VERSION "10.9.1"

NS_ :

BS_:

BU_: ADAS_Info AMP CPD DUMMY_DEBUG DUMMY_ECU EASC HUD MHU XGW_Info

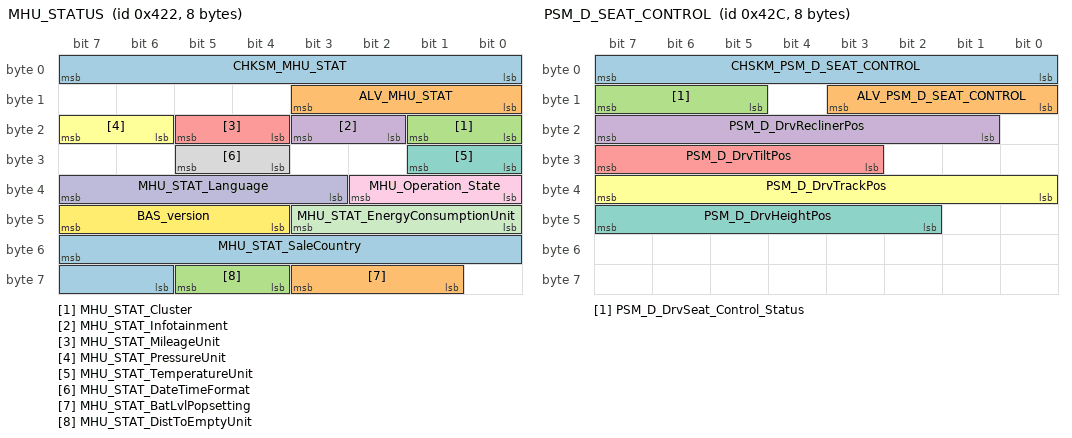
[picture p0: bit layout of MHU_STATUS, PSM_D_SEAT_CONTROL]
BO_ 1058 MHU_STATUS: 8 MHU
  SG_ CHKSM_MHU_STAT : 7|8@0+ (1,0) [0|255] "" ADAS_Info,HUD,XGW_Info
  SG_ ALV_MHU_STAT : 11|4@0+ (1,0) [0|14] "" ADAS_Info,HUD,XGW_Info
  SG_ MHU_STAT_Cluster : 17|2@0+ (1,0) [0|3] "-" ADAS_Info,HUD,XGW_Info
  SG_ MHU_STAT_Infotainment : 19|2@0+ (1,0) [0|3] "" ADAS_Info,HUD,XGW_Info
  SG_ MHU_STAT_MileageUnit : 21|2@0+ (1,0) [0|3] "" ADAS_Info,HUD,XGW_Info
  SG_ MHU_STAT_PressureUnit : 23|2@0+ (1,0) [0|3] "-" HUD,XGW_Info
  SG_ MHU_STAT_TemperatureUnit : 25|2@0+ (1,0) [0|3] "-" HUD,XGW_Info
  SG_ MHU_STAT_DateTimeFormat : 29|2@0+ (1,0) [0|3] "-" HUD,XGW_Info
  SG_ MHU_Operation_State : 34|3@0+ (1,0) [0|7] "" ADAS_Info,HUD,XGW_Info
  SG_ MHU_STAT_Language : 39|5@0+ (1,0) [0|31] "-" HUD,XGW_Info
  SG_ MHU_STAT_EnergyConsumptionUnit : 43|4@0+ (1,0) [0|15] "-" ADAS_Info,HUD,XGW_Info
  SG_ BAS_version : 47|4@0+ (1,0) [0|15] "" XGW_Info
  SG_ MHU_STAT_SaleCountry : 55|10@0+ (1,0) [0|1023] "-" ADAS_Info,HUD,XGW_Info
  SG_ MHU_STAT_BatLvlPopsetting : 59|3@0+ (1,0) [0|7] "-" HUD
  SG_ MHU_STAT_DistToEmptyUnit : 61|2@0+ (1,0) [0|3] "-" HUD

BO_ 1059 AVAS_STATUS: 8 XGW_Info
  SG_ AVAS_BatteryUnderVoltage : 0|1@0+ (1,0) [0|1] "-" MHU
  SG_ AVAS_BatteryOverVoltage : 1|1@0+ (1,0) [0|1] "-" MHU
  SG_ AVAS_VINInfoNotPrgm : 2|1@0+ (1,0) [0|1] "" MHU
  SG_ AVAS_AMPVoltSplDrvOperationFail : 3|1@0+ (1,0) [0|1] "-" MHU
  SG_ AVAS_AMPIntFaultOverCurr : 4|1@0+ (1,0) [0|1] "" MHU
  SG_ AVAS_AMPInternalFaultDCError : 5|1@0+ (1,0) [0|1] "" MHU
  SG_ AVAS_AMPInternalFaultOverTemp : 6|1@0+ (1,0) [0|1] "" MHU
  SG_ AVAS_AMPInternalFaultClockError : 7|1@0+ (1,0) [0|1] "-" MHU
  SG_ AVAS_SpkrMntPwrSwDrvHighFlt : 8|1@0+ (1,0) [0|1] "-" MHU
  SG_ AVAS_SpkrMntPwrSwDrvLowFlt : 9|1@0+ (1,0) [0|1] "-" MHU
  SG_ AVAS_InternalSpeakerOpen : 10|1@0+ (1,0) [0|1] "" MHU
  SG_ AVAS_ECUMalFlshOperationErr : 11|1@0+ (1,0) [0|1] "" MHU
  SG_ AVAS_ECUMalfunctionRamFailure : 12|1@0+ (1,0) [0|1] "-" MHU
  SG_ AVAS_ECUMalEEPROMFailure : 13|1@0+ (1,0) [0|1] "" MHU
  SG_ AVAS_CANBusOff : 14|1@0+ (1,0) [0|1] "-" MHU
  SG_ AVAS_LossCommVehicleSpeed : 15|1@0+ (1,0) [0|1] "" MHU
  SG_ AVAS_LossCommGearPosition : 16|1@0+ (1,0) [0|1] "-" MHU
  SG_ AVAS_LossCommAVASCloseCmd : 17|1@0+ (1,0) [0|1] "-" MHU

BO_ 1068 PSM_D_SEAT_CONTROL: 8 XGW_Info
  SG_ CHSKM_PSM_D_SEAT_CONTROL : 7|8@0+ (1,0) [0|255] "" MHU
  SG_ ALV_PSM_D_SEAT_CONTROL : 11|4@0+ (1,0) [0|14] "" MHU
  SG_ PSM_D_DrvSeat_Control_Status : 15|3@0+ (1,0) [0|7] "" MHU
  SG_ PSM_D_DrvReclinerPos : 23|7@0+ (1,0) [0|127] "degree" MHU
  SG_ PSM_D_DrvTiltPos : 31|5@0+ (1,0) [0|31] "mm" MHU
  SG_ PSM_D_DrvTrackPos : 39|8@0+ (1,0) [0|255] "mm" MHU
  SG_ PSM_D_DrvHeightPos : 47|6@0+ (1,0) [0|63] "mm" MHU

BO_ 1069 XGW_Info_Collect: 3 XGW_Info
  SG_ XGW_WasherFluid_LevelSwitch : 1|2@0+ (1,0) [0|3] "Bit" MHU

BO_ 1070 XGW_HCMInfo: 5 XGW_Info
  SG_ CHKSM_XGW_HCMInfo : 7|8@0+ (1,0) [0|255] "" MHU
  SG_ ALV_XGW_HCMInfo : 11|4@0+ (1,0) [0|14] "" MHU
  SG_ XGW_HLVerLvlMode : 13|2@0+ (1,0) [0|3] "-" MHU
  SG_ XGW_AutoHeadlamp_LvlSts : 15|2@0+ (1,0) [0|3] "-" MHU

BO_ 1073 HUD_ECU_Status: 2 HUD
  SG_ HUD_ECU_Check : 7|8@0+ (1,0) [0|255] "-" XGW_Info
  SG_ HUD_ECU_Fault : 15|8@0+ (1,0) [0|255] "-" XGW_Info

BO_ 1074 MHU_FOTA_STATUS: 8 MHU
  SG_ MHU_FOTA_Checksum : 7|8@0+ (1,0) [0|255] "" AMP,CPD,EASC,HUD,XGW_Info
  SG_ MHU_FOTA_Alive_Counter : 11|4@0+ (1,0) [0|14] "" AMP,CPD,EASC,HUD,XGW_Info
  SG_ MHU_FOTA_State : 15|4@0+ (1,0) [0|14] "-" AMP,CPD,EASC,HUD,XGW_Info
  SG_ MHU_FOTA_Error_Code : 23|8@0+ (1,0) [0|255] "-" AMP,CPD,EASC,HUD,XGW_Info

BO_ 1075 MHU_HEADLAMP_CTL: 2 MHU
  SG_ MHU_Headlamp_Chksm : 7|8@0+ (1,0) [0|255] "-" XGW_Info
  SG_ MHU_Headlamp_Aliv : 11|4@0+ (1,0) [0|14] "-" XGW_Info
  SG_ MHU_HLVerLvlMode : 15|2@0+ (1,0) [0|3] "-" XGW_Info

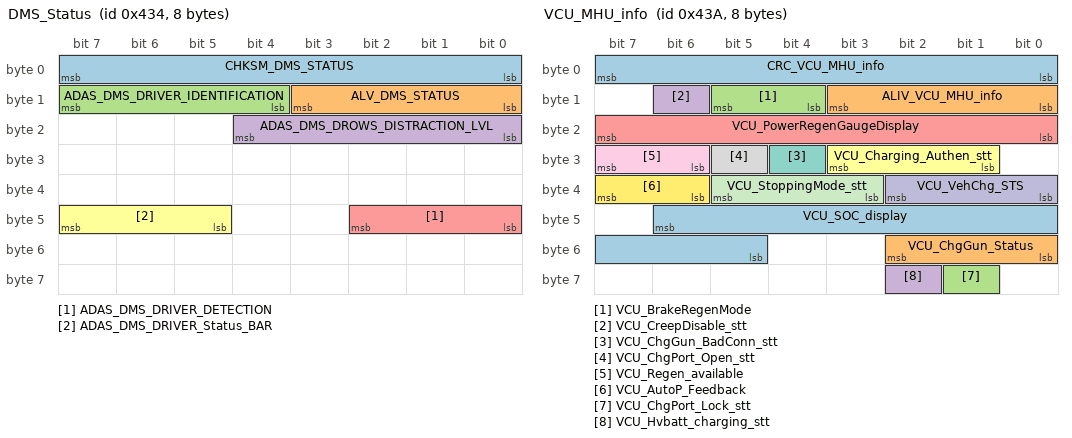
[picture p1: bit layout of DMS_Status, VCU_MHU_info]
BO_ 1076 DMS_Status: 8 ADAS_Info
  SG_ CHKSM_DMS_STATUS : 7|8@0+ (1,0) [0|255] "" HUD,MHU
  SG_ ALV_DMS_STATUS : 11|4@0+ (1,0) [0|14] "" HUD,MHU
  SG_ ADAS_DMS_DRIVER_IDENTIFICATION : 15|4@0+ (1,0) [0|15] "-" HUD,MHU
  SG_ ADAS_DMS_DROWS_DISTRACTION_LVL : 20|5@0+ (1,0) [0|31] "-" HUD,MHU
  SG_ ADAS_DMS_DRIVER_DETECTION : 42|3@0+ (1,0) [0|7] "-" HUD,MHU
  SG_ ADAS_DMS_DRIVER_Status_BAR : 47|3@0+ (1,0) [0|7] "Bit" HUD,MHU

BO_ 1077 BCM_SCM_LIN_Info: 1 XGW_Info
  SG_ BCM_SCM_BC_Button : 1|2@0+ (1,0) [0|3] "-" HUD,MHU

BO_ 1078 MHU_HUD_Info_1: 5 MHU
  SG_ MHU_TELStatus : 2|3@0+ (1,0) [0|7] "-" HUD
  SG_ MHU_MUTEStatus : 4|2@0+ (1,0) [0|3] "-" HUD
  SG_ MHU_TEL_source : 7|3@0+ (1,0) [0|7] "-" HUD
  SG_ SECCAN_HUD_info : 39|8@0+ (1,0) [0|255] "" HUD

BO_ 1079 VCU_MHU_info_2: 8 XGW_Info
  SG_ CRC_VCU_MHU_info_2 : 7|8@0+ (1,0) [0|255] "" MHU
  SG_ ALIV_VCU_MHU_info_2 : 11|4@0+ (1,0) [0|14] "" MHU
  SG_ VCU_Instant_ConsumEnergy : 24|10@0+ (0.1,0) [0|100] "kWh/100km" MHU
  SG_ VCU_Average_ConsumEnergy : 52|10@0+ (0.1,0) [0|100] "kWh/100km" MHU

BO_ 1080 EDS_Error_FR_A: 8 XGW_Info
  SG_ CHKSM_EDS_Error_FR_A : 7|8@0+ (1,0) [0|255] "" MHU
  SG_ ALV_EDS_Error_FR_A : 11|4@0+ (1,0) [0|14] "" MHU
  SG_ EDS_FailNum_ERR_FWD : 23|8@0+ (1,0) [0|255] "" MHU
  SG_ EDS_FailGrade_ERR_FWD : 26|3@0+ (1,0) [0|7] "" MHU
  SG_ EDS_MotOverTempAlarm_FWD : 27|1@0+ (1,0) [0|1] "" MHU
  SG_ EDS_MotOverTempFault_FWD : 28|1@0+ (1,0) [0|1] "" MHU
  SG_ EDS_MotTempSenFault_FWD : 29|1@0+ (1,0) [0|1] "" MHU
  SG_ EDS_EDSOverTempUFault_FWD : 30|1@0+ (1,0) [0|1] "" MHU
  SG_ EDS_EDSOverTempVFault_FWD : 31|1@0+ (1,0) [0|1] "" MHU
  SG_ EDS_EDSOverTempWFault_FWD : 32|1@0+ (1,0) [0|1] "" MHU
  SG_ EDS_EDSOverTempAlarm_FWD : 33|1@0+ (1,0) [0|1] "" MHU
  SG_ EDS_TCoolantOvHi_FWD : 34|1@0+ (1,0) [0|1] "" MHU
  SG_ EDS_EDSTempCmpAlarm_FWD : 35|1@0+ (1,0) [0|1] "" MHU
  SG_ EDS_EDSPhaOvCurentHWFault_FWD : 36|1@0+ (1,0) [0|1] "" MHU
  SG_ EDS_EDSphaOffCalFault_FWD : 37|1@0+ (1,0) [0|1] "" MHU
  SG_ EDS_EDSOverIdcLnkAlarm_FWD : 38|1@0+ (1,0) [0|1] "" MHU
  SG_ EDS_EDSHVOverVoltageAlarm_FWD : 39|1@0+ (1,0) [0|1] "" MHU
  SG_ EDS_EDSHVOverVoltageFault_FWD : 40|1@0+ (1,0) [0|1] "" MHU
  SG_ EDS_EDSHVUnderVoltageAlarm_FWD : 41|1@0+ (1,0) [0|1] "" MHU
  SG_ EDS_EDSHVUnderVoltageFault_FWD : 42|1@0+ (1,0) [0|1] "" MHU
  SG_ EDS_RunToDischaErr_FWD : 43|1@0+ (1,0) [0|1] "" MHU
  SG_ EDS_12VOverVoltageAlarm_FWD : 44|1@0+ (1,0) [0|1] "" MHU
  SG_ EDS_12VUnderVoltageAlarm_FWD : 45|1@0+ (1,0) [0|1] "" MHU
  SG_ EDS_MotOverAlarm_FWD : 46|1@0+ (1,0) [0|1] "" MHU
  SG_ EDS_MotOverFault_FWD : 47|1@0+ (1,0) [0|1] "" MHU
  SG_ EDS_ResolverOffsetAngle_FWD : 48|1@0+ (1,0) [0|1] "" MHU
  SG_ SECCAN_EDS_Error_FR_A : 63|8@0+ (1,0) [0|255] "" MHU

BO_ 1081 EDS_Error_RR_A: 8 XGW_Info
  SG_ CHKSM_EDS_Error_RR_A : 7|8@0+ (1,0) [0|255] "" MHU
  SG_ ALV_EDS_Error_RR_A : 11|4@0+ (1,0) [0|14] "" MHU
  SG_ EDS_FailNum_ERR_RWD : 23|8@0+ (1,0) [0|255] "" MHU
  SG_ EDS_FailGrade_ERR_RWD : 26|3@0+ (1,0) [0|7] "" MHU
  SG_ EDS_MotOverTempAlarm_RWD : 27|1@0+ (1,0) [0|1] "" MHU
  SG_ EDS_MotOverTempFault_RWD : 28|1@0+ (1,0) [0|1] "" MHU
  SG_ EDS_MotTempSenFault_RWD : 29|1@0+ (1,0) [0|1] "" MHU
  SG_ EDS_EDSOverTempUFault_RWD : 30|1@0+ (1,0) [0|1] "" MHU
  SG_ EDS_EDSOverTempVFault_RWD : 31|1@0+ (1,0) [0|1] "" MHU
  SG_ EDS_EDSOverTempWFault_RWD : 32|1@0+ (1,0) [0|1] "" MHU
  SG_ EDS_EDSOverTempAlarm_RWD : 33|1@0+ (1,0) [0|1] "" MHU
  SG_ EDS_TCoolantOvHi_RWD : 34|1@0+ (1,0) [0|1] "" MHU
  SG_ EDS_EDSTempCmpAlarm_RWD : 35|1@0+ (1,0) [0|1] "" MHU
  SG_ EDS_EDSPhaOvCurentHWFault_RWD : 36|1@0+ (1,0) [0|1] "" MHU
  SG_ EDS_EDSphaOffCalFault_RWD : 37|1@0+ (1,0) [0|1] "" MHU
  SG_ EDS_EDSOverIdcLnkAlarm_RWD : 38|1@0+ (1,0) [0|1] "" MHU
  SG_ EDS_EDSHVOverVoltageAlarm_RWD : 39|1@0+ (1,0) [0|1] "" MHU
  SG_ EDS_EDSHVOverVoltageFault_RWD : 40|1@0+ (1,0) [0|1] "" MHU
  SG_ EDS_EDSHVUnderVoltageAlarm_RWD : 41|1@0+ (1,0) [0|1] "" MHU
  SG_ EDS_EDSHVUnderVoltageFault_RWD : 42|1@0+ (1,0) [0|1] "" MHU
  SG_ EDS_RunToDischaErr_RWD : 43|1@0+ (1,0) [0|1] "" MHU
  SG_ EDS_12VOverVoltageAlarm_RWD : 44|1@0+ (1,0) [0|1] "" MHU
  SG_ EDS_12VUnderVoltageAlarm_RWD : 45|1@0+ (1,0) [0|1] "" MHU
  SG_ EDS_MotOverAlarm_RWD : 46|1@0+ (1,0) [0|1] "" MHU
  SG_ EDS_MotOverFault_RWD : 47|1@0+ (1,0) [0|1] "" MHU
  SG_ EDS_ResolverOffsetAngle_RWD : 48|1@0+ (1,0) [0|1] "" MHU
  SG_ SECCAN_EDS_Error_RR_A : 63|8@0+ (1,0) [0|255] "" MHU

BO_ 1082 VCU_MHU_info: 8 XGW_Info
  SG_ CRC_VCU_MHU_info : 7|8@0+ (1,0) [0|255] "" HUD,MHU
  SG_ ALIV_VCU_MHU_info : 11|4@0+ (1,0) [0|14] "" HUD,MHU
  SG_ VCU_BrakeRegenMode : 13|2@0+ (1,0) [0|3] "-" HUD,MHU
  SG_ VCU_CreepDisable_stt : 14|1@0+ (1,0) [0|1] "" HUD,MHU
  SG_ VCU_PowerRegenGaugeDisplay : 23|8@0+ (1,-100) [-100|100] "%" HUD,MHU
  SG_ VCU_Charging_Authen_stt : 27|3@0+ (1,0) [0|7] "-" HUD,MHU
  SG_ VCU_ChgGun_BadConn_stt : 28|1@0+ (1,0) [0|1] "" HUD,MHU
  SG_ VCU_ChgPort_Open_stt : 29|1@0+ (1,0) [0|1] "" HUD,MHU
  SG_ VCU_Regen_available : 31|2@0+ (1,0) [0|3] "" HUD,MHU
  SG_ VCU_VehChg_STS : 34|3@0+ (1,0) [0|7] "" HUD,MHU
  SG_ VCU_StoppingMode_stt : 37|3@0+ (1,0) [0|7] "" MHU
  SG_ VCU_AutoP_Feedback : 39|2@0+ (1,0) [0|3] "" MHU
  SG_ VCU_SOC_display : 46|10@0+ (0.1,0) [0|100] "%" HUD,MHU
  SG_ VCU_ChgGun_Status : 50|3@0+ (1,0) [0|7] "" HUD,MHU
  SG_ VCU_ChgPort_Lock_stt : 57|1@0+ (1,0) [0|1] "" HUD,MHU
  SG_ VCU_Hvbatt_charging_stt : 58|1@0+ (1,0) [0|1] "-" HUD,MHU

BO_ 1083 MHU_SteeringAdjust: 3 MHU
  SG_ MHU_SET_TiltPos : 7|8@0+ (1,0) [0|100] "%" EASC
  SG_ MHU_SET_TelePos : 15|8@0+ (1,0) [0|100] "%" EASC
  SG_ MHU_SET_SteeringAdjust : 23|2@0+ (1,0) [0|3] "-" EASC

BO_ 1084 EASC_Confirm_sts: 3 EASC
  SG_ EASC_TiltPos : 7|8@0+ (1,0) [0|100] "%" MHU
  SG_ EASC_TelePos : 15|8@0+ (1,0) [0|100] "%" MHU
  SG_ EASC_SteeringAdjust : 23|2@0+ (1,0) [0|3] "-" MHU

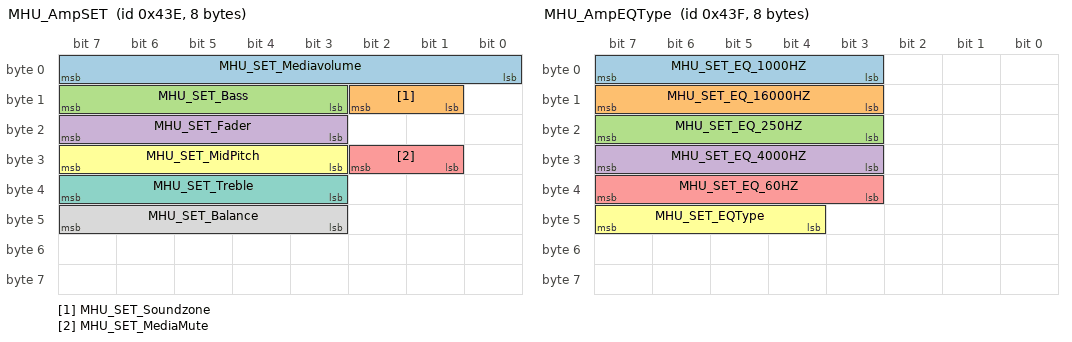
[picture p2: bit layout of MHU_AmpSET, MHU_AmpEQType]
BO_ 1086 MHU_AmpSET: 8 MHU
  SG_ MHU_SET_Mediavolume : 7|8@0+ (1,0) [0|40] "-" AMP
  SG_ MHU_SET_Soundzone : 10|2@0+ (1,0) [0|3] "-" AMP
  SG_ MHU_SET_Bass : 15|5@0+ (1,-6) [-6|6] "-" AMP
  SG_ MHU_SET_Fader : 23|5@0+ (1,-10) [-10|10] "-" AMP
  SG_ MHU_SET_MediaMute : 26|2@0+ (1,0) [1|3] "-" AMP
  SG_ MHU_SET_MidPitch : 31|5@0+ (1,-6) [-6|6] "-" AMP
  SG_ MHU_SET_Treble : 39|5@0+ (1,-6) [-6|6] "-" AMP
  SG_ MHU_SET_Balance : 47|5@0+ (1,-10) [-10|10] "-" AMP

BO_ 1087 MHU_AmpEQType: 8 MHU
  SG_ MHU_SET_EQ_1000HZ : 7|5@0+ (1,-6) [-6|6] "-" AMP
  SG_ MHU_SET_EQ_16000HZ : 15|5@0+ (1,-6) [-6|6] "-" AMP
  SG_ MHU_SET_EQ_250HZ : 23|5@0+ (1,-6) [-6|6] "-" AMP
  SG_ MHU_SET_EQ_4000HZ : 31|5@0+ (1,-6) [-6|6] "-" AMP
  SG_ MHU_SET_EQ_60HZ : 39|5@0+ (1,-6) [-6|6] "-" AMP
  SG_ MHU_SET_EQType : 47|4@0+ (1,0) [0|15] "-" AMP

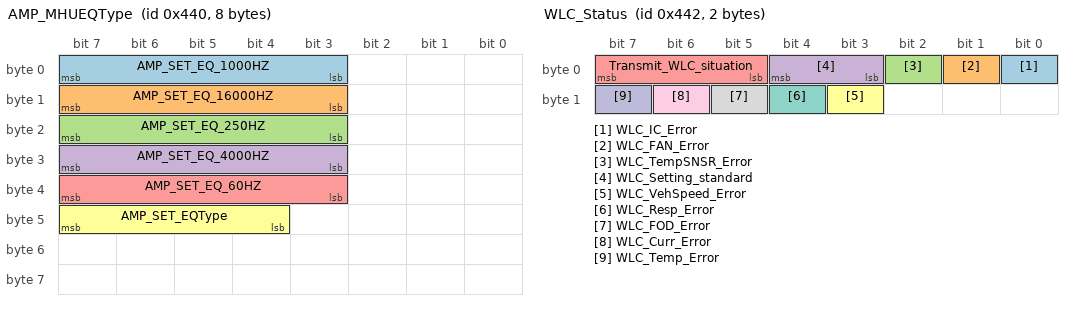
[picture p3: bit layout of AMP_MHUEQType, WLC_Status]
BO_ 1088 AMP_MHUEQType: 8 AMP
  SG_ AMP_SET_EQ_1000HZ : 7|5@0+ (1,-6) [-6|6] "-" MHU
  SG_ AMP_SET_EQ_16000HZ : 15|5@0+ (1,-6) [-6|6] "-" MHU
  SG_ AMP_SET_EQ_250HZ : 23|5@0+ (1,-6) [-6|6] "-" MHU
  SG_ AMP_SET_EQ_4000HZ : 31|5@0+ (1,-6) [-6|6] "-" MHU
  SG_ AMP_SET_EQ_60HZ : 39|5@0+ (1,-6) [-6|6] "-" MHU
  SG_ AMP_SET_EQType : 47|4@0+ (1,0) [0|15] "-" MHU

BO_ 1090 WLC_Status: 2 XGW_Info
  SG_ WLC_IC_Error : 0|1@0+ (1,0) [0|1] "" MHU
  SG_ WLC_FAN_Error : 1|1@0+ (1,0) [0|1] "-" MHU
  SG_ WLC_TempSNSR_Error : 2|1@0+ (1,0) [0|1] "-" MHU
  SG_ WLC_Setting_standard : 4|2@0+ (1,0) [0|3] "-" MHU
  SG_ Transmit_WLC_situation : 7|3@0+ (1,0) [0|7] "" MHU
  SG_ WLC_VehSpeed_Error : 11|1@0+ (1,0) [0|1] "" MHU
  SG_ WLC_Resp_Error : 12|1@0+ (1,0) [0|1] "" MHU
  SG_ WLC_FOD_Error : 13|1@0+ (1,0) [0|1] "-" MHU
  SG_ WLC_Curr_Error : 14|1@0+ (1,0) [0|1] "-" MHU
  SG_ WLC_Temp_Error : 15|1@0+ (1,0) [0|1] "" MHU

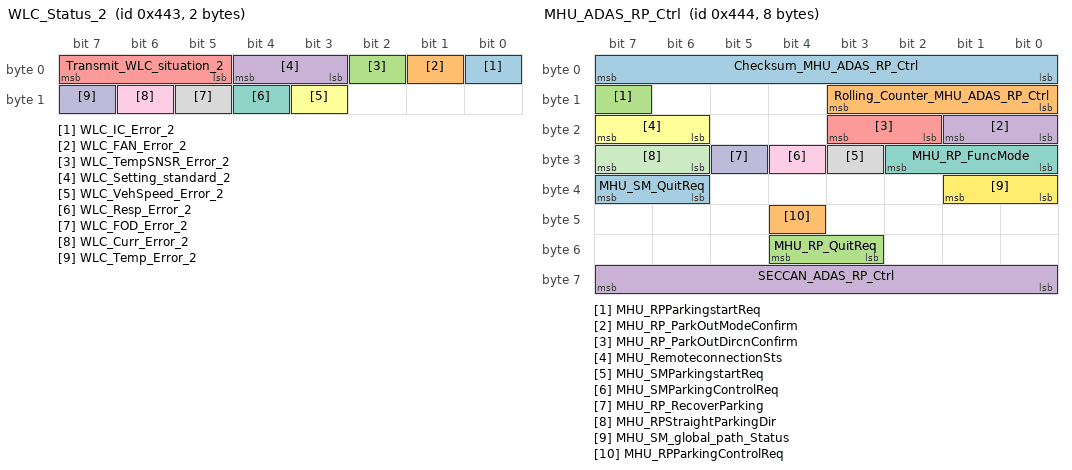
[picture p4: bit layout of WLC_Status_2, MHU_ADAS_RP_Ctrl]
BO_ 1091 WLC_Status_2: 2 XGW_Info
  SG_ WLC_IC_Error_2 : 0|1@0+ (1,0) [0|1] "-" MHU
  SG_ WLC_FAN_Error_2 : 1|1@0+ (1,0) [0|1] "" MHU
  SG_ WLC_TempSNSR_Error_2 : 2|1@0+ (1,0) [0|1] "-" MHU
  SG_ WLC_Setting_standard_2 : 4|2@0+ (1,0) [0|3] "" MHU
  SG_ Transmit_WLC_situation_2 : 7|3@0+ (1,0) [0|7] "" MHU
  SG_ WLC_VehSpeed_Error_2 : 11|1@0+ (1,0) [0|1] "" MHU
  SG_ WLC_Resp_Error_2 : 12|1@0+ (1,0) [0|1] "-" MHU
  SG_ WLC_FOD_Error_2 : 13|1@0+ (1,0) [0|1] "-" MHU
  SG_ WLC_Curr_Error_2 : 14|1@0+ (1,0) [0|1] "-" MHU
  SG_ WLC_Temp_Error_2 : 15|1@0+ (1,0) [0|1] "" MHU

BO_ 1092 MHU_ADAS_RP_Ctrl: 8 MHU
  SG_ Checksum_MHU_ADAS_RP_Ctrl : 7|8@0+ (1,0) [0|255] "" ADAS_Info
  SG_ Rolling_Counter_MHU_ADAS_RP_Ctrl : 11|4@0+ (1,0) [0|14] "" ADAS_Info
  SG_ MHU_RPParkingstartReq : 15|1@0+ (1,0) [0|1] "-" ADAS_Info
  SG_ MHU_RP_ParkOutModeConfirm : 17|2@0+ (1,0) [0|3] "-" ADAS_Info
  SG_ MHU_RP_ParkOutDircnConfirm : 19|2@0+ (1,0) [0|3] "-" ADAS_Info
  SG_ MHU_RemoteconnectionSts : 23|2@0+ (1,0) [0|3] "-" ADAS_Info
  SG_ MHU_RP_FuncMode : 26|3@0+ (1,0) [0|7] "-" ADAS_Info
  SG_ MHU_SMParkingstartReq : 27|1@0+ (1,0) [0|1] "" ADAS_Info
  SG_ MHU_SMParkingControlReq : 28|1@0+ (1,0) [0|1] "" ADAS_Info
  SG_ MHU_RP_RecoverParking : 29|1@0+ (1,0) [0|1] "-" ADAS_Info
  SG_ MHU_RPStraightParkingDir : 31|2@0+ (1,0) [0|3] "-" ADAS_Info
  SG_ MHU_SM_global_path_Status : 33|2@0+ (1,0) [0|3] "" ADAS_Info
  SG_ MHU_SM_QuitReq : 39|2@0+ (1,0) [0|3] "" ADAS_Info
  SG_ MHU_RPParkingControlReq : 44|1@0+ (1,0) [0|1] "-" ADAS_Info
  SG_ MHU_RP_QuitReq : 52|2@0+ (1,0) [0|3] "-" ADAS_Info
  SG_ SECCAN_ADAS_RP_Ctrl : 63|8@0+ (1,0) [0|255] "" ADAS_Info

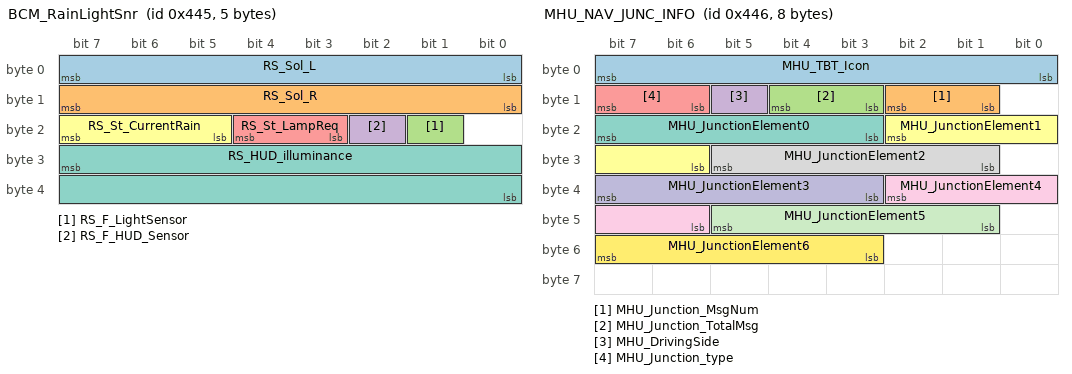
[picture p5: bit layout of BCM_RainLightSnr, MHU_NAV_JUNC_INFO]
BO_ 1093 BCM_RainLightSnr: 5 XGW_Info
  SG_ RS_Sol_L : 7|8@0+ (5,0) [0|1000] "W/m^2" MHU
  SG_ RS_Sol_R : 15|8@0+ (5,0) [0|1000] "W/m^2" MHU
  SG_ RS_F_LightSensor : 17|1@0+ (1,0) [0|1] "" HUD,MHU
  SG_ RS_F_HUD_Sensor : 18|1@0+ (1,0) [0|1] "cd/m2" HUD,MHU
  SG_ RS_St_LampReq : 20|2@0+ (1,0) [0|3] "" MHU
  SG_ RS_St_CurrentRain : 23|3@0+ (1,0) [0|7] "" MHU
  SG_ RS_HUD_illuminance : 31|16@0+ (1,0) [0|10000] "cd/m2" HUD,MHU

BO_ 1094 MHU_NAV_JUNC_INFO: 8 MHU
  SG_ MHU_TBT_Icon : 7|8@0+ (1,0) [0|255] "-" HUD
  SG_ MHU_Junction_MsgNum : 10|2@0+ (1,0) [0|3] "-" HUD
  SG_ MHU_Junction_TotalMsg : 12|2@0+ (1,0) [0|3] "-" HUD
  SG_ MHU_DrivingSide : 13|1@0+ (1,0) [0|1] "-" HUD
  SG_ MHU_Junction_type : 15|2@0+ (1,0) [0|3] "-" HUD
  SG_ MHU_JunctionElement1 : 18|5@0+ (1,0) [0|31] "-" HUD
  SG_ MHU_JunctionElement0 : 23|5@0+ (1,0) [0|31] "-" HUD
  SG_ MHU_JunctionElement2 : 29|5@0+ (1,0) [0|31] "-" HUD
  SG_ MHU_JunctionElement4 : 34|5@0+ (1,0) [0|31] "-" HUD
  SG_ MHU_JunctionElement3 : 39|5@0+ (1,0) [0|31] "-" HUD
  SG_ MHU_JunctionElement5 : 45|5@0+ (1,0) [0|31] "-" HUD
  SG_ MHU_JunctionElement6 : 55|5@0+ (1,0) [0|31] "-" HUD

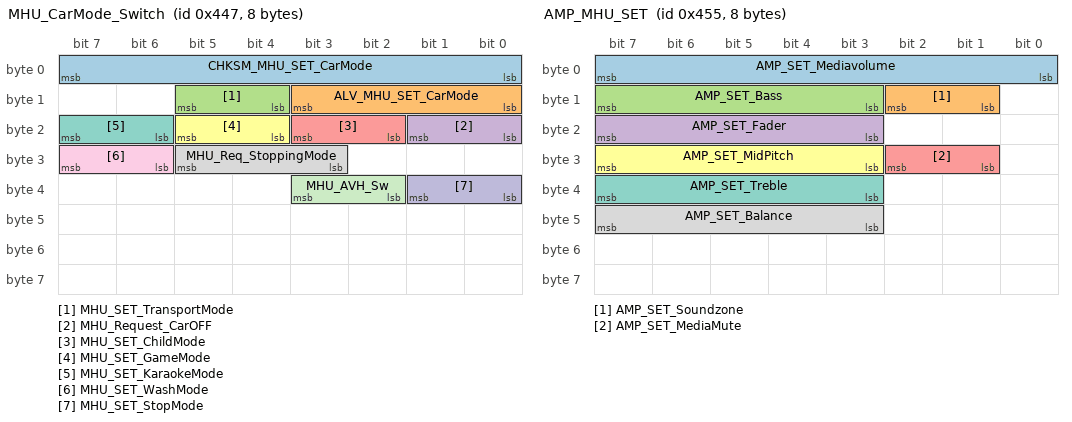
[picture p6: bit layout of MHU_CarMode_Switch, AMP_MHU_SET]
BO_ 1095 MHU_CarMode_Switch: 8 MHU
  SG_ CHKSM_MHU_SET_CarMode : 7|8@0+ (1,0) [0|255] "" XGW_Info
  SG_ ALV_MHU_SET_CarMode : 11|4@0+ (1,0) [0|14] "" XGW_Info
  SG_ MHU_SET_TransportMode : 13|2@0+ (1,0) [0|3] "" XGW_Info
  SG_ MHU_Request_CarOFF : 17|2@0+ (1,0) [0|3] "-" XGW_Info
  SG_ MHU_SET_ChildMode : 19|2@0+ (1,0) [0|3] "" XGW_Info
  SG_ MHU_SET_GameMode : 21|2@0+ (1,0) [0|3] "" XGW_Info
  SG_ MHU_SET_KaraokeMode : 23|2@0+ (1,0) [0|3] "" XGW_Info
  SG_ MHU_Req_StoppingMode : 29|3@0+ (1,0) [0|7] "" XGW_Info
  SG_ MHU_SET_WashMode : 31|2@0+ (1,0) [0|3] "" XGW_Info
  SG_ MHU_SET_StopMode : 33|2@0+ (1,0) [0|3] "" XGW_Info
  SG_ MHU_AVH_Sw : 35|2@0+ (1,0) [0|3] "" XGW_Info

BO_ 1096 EDS_Error_FR_B: 8 XGW_Info
  SG_ CHKSM_EDS_Error_FR_B : 7|8@0+ (1,0) [0|255] "" MHU
  SG_ ALV_EDS_Error_FR_B : 11|4@0+ (1,0) [0|14] "" MHU
  SG_ EDS_iDcLnkOvCLimFail_FWD : 16|1@0+ (1,0) [0|1] "" MHU
  SG_ EDS_MotBlockedFault_FWD : 17|1@0+ (1,0) [0|1] "" MHU
  SG_ EDS_RSLErr_FWD : 18|1@0+ (1,0) [0|1] "" MHU
  SG_ EDS_MotTrqLimFault_FWD : 19|1@0+ (1,0) [0|1] "" MHU
  SG_ EDS_VCUChksumFault_FWD : 20|1@0+ (1,0) [0|1] "" MHU
  SG_ EDS_IGBTFault_FWD : 22|1@0+ (1,0) [0|1] "" MHU
  SG_ EDS_CANBusoffFault_FWD : 23|1@0+ (1,0) [0|1] "" MHU
  SG_ EDS_TDrvBoardOvHiWarn_FWD : 24|1@0+ (1,0) [0|1] "" MHU
  SG_ EDS_TIGBTOvHiFault_FWD : 25|1@0+ (1,0) [0|1] "" MHU
  SG_ EDS_TIGBTOvHiWarn_FWD : 26|1@0+ (1,0) [0|1] "" MHU
  SG_ EDS_IOHWABSampFail_FWD : 27|1@0+ (1,0) [0|1] "" MHU
  SG_ EDS_EDSOpenFault_FWD : 28|1@0+ (1,0) [0|1] "" MHU
  SG_ EDS_MotorOpenFault_FWD : 29|1@0+ (1,0) [0|1] "" MHU
  SG_ EDS_EparkSampFail_FWD : 30|1@0+ (1,0) [0|1] "" MHU
  SG_ EDS_EmacBlkdWarn_FWD : 31|1@0+ (1,0) [0|1] "" MHU
  SG_ EDS_VerMatchFailureErr_FWD : 32|1@0+ (1,0) [0|1] "" MHU
  SG_ EDS_DiashCirNoPsblErr_FWD : 33|1@0+ (1,0) [0|1] "" MHU
  SG_ EDS_OperOutdRngErr_FWD : 34|1@0+ (1,0) [0|1] "" MHU
  SG_ EDS_PhaseLossFaultErr_FWD : 35|1@0+ (1,0) [0|1] "" MHU
  SG_ EDS_CPLDFault_FWD : 36|1@0+ (1,0) [0|1] "" MHU
  SG_ EDS_CPLDFaultBaseSpd_FWD : 37|1@0+ (1,0) [0|1] "" MHU
  SG_ EDS_IOHWABNen33Fail_FWD : 38|1@0+ (1,0) [0|1] "" MHU
  SG_ EDS_HvMcuSlightFault_FWD : 39|1@0+ (1,0) [0|1] "" MHU
  SG_ EDS_HvMcuSevFault_FWD : 40|1@0+ (1,0) [0|1] "" MHU
  SG_ EDS_EDSPhaSampHWFault_FWD : 41|1@0+ (1,0) [0|1] "" MHU
  SG_ EDS_IsOvHiErr_FWD : 42|1@0+ (1,0) [0|1] "" MHU
  SG_ EDS_CanRollingCounterErr_FWD : 43|1@0+ (1,0) [0|1] "" MHU
  SG_ EDS_CanTimeoutErr_FWD : 44|1@0+ (1,0) [0|1] "" MHU
  SG_ EDS_CrashFault_FWD : 45|1@0+ (1,0) [0|1] "" MHU
  SG_ EDS_PCFSlightFault_FWD : 46|1@0+ (1,0) [0|1] "" MHU
  SG_ EDS_PCFSerFault_FWD : 47|1@0+ (1,0) [0|1] "" MHU
  SG_ SECCAN_EDS_Error_FR_B : 63|8@0+ (1,0) [0|255] "" MHU

BO_ 1097 EDS_Error_RR_B: 8 XGW_Info
  SG_ CHKSM_EDS_Error_RR_B : 7|8@0+ (1,0) [0|255] "" MHU
  SG_ ALV_EDS_Error_RR_B : 11|4@0+ (1,0) [0|14] "" MHU
  SG_ EDS_iDcLnkOvCLimFail_RWD : 16|1@0+ (1,0) [0|1] "" MHU
  SG_ EDS_MotBlockedFault_RWD : 17|1@0+ (1,0) [0|1] "" MHU
  SG_ EDS_RSLErr_RWD : 18|1@0+ (1,0) [0|1] "" MHU
  SG_ EDS_MotTrqLimFault_RWD : 19|1@0+ (1,0) [0|1] "" MHU
  SG_ EDS_VCUChksumFault_RWD : 20|1@0+ (1,0) [0|1] "" MHU
  SG_ EDS_IGBTFault_RWD : 22|1@0+ (1,0) [0|1] "" MHU
  SG_ EDS_CANBusoffFault_RWD : 23|1@0+ (1,0) [0|1] "" MHU
  SG_ EDS_TDrvBoardOvHiWarn_RWD : 24|1@0+ (1,0) [0|1] "" MHU
  SG_ EDS_TIGBTOvHiFault_RWD : 25|1@0+ (1,0) [0|1] "" MHU
  SG_ EDS_TIGBTOvHiWarn_RWD : 26|1@0+ (1,0) [0|1] "" MHU
  SG_ EDS_IOHWABSampFail_RWD : 27|1@0+ (1,0) [0|1] "" MHU
  SG_ EDS_EDSOpenFault_RWD : 28|1@0+ (1,0) [0|1] "" MHU
  SG_ EDS_MotorOpenFault_RWD : 29|1@0+ (1,0) [0|1] "" MHU
  SG_ EDS_EparkSampFail_RWD : 30|1@0+ (1,0) [0|1] "" MHU
  SG_ EDS_EmacBlkdWarn_RWD : 31|1@0+ (1,0) [0|1] "" MHU
  SG_ EDS_VerMatchFailureErr_RWD : 32|1@0+ (1,0) [0|1] "" MHU
  SG_ EDS_DiashCirNoPsblErr_RWD : 33|1@0+ (1,0) [0|1] "" MHU
  SG_ EDS_OperOutdRngErr_RWD : 34|1@0+ (1,0) [0|1] "" MHU
  SG_ EDS_PhaseLossFaultErr_RWD : 35|1@0+ (1,0) [0|1] "" MHU
  SG_ EDS_CPLDFault_RWD : 36|1@0+ (1,0) [0|1] "" MHU
  SG_ EDS_CPLDFaultBaseSpd_RWD : 37|1@0+ (1,0) [0|1] "" MHU
  SG_ EDS_IOHWABNen33Fail_RWD : 38|1@0+ (1,0) [0|1] "" MHU
  SG_ EDS_HvMcuSlightFault_RWD : 39|1@0+ (1,0) [0|1] "" MHU
  SG_ EDS_HvMcuSevFault_RWD : 40|1@0+ (1,0) [0|1] "" MHU
  SG_ EDS_EDSPhaSampHWFault_RWD : 41|1@0+ (1,0) [0|1] "" MHU
  SG_ EDS_IsOvHiErr_RWD : 42|1@0+ (1,0) [0|1] "" MHU
  SG_ EDS_CanRollingCounterErr_RWD : 43|1@0+ (1,0) [0|1] "" MHU
  SG_ EDS_CanTimeoutErr_RWD : 44|1@0+ (1,0) [0|1] "" MHU
  SG_ EDS_CrashFault_RWD : 45|1@0+ (1,0) [0|1] "" MHU
  SG_ EDS_PCFSlightFault_RWD : 46|1@0+ (1,0) [0|1] "" MHU
  SG_ EDS_PCFSerFault_RWD : 47|1@0+ (1,0) [0|1] "" MHU
  SG_ SECCAN_EDS_Error_RR_B : 63|8@0+ (1,0) [0|255] "" MHU

BO_ 1104 MHU_WindowSetting: 8 MHU
  SG_ MHU_SET_WindowLifterFrontL : 7|3@0+ (1,0) [0|7] "" XGW_Info
  SG_ MHU_SET_WindowLifterFrontR : 15|3@0+ (1,0) [0|7] "" XGW_Info
  SG_ MHU_SET_WindowLifterRearL : 23|3@0+ (1,0) [0|7] "" XGW_Info
  SG_ MHU_SET_WindowLifterRearR : 31|3@0+ (1,0) [0|7] "" XGW_Info
  SG_ MHU_SET_WindowAutoClose : 39|3@0+ (1,0) [0|3] "" XGW_Info

BO_ 1105 MHU_ADAS_RSSI: 8 MHU
  SG_ Checksum_RSSI : 7|8@0+ (1,0) [0|255] "" ADAS_Info
  SG_ Rolling_Counter_RSSI : 11|4@0+ (1,0) [0|14] "" ADAS_Info
  SG_ RSSI_Value : 23|8@0+ (1,0) [0|255] "" ADAS_Info
  SG_ SECCAN_RSSI : 63|8@0+ (1,0) [0|255] "" ADAS_Info

BO_ 1106 MHU_AMP_Ann1_ModeSET: 8 MHU
  SG_ MHU_SET_ANN1_MODE : 7|2@0+ (1,0) [0|3] "" AMP

BO_ 1107 MHU_AMP_Ann1_PromptsSET: 8 MHU
  SG_ MHU_SET_ANN1_PROMPTS_SPEAKER : 7|3@0+ (1,0) [0|6] "" AMP

BO_ 1108 MHU_AMP_Ann2_SpeakerSET: 8 MHU
  SG_ MHU_SET_ANN2_CEN_Mute : 1|2@0+ (1,0) [0|2] "" AMP
  SG_ MHU_SET_ANN2_RR_Mute : 3|2@0+ (1,0) [0|2] "" AMP
  SG_ MHU_SET_ANN2_RL_Mute : 5|2@0+ (1,0) [0|2] "" AMP
  SG_ MHU_SET_ANN2_FR_Mute : 7|2@0+ (1,0) [0|2] "" AMP
  SG_ MHU_SET_ANN2_FL_Mute : 10|2@0+ (1,0) [0|2] "" AMP

BO_ 1109 AMP_MHU_SET: 8 AMP
  SG_ AMP_SET_Mediavolume : 7|8@0+ (1,0) [0|40] "-" MHU
  SG_ AMP_SET_Soundzone : 10|2@0+ (1,0) [0|3] "-" MHU
  SG_ AMP_SET_Bass : 15|5@0+ (1,-6) [-6|6] "-" MHU
  SG_ AMP_SET_Fader : 23|5@0+ (1,-10) [-10|10] "-" MHU
  SG_ AMP_SET_MediaMute : 26|2@0+ (1,0) [0|3] "-" MHU
  SG_ AMP_SET_MidPitch : 31|5@0+ (1,-6) [-6|6] "-" MHU
  SG_ AMP_SET_Treble : 39|5@0+ (1,-6) [-6|6] "-" MHU
  SG_ AMP_SET_Balance : 47|5@0+ (1,-10) [-10|10] "-" MHU

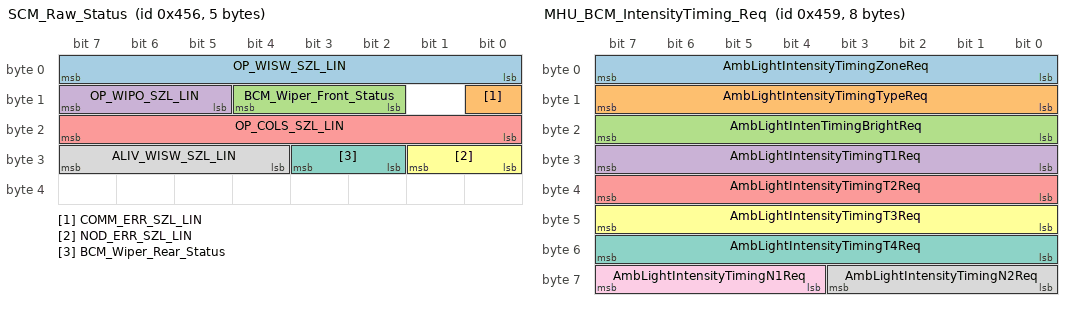
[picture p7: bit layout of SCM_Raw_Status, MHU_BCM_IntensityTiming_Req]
BO_ 1110 SCM_Raw_Status: 5 XGW_Info
  SG_ OP_WISW_SZL_LIN : 7|8@0+ (1,0) [0|255] "" HUD,MHU
  SG_ COMM_ERR_SZL_LIN : 8|1@0+ (1,0) [0|1] "" HUD,MHU
  SG_ BCM_Wiper_Front_Status : 12|3@0+ (1,0) [0|7] "" HUD,MHU
  SG_ OP_WIPO_SZL_LIN : 15|3@0+ (1,0) [0|7] "-" HUD,MHU
  SG_ OP_COLS_SZL_LIN : 23|8@0+ (1,0) [0|255] "-" HUD,MHU
  SG_ NOD_ERR_SZL_LIN : 25|2@0+ (1,0) [0|3] "" HUD,MHU
  SG_ BCM_Wiper_Rear_Status : 27|2@0+ (1,0) [0|3] "" MHU
  SG_ ALIV_WISW_SZL_LIN : 31|4@0+ (1,0) [0|14] "" HUD,MHU

BO_ 1111 BCM_ALM_warning: 1 XGW_Info
  SG_ AmbLight_Error_Z5 : 3|1@0+ (1,0) [0|1] "-" MHU
  SG_ AmbLight_Error_Z4 : 4|1@0+ (1,0) [0|1] "" MHU
  SG_ AmbLight_Error_Z3 : 5|1@0+ (1,0) [0|1] "-" MHU
  SG_ AmbLight_Error_Z2 : 6|1@0+ (1,0) [0|1] "" MHU
  SG_ AmbLight_Error_Z1 : 7|1@0+ (1,0) [0|1] "" MHU

BO_ 1112 MHU_BCM_Color_Req: 8 MHU
  SG_ AmbLightColorZoneReq : 7|8@0+ (1,0) [0|31] "-" XGW_Info
  SG_ AmbLightColorRed : 15|8@0+ (1,0) [0|255] "" XGW_Info
  SG_ AmbLightColorGreen : 23|8@0+ (1,0) [0|255] "-" XGW_Info
  SG_ AmbLightColorBlue : 31|8@0+ (1,0) [0|255] "-" XGW_Info
  SG_ SECCAN_BCM_Clr_Rq : 63|8@0+ (1,0) [0|255] "" XGW_Info

BO_ 1113 MHU_BCM_IntensityTiming_Req: 8 MHU
  SG_ AmbLightIntensityTimingZoneReq : 7|8@0+ (1,0) [0|31] "" XGW_Info
  SG_ AmbLightIntensityTimingTypeReq : 15|8@0+ (1,0) [0|5] "" XGW_Info
  SG_ AmbLightIntenTimingBrightReq : 23|8@0+ (1,0) [0|100] "" XGW_Info
  SG_ AmbLightIntensityTimingT1Req : 31|8@0+ (0.1,0) [0|25.5] "s" XGW_Info
  SG_ AmbLightIntensityTimingT2Req : 39|8@0+ (0.1,0) [0|25.5] "s" XGW_Info
  SG_ AmbLightIntensityTimingT3Req : 47|8@0+ (0.1,0) [0|25.5] "s" XGW_Info
  SG_ AmbLightIntensityTimingT4Req : 55|8@0+ (0.1,0) [0|25.5] "s" XGW_Info
  SG_ AmbLightIntensityTimingN2Req : 59|4@0+ (1,0) [0|15] "-" XGW_Info
  SG_ AmbLightIntensityTimingN1Req : 63|4@0+ (1,0) [0|15] "" XGW_Info

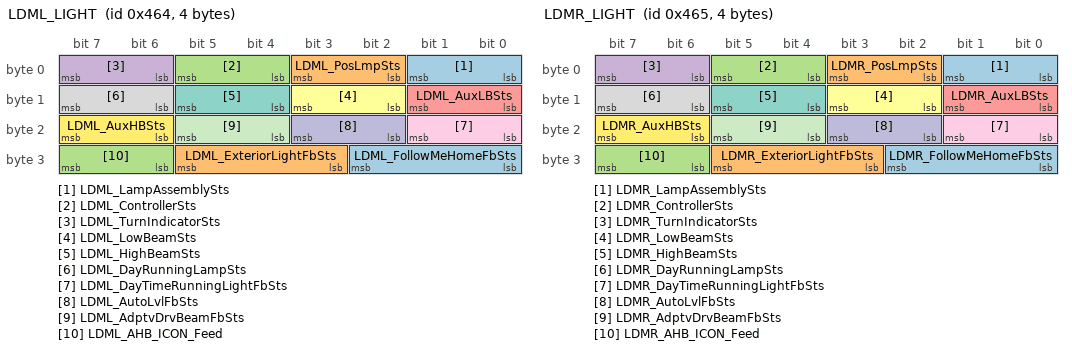
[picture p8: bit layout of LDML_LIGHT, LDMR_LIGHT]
BO_ 1124 LDML_LIGHT: 4 XGW_Info
  SG_ LDML_LampAssemblySts : 1|2@0+ (1,0) [0|3] "-" HUD,MHU
  SG_ LDML_PosLmpSts : 3|2@0+ (1,0) [0|3] "" HUD,MHU
  SG_ LDML_ControllerSts : 5|2@0+ (1,0) [0|3] "" HUD,MHU
  SG_ LDML_TurnIndicatorSts : 7|2@0+ (1,0) [0|3] "" HUD,MHU
  SG_ LDML_AuxLBSts : 9|2@0+ (1,0) [0|3] "-" HUD,MHU
  SG_ LDML_LowBeamSts : 11|2@0+ (1,0) [0|3] "-" HUD,MHU
  SG_ LDML_HighBeamSts : 13|2@0+ (1,0) [0|3] "" HUD,MHU
  SG_ LDML_DayRunningLampSts : 15|2@0+ (1,0) [0|3] "" HUD,MHU
  SG_ LDML_DayTimeRunningLightFbSts : 17|2@0+ (1,0) [0|3] "" HUD,MHU
  SG_ LDML_AutoLvlFbSts : 19|2@0+ (1,0) [0|3] "" HUD,MHU
  SG_ LDML_AdptvDrvBeamFbSts : 21|2@0+ (1,0) [0|3] "-" HUD,MHU
  SG_ LDML_AuxHBSts : 23|2@0+ (1,0) [0|3] "-" HUD,MHU
  SG_ LDML_FollowMeHomeFbSts : 26|3@0+ (1,0) [0|5] "-" HUD,MHU
  SG_ LDML_ExteriorLightFbSts : 29|3@0+ (1,0) [0|4] "-" HUD,MHU
  SG_ LDML_AHB_ICON_Feed : 31|2@0+ (1,0) [0|3] "" HUD,MHU

BO_ 1125 LDMR_LIGHT: 4 XGW_Info
  SG_ LDMR_LampAssemblySts : 1|2@0+ (1,0) [0|3] "" HUD,MHU
  SG_ LDMR_PosLmpSts : 3|2@0+ (1,0) [0|3] "-" HUD,MHU
  SG_ LDMR_ControllerSts : 5|2@0+ (1,0) [0|3] "" HUD,MHU
  SG_ LDMR_TurnIndicatorSts : 7|2@0+ (1,0) [0|3] "-" HUD,MHU
  SG_ LDMR_AuxLBSts : 9|2@0+ (1,0) [0|3] "-" HUD,MHU
  SG_ LDMR_LowBeamSts : 11|2@0+ (1,0) [0|3] "-" HUD,MHU
  SG_ LDMR_HighBeamSts : 13|2@0+ (1,0) [0|3] "" HUD,MHU
  SG_ LDMR_DayRunningLampSts : 15|2@0+ (1,0) [0|3] "" HUD,MHU
  SG_ LDMR_DayTimeRunningLightFbSts : 17|2@0+ (1,0) [0|3] "-" HUD,MHU
  SG_ LDMR_AutoLvlFbSts : 19|2@0+ (1,0) [0|3] "-" HUD,MHU
  SG_ LDMR_AdptvDrvBeamFbSts : 21|2@0+ (1,0) [0|3] "" HUD,MHU
  SG_ LDMR_AuxHBSts : 23|2@0+ (1,0) [0|3] "-" HUD,MHU
  SG_ LDMR_FollowMeHomeFbSts : 26|3@0+ (1,0) [0|5] "" HUD,MHU
  SG_ LDMR_ExteriorLightFbSts : 29|3@0+ (1,0) [0|4] "-" HUD,MHU
  SG_ LDMR_AHB_ICON_Feed : 31|2@0+ (1,0) [0|3] "" HUD,MHU

BO_ 1136 AMP_MHU_Ann1_ModeSET: 8 AMP
  SG_ AMP_SET_ANN1_MODE : 15|2@0+ (1,0) [0|3] "" MHU

BO_ 1137 AMP_MHU_Ann1_PromptsSET: 8 AMP
  SG_ AMP_SET_ANN1_PROMPTS_SPEAKER : 13|3@0+ (1,0) [0|6] "" MHU

BO_ 1138 AMP_MHU_Ann2_SpeakerSET: 8 AMP
  SG_ AMP_SET_ANN2_CEN_Mute : 1|2@0+ (1,0) [0|3] "" MHU
  SG_ AMP_SET_ANN2_RR_Mute : 3|2@0+ (1,0) [0|3] "" MHU
  SG_ AMP_SET_ANN2_RL_Mute : 5|2@0+ (1,0) [0|3] "" MHU
  SG_ AMP_SET_ANN2_FR_Mute : 7|2@0+ (1,0) [0|3] "" MHU
  SG_ AMP_SET_ANN2_FL_Mute : 10|2@0+ (1,0) [0|3] "" MHU

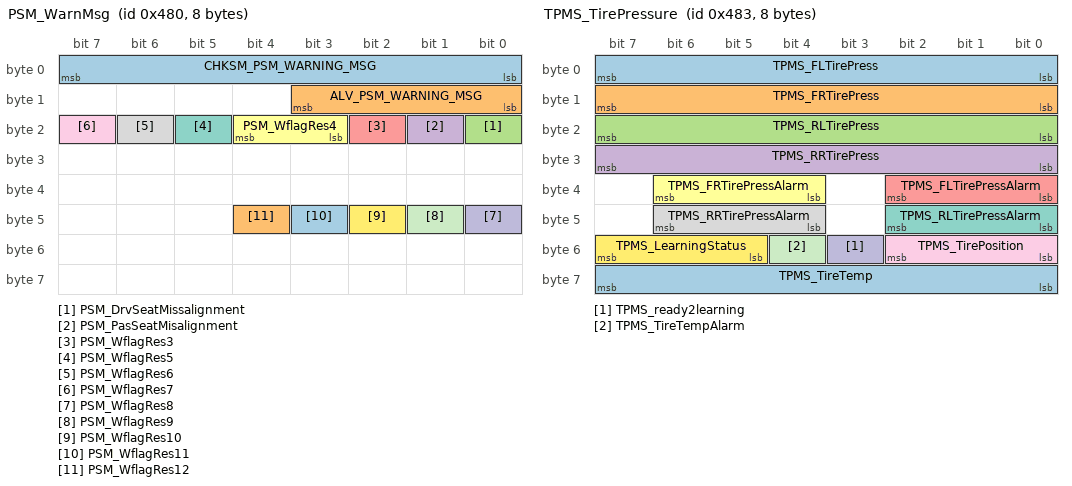
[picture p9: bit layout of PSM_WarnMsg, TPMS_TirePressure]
BO_ 1152 PSM_WarnMsg: 8 XGW_Info
  SG_ CHKSM_PSM_WARNING_MSG : 7|8@0+ (1,0) [0|255] "" MHU
  SG_ ALV_PSM_WARNING_MSG : 11|4@0+ (1,0) [0|14] "" MHU
  SG_ PSM_DrvSeatMissalignment : 16|1@0+ (1,0) [0|1] "" MHU
  SG_ PSM_PasSeatMisalignment : 17|1@0+ (1,0) [0|1] "Bit" MHU
  SG_ PSM_WflagRes3 : 18|1@0+ (1,0) [0|1] "Bit" MHU
  SG_ PSM_WflagRes4 : 20|2@0+ (1,0) [0|3] "Bit" MHU
  SG_ PSM_WflagRes5 : 21|1@0+ (1,0) [0|1] "-" MHU
  SG_ PSM_WflagRes6 : 22|1@0+ (1,0) [0|1] "-" MHU
  SG_ PSM_WflagRes7 : 23|1@0+ (1,0) [0|1] "-" MHU
  SG_ PSM_WflagRes8 : 40|1@0+ (1,0) [0|1] "" MHU
  SG_ PSM_WflagRes9 : 41|1@0+ (1,0) [0|1] "" MHU
  SG_ PSM_WflagRes10 : 42|1@0+ (1,0) [0|1] "-" MHU
  SG_ PSM_WflagRes11 : 43|1@0+ (1,0) [0|1] "-" MHU
  SG_ PSM_WflagRes12 : 44|1@0+ (1,0) [0|1] "-" MHU

BO_ 1153 BCM_WarnMsg: 8 XGW_Info
 SG_ CHSKM_BCM_WarnMsg : 7|8@0+ (1,0) [0|255] "" MHU
 SG_ ALV_BCM_WarnMsg : 11|4@0+ (1,0) [0|14] "" MHU
 SG_ BCM_NoValidKey_1 : 12|1@0+ (1,0) [0|1] "" MHU
 SG_ BCM_SSB_defect : 13|1@0+ (1,0) [0|1] "" MHU
 SG_ BCM_WrongGearPosToStart : 14|1@0+ (1,0) [0|1] "" MHU
 SG_ BCM_NoValidKey_2 : 15|1@0+ (1,0) [0|1] "" MHU
 SG_ BCM_PressBrakeToStart : 16|1@0+ (1,0) [0|1] "" MHU
 SG_ BCM_TurnOffPosLightRemindr : 17|1@0+ (1,0) [0|1] "" MHU
 SG_ BCM_KeyFob_LowBattery : 18|1@0+ (1,0) [0|1] "" MHU
 SG_ BCM_StopLightDefect : 19|1@0+ (1,0) [0|1] "" MHU
 SG_ BCM_LowBeamDefect : 20|1@0+ (1,0) [0|1] "" MHU
 SG_ BCM_HighBeamDefect : 21|1@0+ (1,0) [0|1] "" MHU
 SG_ BCM_PositionLightDefect : 22|1@0+ (1,0) [0|1] "" MHU
 SG_ BCM_CHMLS_Defect : 23|1@0+ (1,0) [0|1] "" MHU
 SG_ BCM_LicencePlateLight_Defect : 24|1@0+ (1,0) [0|1] "" MHU
 SG_ BCM_FrontFog_Defect : 25|1@0+ (1,0) [0|1] "" MHU
 SG_ BCM_RearFog_Defect : 26|1@0+ (1,0) [0|1] "" MHU
 SG_ BCM_ReverseLightDefect : 27|1@0+ (1,0) [0|1] "" MHU
 SG_ BCM_RLS_Malfunction : 28|1@0+ (1,0) [0|1] "" MHU
 SG_ BCM_12VBattery_LowLevel : 29|1@0+ (1,0) [0|1] "" MHU
 SG_ BCM_ForgetKeyFOBInCar : 30|1@0+ (1,0) [0|1] "" MHU
 SG_ BCM_12VBattery_Discharging : 31|1@0+ (1,0) [0|1] "" MHU
 SG_ BCM_TurnIndicatorDefect : 32|1@0+ (1,0) [0|1] "" MHU
 SG_ BCM_dTPMS_Malfunc : 33|1@0+ (1,0) [0|1] "" MHU
 SG_ BCM_dTPMS_Malfunc_LostSensor : 34|1@0+ (1,0) [0|1] "" MHU
 SG_ BCM_dTPMS_LowPressure : 35|1@0+ (1,0) [0|1] "" MHU
 SG_ BCM_dTPMS_RapidLeak : 36|1@0+ (1,0) [0|1] "" MHU
 SG_ BCM_dTPMS_HighTemperature : 37|1@0+ (1,0) [0|1] "" MHU
 SG_ BCM_dTPMS_HighPressure : 38|1@0+ (1,0) [0|1] "" MHU
 SG_ BCM_dTPMS_LowBattery : 39|1@0+ (1,0) [0|1] "" MHU
 SG_ BCM_Keyfob_Leftcar : 40|1@0+ (1,0) [0|1] "" MHU
 SG_ BCM_IDB_Brakelight_Malfunction : 41|1@0+ (1,0) [0|1] "" MHU
 SG_ BCM_VCU_Brakelight_Malfunction : 42|1@0+ (1,0) [0|1] "" MHU
 SG_ BCM_ADAS_Turnlight_Malfunction : 43|1@0+ (1,0) [0|1] "" MHU
 SG_ BCM_ADAS_Highbeam_Malfunction : 44|1@0+ (1,0) [0|1] "" MHU
 SG_ BCM_ADAS_LowBeam_Malfunction : 45|1@0+ (1,0) [0|1] "" MHU
 SG_ BCM_MHU_Malfunction : 46|1@0+ (1,0) [0|1] "" MHU
 SG_ BCM_BCM_Malfunction : 47|1@0+ (1,0) [0|1] "" MHU
 SG_ BCM_SCM_Malfunction : 48|1@0+ (1,0) [0|1] "" MHU
 SG_ BCM_CrashSignalDefect : 49|1@0+ (1,0) [0|1] "" MHU
 SG_ BCM_FrontWiperDefect : 51|1@0+ (1,0) [0|1] "" MHU
 SG_ BCM_Rear_RightDoorLockDefect : 52|1@0+ (1,0) [0|1] "" MHU
 SG_ BCM_RearLeftDoorLockDefect : 53|1@0+ (1,0) [0|1] "" MHU
 SG_ BCM_Front_RightDoorLockDefect : 54|1@0+ (1,0) [0|1] "" MHU
 SG_ BCM_FrontLeftDoorLockDefect : 55|1@0+ (1,0) [0|1] "" MHU
 SG_ BCM_LDML_Malfunction : 56|1@0+ (1,0) [0|1] "" MHU
 SG_ BCM_LDMR_Malfunction : 57|1@0+ (1,0) [0|1] "" MHU
 SG_ BCM_RLBL_Malfunction : 58|1@0+ (1,0) [0|1] "" MHU
 SG_ BCM_RLBR_Malfunction : 59|1@0+ (1,0) [0|1] "" MHU
 SG_ BCM_RLT_Malfunction : 60|1@0+ (1,0) [0|1] "" MHU
 SG_ BCM_BCM_POWER_Malfunction : 61|1@0+ (1,0) [0|1] "" MHU
 SG_ BCM_IDB_AutoHazardBlinking_Malf : 62|1@0+ (1,0) [0|1] "" MHU

BO_ 1154 XGW_WarnMsg: 8 XGW_Info
  SG_ CHSKM_XGW_WarnMsg : 7|8@0+ (1,0) [0|255] "" MHU
  SG_ ALV_XGW_WarnMsg : 11|4@0+ (1,0) [0|14] "" MHU
  SG_ XGW_AutoHLLevelingFault : 12|1@0+ (1,0) [0|1] "-" MHU
  SG_ XGW_WasherFluidLvlSw : 13|1@0+ (1,0) [0|1] "-" MHU
  SG_ XGW_Warning_Flag_3 : 14|1@0+ (1,0) [0|1] "-" MHU
  SG_ XGW_Warning_Flag_4 : 15|1@0+ (1,0) [0|1] "-" MHU
  SG_ XGW_Warning_Flag_5 : 16|1@0+ (1,0) [0|1] "-" MHU
  SG_ XGW_Warning_Flag_6 : 17|1@0+ (1,0) [0|1] "-" MHU
  SG_ XGW_Warning_Flag_7 : 18|1@0+ (1,0) [0|1] "-" MHU
  SG_ XGW_Warning_Flag_8 : 19|1@0+ (1,0) [0|1] "-" MHU
  SG_ XGW_Warning_Flag_9 : 20|1@0+ (1,0) [0|1] "-" MHU
  SG_ XGW_Warning_Flag_10 : 21|1@0+ (1,0) [0|1] "-" MHU
  SG_ XGW_Warning_Flag_11 : 22|1@0+ (1,0) [0|1] "-" MHU
  SG_ XGW_Warning_Flag_12 : 23|1@0+ (1,0) [0|1] "-" MHU
  SG_ XGW_Reserved_signal1 : 31|8@0+ (1,0) [0|255] "-" MHU
  SG_ XGW_Reserved_signal2 : 39|8@0+ (1,0) [0|255] "-" MHU
  SG_ XGW_Reserved_signal3 : 47|8@0+ (1,0) [0|255] "-" MHU
  SG_ XGW_Reserved_signal4 : 55|8@0+ (1,0) [0|255] "-" MHU
  SG_ XGW_Reserved_signal5 : 63|8@0+ (1,0) [0|255] "-" MHU

BO_ 1155 TPMS_TirePressure: 8 XGW_Info
  SG_ TPMS_FLTirePress : 7|8@0+ (1.373,0) [0|350] "kPa" MHU
  SG_ TPMS_FRTirePress : 15|8@0+ (1.373,0) [0|350] "kPa" MHU
  SG_ TPMS_RLTirePress : 23|8@0+ (1.373,0) [0|350] "kPa" MHU
  SG_ TPMS_RRTirePress : 31|8@0+ (1.373,0) [0|350] "kPa" MHU
  SG_ TPMS_FLTirePressAlarm : 34|3@0+ (1,0) [0|7] "" MHU
  SG_ TPMS_FRTirePressAlarm : 38|3@0+ (1,0) [0|7] "-" MHU
  SG_ TPMS_RLTirePressAlarm : 42|3@0+ (1,0) [0|7] "" MHU
  SG_ TPMS_RRTirePressAlarm : 46|3@0+ (1,0) [0|7] "" MHU
  SG_ TPMS_TirePosition : 50|3@0+ (1,0) [0|7] "-" MHU
  SG_ TPMS_ready2learning : 51|1@0+ (1,0) [0|1] "-" MHU
  SG_ TPMS_TireTempAlarm : 52|1@0+ (1,0) [0|1] "-" MHU
  SG_ TPMS_LearningStatus : 55|3@0+ (1,0) [0|7] "-" MHU
  SG_ TPMS_TireTemp : 63|8@0+ (1,-40) [-40|215] "Degree C" MHU

BO_ 1156 APA_FEEDBACK_MHU: 8 ADAS_Info
  SG_ CHKSM_APA_FEEDBACK_MHU : 7|8@0+ (1,0) [0|255] "" MHU
  SG_ ALV_APA_FEEDBACK_MHU : 11|4@0+ (1,0) [0|14] "" MHU
  SG_ APA_ReqInfoDispTxt3 : 19|5@0+ (1,0) [0|31] "-" MHU
  SG_ APA_ParkOutDircnDisReq : 20|1@0+ (1,0) [0|1] "-" MHU
  SG_ APA_ParkOutModeDisReq : 21|1@0+ (1,0) [0|1] "-" MHU
  SG_ APA_MHU_DisplaystartbuttonReq : 23|2@0+ (1,0) [0|3] "-" MHU
  SG_ APA_ReqInfoDispTxt4 : 27|4@0+ (1,0) [0|15] "-" MHU
  SG_ APA_ReqInfoDispTxt2 : 30|3@0+ (1,0) [0|7] "-" MHU
  SG_ APA_ReqInfoDispTxt1 : 34|3@0+ (1,0) [0|7] "-" MHU
  SG_ APA_MHU_Displayparkingtype : 35|1@0+ (1,0) [0|1] "-" MHU
  SG_ APA_ShowAPAFdbck : 37|2@0+ (1,0) [0|3] "-" MHU
  SG_ APA_FuncModeFdbck : 39|2@0+ (1,0) [0|3] "-" MHU
  SG_ APA_MHU_DisplayrecoverbuttonReq : 44|1@0+ (1,0) [0|1] "-" MHU
  SG_ APA_SysSoundIndication : 47|3@0+ (1,0) [0|7] "-" MHU
  SG_ APA_RecommendSlotID : 51|8@0+ (1,0) [0|255] "-" MHU
  SG_ APA_Currentfunction : 54|3@0+ (1,0) [0|7] "-" MHU
  SG_ APA_MHU_Status : 59|3@0+ (1,0) [0|7] "-" MHU

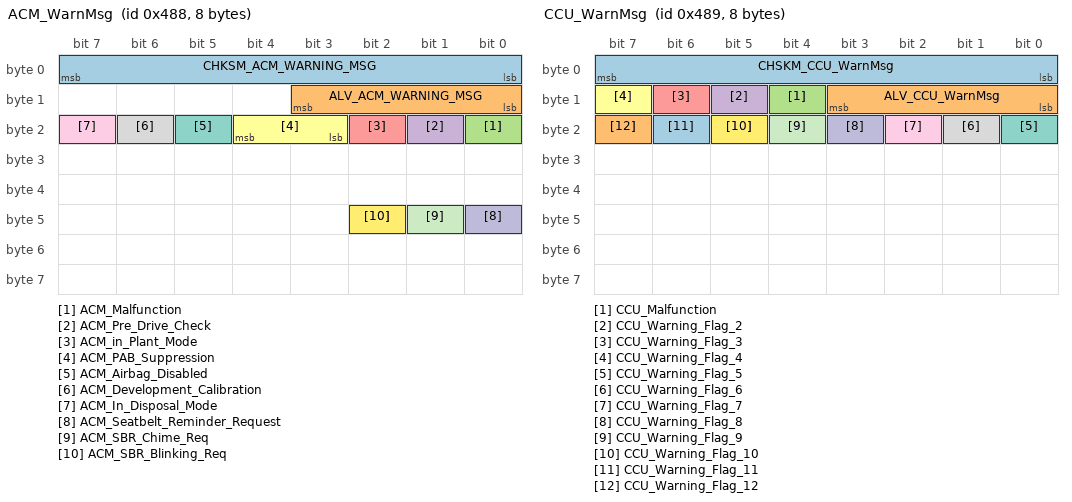
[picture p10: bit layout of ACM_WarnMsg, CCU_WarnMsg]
BO_ 1160 ACM_WarnMsg: 8 XGW_Info
  SG_ CHKSM_ACM_WARNING_MSG : 7|8@0+ (1,0) [0|255] "" MHU
  SG_ ALV_ACM_WARNING_MSG : 11|4@0+ (1,0) [0|14] "" MHU
  SG_ ACM_Malfunction : 16|1@0+ (1,0) [0|1] "" MHU
  SG_ ACM_Pre_Drive_Check : 17|1@0+ (1,0) [0|1] "Bit" MHU
  SG_ ACM_in_Plant_Mode : 18|1@0+ (1,0) [0|1] "Bit" MHU
  SG_ ACM_PAB_Suppression : 20|2@0+ (1,0) [0|3] "Bit" MHU
  SG_ ACM_Airbag_Disabled : 21|1@0+ (1,0) [0|1] "-" MHU
  SG_ ACM_Development_Calibration : 22|1@0+ (1,0) [0|1] "-" MHU
  SG_ ACM_In_Disposal_Mode : 23|1@0+ (1,0) [0|1] "" MHU
  SG_ ACM_Seatbelt_Reminder_Request : 40|1@0+ (1,0) [0|1] "-" MHU
  SG_ ACM_SBR_Chime_Req : 41|1@0+ (1,0) [0|1] "" MHU
  SG_ ACM_SBR_Blinking_Req : 42|1@0+ (1,0) [0|1] "" MHU

BO_ 1161 CCU_WarnMsg: 8 XGW_Info
  SG_ CHSKM_CCU_WarnMsg : 7|8@0+ (1,0) [0|255] "" MHU
  SG_ ALV_CCU_WarnMsg : 11|4@0+ (1,0) [0|14] "" MHU
  SG_ CCU_Malfunction : 12|1@0+ (1,0) [0|1] "" MHU
  SG_ CCU_Warning_Flag_2 : 13|1@0+ (1,0) [0|1] "-" MHU
  SG_ CCU_Warning_Flag_3 : 14|1@0+ (1,0) [0|1] "" MHU
  SG_ CCU_Warning_Flag_4 : 15|1@0+ (1,0) [0|1] "-" MHU
  SG_ CCU_Warning_Flag_5 : 16|1@0+ (1,0) [0|1] "-" MHU
  SG_ CCU_Warning_Flag_6 : 17|1@0+ (1,0) [0|1] "-" MHU
  SG_ CCU_Warning_Flag_7 : 18|1@0+ (1,0) [0|1] "-" MHU
  SG_ CCU_Warning_Flag_8 : 19|1@0+ (1,0) [0|1] "" MHU
  SG_ CCU_Warning_Flag_9 : 20|1@0+ (1,0) [0|1] "" MHU
  SG_ CCU_Warning_Flag_10 : 21|1@0+ (1,0) [0|1] "" MHU
  SG_ CCU_Warning_Flag_11 : 22|1@0+ (1,0) [0|1] "" MHU
  SG_ CCU_Warning_Flag_12 : 23|1@0+ (1,0) [0|1] "" MHU

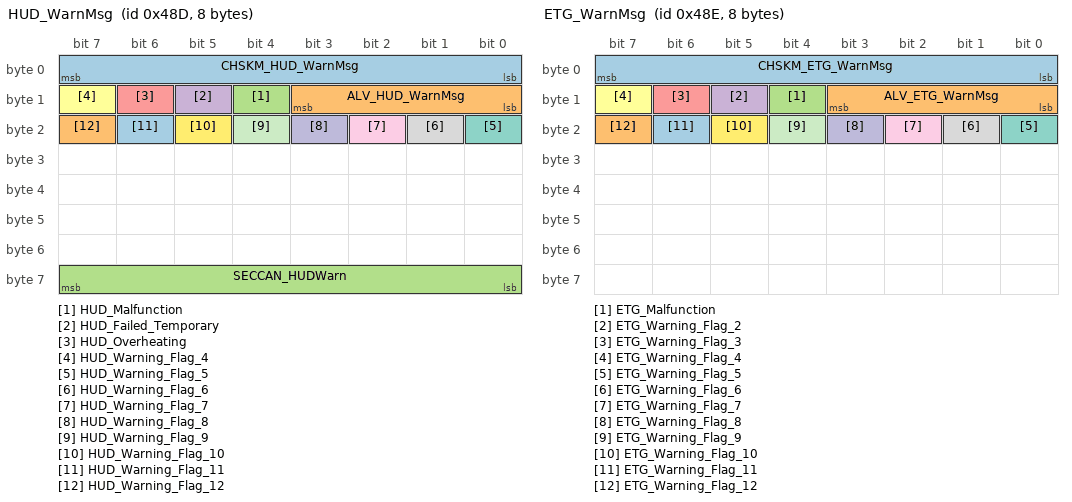
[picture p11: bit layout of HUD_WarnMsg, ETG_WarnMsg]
BO_ 1165 HUD_WarnMsg: 8 HUD
  SG_ CHSKM_HUD_WarnMsg : 7|8@0+ (1,0) [0|255] "" MHU
  SG_ ALV_HUD_WarnMsg : 11|4@0+ (1,0) [0|14] "" MHU
  SG_ HUD_Malfunction : 12|1@0+ (1,0) [0|1] "-" MHU
  SG_ HUD_Failed_Temporary : 13|1@0+ (1,0) [0|1] "-" MHU
  SG_ HUD_Overheating : 14|1@0+ (1,0) [0|1] "-" MHU
  SG_ HUD_Warning_Flag_4 : 15|1@0+ (1,0) [0|1] "-" MHU
  SG_ HUD_Warning_Flag_5 : 16|1@0+ (1,0) [0|1] "-" MHU
  SG_ HUD_Warning_Flag_6 : 17|1@0+ (1,0) [0|1] "-" MHU
  SG_ HUD_Warning_Flag_7 : 18|1@0+ (1,0) [0|1] "-" MHU
  SG_ HUD_Warning_Flag_8 : 19|1@0+ (1,0) [0|1] "-" MHU
  SG_ HUD_Warning_Flag_9 : 20|1@0+ (1,0) [0|1] "-" MHU
  SG_ HUD_Warning_Flag_10 : 21|1@0+ (1,0) [0|1] "-" MHU
  SG_ HUD_Warning_Flag_11 : 22|1@0+ (1,0) [0|1] "-" MHU
  SG_ HUD_Warning_Flag_12 : 23|1@0+ (1,0) [0|1] "-" MHU
  SG_ SECCAN_HUDWarn : 63|8@0+ (1,0) [0|255] "" MHU

BO_ 1166 ETG_WarnMsg: 8 XGW_Info
  SG_ CHSKM_ETG_WarnMsg : 7|8@0+ (1,0) [0|255] "" MHU
  SG_ ALV_ETG_WarnMsg : 11|4@0+ (1,0) [0|14] "" MHU
  SG_ ETG_Malfunction : 12|1@0+ (1,0) [0|1] "-" MHU
  SG_ ETG_Warning_Flag_2 : 13|1@0+ (1,0) [0|1] "-" MHU
  SG_ ETG_Warning_Flag_3 : 14|1@0+ (1,0) [0|1] "" MHU
  SG_ ETG_Warning_Flag_4 : 15|1@0+ (1,0) [0|1] "" MHU
  SG_ ETG_Warning_Flag_5 : 16|1@0+ (1,0) [0|1] "-" MHU
  SG_ ETG_Warning_Flag_6 : 17|1@0+ (1,0) [0|1] "-" MHU
  SG_ ETG_Warning_Flag_7 : 18|1@0+ (1,0) [0|1] "-" MHU
  SG_ ETG_Warning_Flag_8 : 19|1@0+ (1,0) [0|1] "" MHU
  SG_ ETG_Warning_Flag_9 : 20|1@0+ (1,0) [0|1] "" MHU
  SG_ ETG_Warning_Flag_10 : 21|1@0+ (1,0) [0|1] "" MHU
  SG_ ETG_Warning_Flag_11 : 22|1@0+ (1,0) [0|1] "-" MHU
  SG_ ETG_Warning_Flag_12 : 23|1@0+ (1,0) [0|1] "" MHU

BO_ 1168 GS_WarnMsg: 8 XGW_Info
  SG_ CHSKM_GS_WarnMsg : 7|8@0+ (1,0) [0|255] "" MHU
  SG_ ALV_GS_WarnMsg : 11|4@0+ (1,0) [0|14] "" MHU
  SG_ GS_Warning_Flag_1 : 12|1@0+ (1,0) [0|1] "" MHU
  SG_ GS_Warning_Flag_2 : 13|1@0+ (1,0) [0|1] "" MHU
  SG_ GS_Warning_Flag_3 : 14|1@0+ (1,0) [0|1] "-" MHU
  SG_ GS_Warning_Flag_4 : 15|1@0+ (1,0) [0|1] "-" MHU
  SG_ GS_Warning_Flag_5 : 16|1@0+ (1,0) [0|1] "" MHU
  SG_ GS_Warning_Flag_6 : 17|1@0+ (1,0) [0|1] "-" MHU
  SG_ GS_Warning_Flag_7 : 18|1@0+ (1,0) [0|1] "" MHU
  SG_ GS_Warning_Flag_8 : 19|1@0+ (1,0) [0|1] "" MHU
  SG_ GS_Warning_Flag_9 : 20|1@0+ (1,0) [0|1] "-" MHU
  SG_ GS_Warning_Flag_10 : 21|1@0+ (1,0) [0|1] "-" MHU
  SG_ GS_Warning_Flag_11 : 22|1@0+ (1,0) [0|1] "" MHU
  SG_ GS_Warning_Flag_12 : 23|1@0+ (1,0) [0|1] "" MHU
  SG_ GS_Reserved_signal1 : 31|8@0+ (1,0) [0|255] "-" MHU
  SG_ GS_Reserved_signal2 : 39|8@0+ (1,0) [0|255] "" MHU
  SG_ GS_Reserved_signal3 : 47|8@0+ (1,0) [0|255] "" MHU
  SG_ GS_Reserved_signal4 : 55|8@0+ (1,0) [0|255] "-" MHU
  SG_ GS_Reserved_signal5 : 63|8@0+ (1,0) [0|255] "" MHU

BO_ 1171 BMS_WarnMsg: 8 XGW_Info
  SG_ CHSKM_BMS_WarnMsg : 7|8@0+ (1,0) [0|255] "" HUD,MHU
  SG_ ALV_BMS_WarnMsg : 11|4@0+ (1,0) [0|14] "" HUD,MHU
  SG_ BMS_PackTempSts : 13|2@0+ (1,0) [0|3] "" MHU
  SG_ BMS_ThermalRunaway : 14|1@0+ (1,0) [0|1] "" HUD,MHU
  SG_ BMS_BatteryReplacement : 15|1@0+ (1,0) [0|1] "" MHU
  SG_ BMS_Warning_PowerDegrade : 16|1@0+ (1,0) [0|1] "" MHU
  SG_ BMS_Warning_DeltaSoC : 17|1@0+ (1,0) [0|1] "" MHU
  SG_ BMS_Warning_HVILSts : 18|1@0+ (1,0) [0|1] "" MHU
  SG_ BMS_Warning_Isolation : 19|1@0+ (1,0) [0|1] "" MHU
  SG_ BMS_Warning_CoolantLeakage : 20|1@0+ (1,0) [0|1] "" MHU
  SG_ BMS_MalfunctionSts : 21|1@0+ (1,0) [0|1] "" MHU
  SG_ BMS_LowBattery : 23|2@0+ (1,0) [0|3] "" HUD,MHU
  SG_ BMS_Warning_DeltaTemperature : 31|8@0+ (1,0) [0|255] "" MHU
  SG_ BMS_Warning_BDUTemperatureSts : 39|8@0+ (1,0) [0|255] "" MHU
  SG_ BMS_Warning_Contactor_Aging : 47|1@0+ (1,0) [0|1] "" MHU
  SG_ BMS_Reserved_signal4 : 55|8@0+ (1,0) [0|255] "" MHU
  SG_ BMS_Reserved_signal5 : 63|8@0+ (1,0) [0|255] "" MHU

BO_ 1178 EDS_R_WarnMsg: 8 XGW_Info
  SG_ CHSKM_EDS_R_WarnMsg : 7|8@0+ (1,0) [0|255] "" MHU
  SG_ ALV_EDS_R_WarnMsg : 11|4@0+ (1,0) [0|14] "" MHU
  SG_ EDS_R_Error_1 : 12|1@0+ (1,0) [0|1] "-" MHU
  SG_ EDS_R_Error_2 : 13|1@0+ (1,0) [0|1] "-" MHU
  SG_ EDS_R_Error_3 : 14|1@0+ (1,0) [0|1] "-" MHU
  SG_ EDS_R_Error_4 : 15|1@0+ (1,0) [0|1] "-" MHU
  SG_ EDS_R_Error_5 : 16|1@0+ (1,0) [0|1] "-" MHU
  SG_ EDS_R_Error_6 : 17|1@0+ (1,0) [0|1] "-" MHU
  SG_ EDS_R_Error_7 : 18|1@0+ (1,0) [0|1] "-" MHU
  SG_ EDS_R_Error_8 : 19|1@0+ (1,0) [0|1] "-" MHU
  SG_ EDS_R_Error_9 : 20|1@0+ (1,0) [0|1] "-" MHU
  SG_ EDS_R_Error_10 : 21|1@0+ (1,0) [0|1] "-" MHU
  SG_ EDS_R_Error_11 : 22|1@0+ (1,0) [0|1] "-" MHU
  SG_ EDS_R_Error_12 : 23|1@0+ (1,0) [0|1] "-" MHU
  SG_ EDS_R_Error_13 : 24|1@0+ (1,0) [0|1] "-" MHU
  SG_ EDS_R_Error_14 : 25|1@0+ (1,0) [0|1] "-" MHU
  SG_ EDS_R_Error_15 : 26|1@0+ (1,0) [0|1] "-" MHU
  SG_ EDS_R_Error_16 : 27|1@0+ (1,0) [0|1] "-" MHU
  SG_ EDS_R_Error_17 : 28|1@0+ (1,0) [0|1] "-" MHU
  SG_ EDS_R_Error_18 : 29|1@0+ (1,0) [0|1] "-" MHU
  SG_ EDS_R_Error_19 : 30|1@0+ (1,0) [0|1] "-" MHU
  SG_ EDS_R_Error_20 : 31|1@0+ (1,0) [0|1] "-" MHU
  SG_ EDS_R_Error_21 : 32|1@0+ (1,0) [0|1] "-" MHU
  SG_ EDS_R_Error_22 : 33|1@0+ (1,0) [0|1] "-" MHU
  SG_ EDS_R_Error_23 : 34|1@0+ (1,0) [0|1] "-" MHU
  SG_ EDS_R_Error_24 : 35|1@0+ (1,0) [0|1] "-" MHU
  SG_ EDS_R_Error_25 : 36|1@0+ (1,0) [0|1] "-" MHU
  SG_ EDS_R_Error_26 : 37|1@0+ (1,0) [0|1] "-" MHU
  SG_ EDS_R_Error_27 : 38|1@0+ (1,0) [0|1] "-" MHU
  SG_ EDS_R_Error_28 : 39|1@0+ (1,0) [0|1] "-" MHU
  SG_ EDS_R_Error_29 : 40|1@0+ (1,0) [0|1] "-" MHU
  SG_ EDS_R_Error_30 : 41|1@0+ (1,0) [0|1] "-" MHU
  SG_ EDS_R_Error_31 : 42|1@0+ (1,0) [0|1] "-" MHU
  SG_ EDS_R_Error_32 : 43|1@0+ (1,0) [0|1] "-" MHU
  SG_ EDS_R_Error_33 : 44|1@0+ (1,0) [0|1] "-" MHU
  SG_ EDS_R_Error_34 : 45|1@0+ (1,0) [0|1] "-" MHU
  SG_ EDS_R_Error_35 : 46|1@0+ (1,0) [0|1] "-" MHU
  SG_ EDS_R_Error_36 : 47|1@0+ (1,0) [0|1] "-" MHU
  SG_ EDS_R_Error_37 : 48|1@0+ (1,0) [0|1] "-" MHU
  SG_ EDS_R_Error_38 : 49|1@0+ (1,0) [0|1] "-" MHU
  SG_ EDS_R_Error_39 : 50|1@0+ (1,0) [0|1] "-" MHU
  SG_ EDS_R_Error_40 : 51|1@0+ (1,0) [0|1] "-" MHU
  SG_ EDS_R_Error_41 : 52|1@0+ (1,0) [0|1] "-" MHU
  SG_ EDS_R_Error_42 : 53|1@0+ (1,0) [0|1] "-" MHU
  SG_ EDS_R_Error_43 : 54|1@0+ (1,0) [0|1] "-" MHU
  SG_ EDS_R_Error_44 : 55|1@0+ (1,0) [0|1] "-" MHU
  SG_ EDS_R_Error_45 : 56|1@0+ (1,0) [0|1] "-" MHU
  SG_ EDS_R_Error_46 : 57|1@0+ (1,0) [0|1] "-" MHU
  SG_ EDS_R_Error_47 : 58|1@0+ (1,0) [0|1] "-" MHU
  SG_ EDS_R_Error_48 : 59|1@0+ (1,0) [0|1] "-" MHU
  SG_ EDS_R_Error_49 : 60|1@0+ (1,0) [0|1] "-" MHU
  SG_ EDS_R_Error_50 : 61|1@0+ (1,0) [0|1] "-" MHU
  SG_ EDS_R_Error_51 : 62|1@0+ (1,0) [0|1] "-" MHU
  SG_ EDS_R_Error_52 : 63|1@0+ (1,0) [0|1] "-" MHU

BO_ 1179 EDS_F_WarnMsg: 8 XGW_Info
  SG_ CHSKM_EDS_F_WarnMsg : 7|8@0+ (1,0) [0|255] "" MHU
  SG_ ALV_EDS_F_WarnMsg : 11|4@0+ (1,0) [0|14] "" MHU
  SG_ EDS_F_Error_1 : 12|1@0+ (1,0) [0|1] "-" MHU
  SG_ EDS_F_Error_2 : 13|1@0+ (1,0) [0|1] "-" MHU
  SG_ EDS_F_Error_3 : 14|1@0+ (1,0) [0|1] "-" MHU
  SG_ EDS_F_Error_4 : 15|1@0+ (1,0) [0|1] "-" MHU
  SG_ EDS_F_Error_5 : 16|1@0+ (1,0) [0|1] "-" MHU
  SG_ EDS_F_Error_6 : 17|1@0+ (1,0) [0|1] "-" MHU
  SG_ EDS_F_Error_7 : 18|1@0+ (1,0) [0|1] "-" MHU
  SG_ EDS_F_Error_8 : 19|1@0+ (1,0) [0|1] "-" MHU
  SG_ EDS_F_Error_9 : 20|1@0+ (1,0) [0|1] "-" MHU
  SG_ EDS_F_Error_10 : 21|1@0+ (1,0) [0|1] "-" MHU
  SG_ EDS_F_Error_11 : 22|1@0+ (1,0) [0|1] "-" MHU
  SG_ EDS_F_Error_12 : 23|1@0+ (1,0) [0|1] "-" MHU
  SG_ EDS_F_Error_13 : 24|1@0+ (1,0) [0|1] "-" MHU
  SG_ EDS_F_Error_14 : 25|1@0+ (1,0) [0|1] "-" MHU
  SG_ EDS_F_Error_15 : 26|1@0+ (1,0) [0|1] "-" MHU
  SG_ EDS_F_Error_16 : 27|1@0+ (1,0) [0|1] "-" MHU
  SG_ EDS_F_Error_17 : 28|1@0+ (1,0) [0|1] "-" MHU
  SG_ EDS_F_Error_18 : 29|1@0+ (1,0) [0|1] "-" MHU
  SG_ EDS_F_Error_19 : 30|1@0+ (1,0) [0|1] "-" MHU
  SG_ EDS_F_Error_20 : 31|1@0+ (1,0) [0|1] "-" MHU
  SG_ EDS_F_Error_21 : 32|1@0+ (1,0) [0|1] "-" MHU
  SG_ EDS_F_Error_22 : 33|1@0+ (1,0) [0|1] "-" MHU
  SG_ EDS_F_Error_23 : 34|1@0+ (1,0) [0|1] "-" MHU
  SG_ EDS_F_Error_24 : 35|1@0+ (1,0) [0|1] "-" MHU
  SG_ EDS_F_Error_25 : 36|1@0+ (1,0) [0|1] "-" MHU
  SG_ EDS_F_Error_26 : 37|1@0+ (1,0) [0|1] "-" MHU
  SG_ EDS_F_Error_27 : 38|1@0+ (1,0) [0|1] "-" MHU
  SG_ EDS_F_Error_28 : 39|1@0+ (1,0) [0|1] "-" MHU
  SG_ EDS_F_Error_29 : 40|1@0+ (1,0) [0|1] "-" MHU
  SG_ EDS_F_Error_30 : 41|1@0+ (1,0) [0|1] "-" MHU
  SG_ EDS_F_Error_31 : 42|1@0+ (1,0) [0|1] "-" MHU
  SG_ EDS_F_Error_32 : 43|1@0+ (1,0) [0|1] "-" MHU
  SG_ EDS_F_Error_33 : 44|1@0+ (1,0) [0|1] "-" MHU
  SG_ EDS_F_Error_34 : 45|1@0+ (1,0) [0|1] "-" MHU
  SG_ EDS_F_Error_35 : 46|1@0+ (1,0) [0|1] "-" MHU
  SG_ EDS_F_Error_36 : 47|1@0+ (1,0) [0|1] "-" MHU
  SG_ EDS_F_Error_37 : 48|1@0+ (1,0) [0|1] "-" MHU
  SG_ EDS_F_Error_38 : 49|1@0+ (1,0) [0|1] "-" MHU
  SG_ EDS_F_Error_39 : 50|1@0+ (1,0) [0|1] "-" MHU
  SG_ EDS_F_Error_40 : 51|1@0+ (1,0) [0|1] "-" MHU
  SG_ EDS_F_Error_41 : 52|1@0+ (1,0) [0|1] "-" MHU
  SG_ EDS_F_Error_42 : 53|1@0+ (1,0) [0|1] "-" MHU
  SG_ EDS_F_Error_43 : 54|1@0+ (1,0) [0|1] "-" MHU
  SG_ EDS_F_Error_44 : 55|1@0+ (1,0) [0|1] "-" MHU
  SG_ EDS_F_Error_45 : 56|1@0+ (1,0) [0|1] "-" MHU
  SG_ EDS_F_Error_46 : 57|1@0+ (1,0) [0|1] "-" MHU
  SG_ EDS_F_Error_47 : 58|1@0+ (1,0) [0|1] "-" MHU
  SG_ EDS_F_Error_48 : 59|1@0+ (1,0) [0|1] "-" MHU
  SG_ EDS_F_Error_49 : 60|1@0+ (1,0) [0|1] "-" MHU
  SG_ EDS_F_Error_50 : 61|1@0+ (1,0) [0|1] "-" MHU
  SG_ EDS_F_Error_51 : 62|1@0+ (1,0) [0|1] "-" MHU
  SG_ EDS_F_Error_52 : 63|1@0+ (1,0) [0|1] "-" MHU

BO_ 1191 RCU_WarnMsg: 8 XGW_Info
  SG_ CHSKM_RCU_WarnMsg : 7|8@0+ (1,0) [0|255] "" MHU
  SG_ ALV_RCU_WarnMsg : 11|4@0+ (1,0) [0|14] "" MHU
  SG_ RCU_DAA_NoOpDoorOpen : 12|1@0+ (1,0) [0|1] "" MHU
  SG_ RCU_EHandBrk_fault : 13|1@0+ (1,0) [0|1] "" MHU
  SG_ RCU_EOL_NotDone : 14|1@0+ (1,0) [0|1] "" MHU
  SG_ RCU_ECD_RWU_active : 15|1@0+ (1,0) [0|1] "" MHU
  SG_ RCU_ParkOnSteepInclination : 16|1@0+ (1,0) [0|1] "" MHU
  SG_ RCU_BrkForceNotEnough : 17|1@0+ (1,0) [0|1] "" MHU
  SG_ RCU_ReleaseEPB_Wo_PressBrk : 20|1@0+ (1,0) [0|1] "" MHU
  SG_ RCU_ParkBrkApplied : 21|1@0+ (1,0) [0|1] "" MHU
  SG_ RCU_Swch_Mafnc : 27|1@0+ (1,0) [0|1] "" MHU
  SG_ RCU_DAA_NoOpBeltUnbuckled : 28|1@0+ (1,0) [0|1] "" MHU
  SG_ RCU_RollerBenchMode : 29|1@0+ (1,0) [0|1] "" MHU
  SG_ RCU_EPB_ParkLampState : 31|2@0+ (1,0) [0|3] "" MHU
  SG_ RCU_EPB_WarnLampState : 34|2@0+ (1,0) [0|3] "" MHU
  SG_ RCU_WflagRes36 : 36|1@0+ (1,0) [0|1] "" MHU
  SG_ RCU_WflagRes37 : 37|1@0+ (1,0) [0|1] "" MHU
  SG_ RCU_WflagRes38 : 38|1@0+ (1,0) [0|1] "" MHU
  SG_ RCU_WflagRes39 : 39|1@0+ (1,0) [0|1] "" MHU
  SG_ RCU_WflagRes40 : 40|1@0+ (1,0) [0|1] "" MHU
  SG_ RCU_WflagRes41 : 41|1@0+ (1,0) [0|1] "" MHU
  SG_ RCU_WflagRes42 : 42|1@0+ (1,0) [0|1] "" MHU
  SG_ RCU_WflagRes43 : 43|1@0+ (1,0) [0|1] "" MHU
  SG_ RCU_WflagRes44 : 44|1@0+ (1,0) [0|1] "" MHU
  SG_ RCU_WflagRes45 : 45|1@0+ (1,0) [0|1] "" MHU
  SG_ RCU_WflagRes46 : 46|1@0+ (1,0) [0|1] "" MHU
  SG_ RCU_WflagRes47 : 47|1@0+ (1,0) [0|1] "" MHU
  SG_ RCU_Reserved_signal1 : 55|8@0+ (1,0) [0|255] "" MHU

BO_ 1192 EPS_WarnMsg: 8 XGW_Info
  SG_ CHSKM_EPS_WarnMsg : 7|8@0+ (1,0) [0|255] "" MHU
  SG_ ALV_EPS_WarnMsg : 11|4@0+ (1,0) [0|14] "" MHU
  SG_ EPS_Malfunction : 12|1@0+ (1,0) [0|1] "-" MHU
  SG_ EPS_Reduced : 13|1@0+ (1,0) [0|1] "-" MHU
  SG_ EPS_Overheat : 14|1@0+ (1,0) [0|1] "" MHU
  SG_ EPS_NotReady : 15|1@0+ (1,0) [0|1] "-" MHU
  SG_ EPS_Warning_Flag_5 : 16|1@0+ (1,0) [0|1] "-" MHU
  SG_ EPS_Warning_Flag_6 : 17|1@0+ (1,0) [0|1] "" MHU
  SG_ EPS_Warning_Flag_7 : 18|1@0+ (1,0) [0|1] "" MHU
  SG_ EPS_Warning_Flag_8 : 19|1@0+ (1,0) [0|1] "-" MHU
  SG_ EPS_Warning_Flag_9 : 20|1@0+ (1,0) [0|1] "-" MHU
  SG_ EPS_Warning_Flag_10 : 21|1@0+ (1,0) [0|1] "" MHU
  SG_ EPS_Warning_Flag_11 : 22|1@0+ (1,0) [0|1] "" MHU
  SG_ EPS_Warning_Flag_12 : 23|1@0+ (1,0) [0|1] "-" MHU
  SG_ EPS_Reserved_signal1 : 31|8@0+ (1,0) [0|255] "" MHU
  SG_ EPS_Reserved_signal2 : 39|8@0+ (1,0) [0|255] "" MHU
  SG_ EPS_Reserved_signal3 : 47|8@0+ (1,0) [0|255] "-" MHU
  SG_ EPS_Reserved_signal4 : 55|8@0+ (1,0) [0|255] "" MHU
  SG_ EPS_Reserved_signal5 : 63|8@0+ (1,0) [0|255] "" MHU

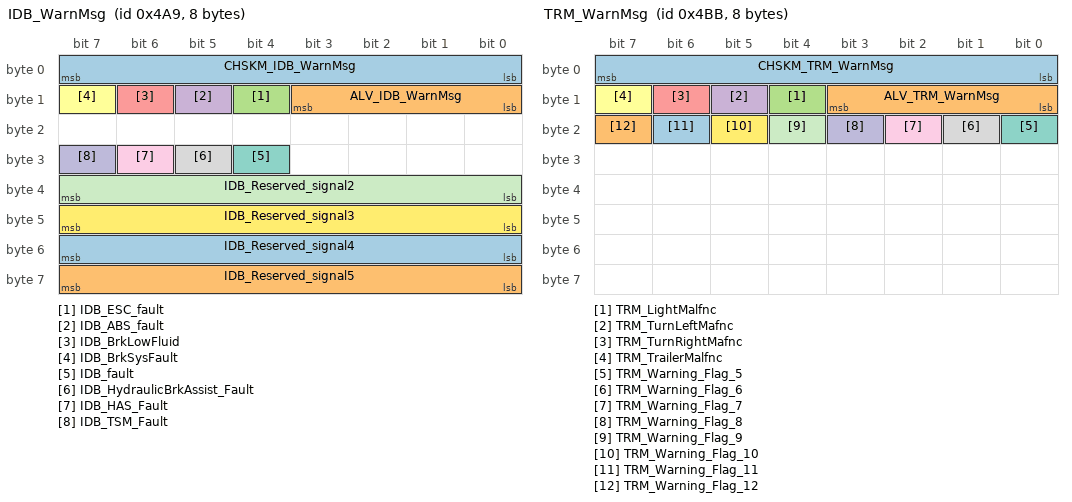
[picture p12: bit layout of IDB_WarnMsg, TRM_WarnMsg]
BO_ 1193 IDB_WarnMsg: 8 XGW_Info
  SG_ CHSKM_IDB_WarnMsg : 7|8@0+ (1,0) [0|255] "" MHU
  SG_ ALV_IDB_WarnMsg : 11|4@0+ (1,0) [0|14] "" MHU
  SG_ IDB_ESC_fault : 12|1@0+ (1,0) [0|1] "-" MHU
  SG_ IDB_ABS_fault : 13|1@0+ (1,0) [0|1] "" MHU
  SG_ IDB_BrkLowFluid : 14|1@0+ (1,0) [0|1] "" MHU
  SG_ IDB_BrkSysFault : 15|1@0+ (1,0) [0|1] "-" MHU
  SG_ IDB_fault : 28|1@0+ (1,0) [0|1] "" MHU
  SG_ IDB_HydraulicBrkAssist_Fault : 29|1@0+ (1,0) [0|1] "-" MHU
  SG_ IDB_HAS_Fault : 30|1@0+ (1,0) [0|1] "" MHU
  SG_ IDB_TSM_Fault : 31|1@0+ (1,0) [0|1] "" MHU
  SG_ IDB_Reserved_signal2 : 39|8@0+ (1,0) [0|255] "-" MHU
  SG_ IDB_Reserved_signal3 : 47|8@0+ (1,0) [0|255] "-" MHU
  SG_ IDB_Reserved_signal4 : 55|8@0+ (1,0) [0|255] "-" MHU
  SG_ IDB_Reserved_signal5 : 63|8@0+ (1,0) [0|255] "" MHU

BO_ 1196 VCU_WarnMsg: 8 XGW_Info
  SG_ CHSKM_VCU_WarnMsg : 7|8@0+ (1,0) [0|255] "" MHU
  SG_ ALV_VCU_WarnMsg : 11|4@0+ (1,0) [0|14] "" MHU
  SG_ VCU_GearPOnlyAtStationaryAlert : 12|1@0+ (1,0) [0|1] "" MHU
  SG_ VCU_GearP_NotPossibleAlert : 13|1@0+ (1,0) [0|1] "" MHU
  SG_ VCU_PressBrakeToEngageGear : 14|1@0+ (1,0) [0|1] "" MHU
  SG_ VCU_CantChangeGear : 15|1@0+ (1,0) [0|1] "" MHU
  SG_ VCU_GearMalfunction : 16|1@0+ (1,0) [0|1] "" MHU
  SG_ VCU_RangeAlert : 17|1@0+ (1,0) [0|1] "" MHU
  SG_ VCU_HVSystemReduced : 18|1@0+ (1,0) [0|1] "" MHU
  SG_ VCU_FrontEDSReduced : 19|1@0+ (1,0) [0|1] "" MHU
  SG_ VCU_FrontEDS_Malfunc : 20|1@0+ (1,0) [0|1] "" MHU
  SG_ VCU_RearEDSReduced : 21|1@0+ (1,0) [0|1] "" MHU
  SG_ VCU_RearEDS_Malfunc : 22|1@0+ (1,0) [0|1] "" MHU
  SG_ VCU_CoolingSystem_Malfunc : 23|1@0+ (1,0) [0|1] "" MHU
  SG_ VCU_NeutralRequest : 24|1@0+ (1,0) [0|1] "" MHU
  SG_ VCU_SoftShutdown : 25|1@0+ (1,0) [0|1] "" MHU
  SG_ VCU_EmergencyShutdown : 26|1@0+ (1,0) [0|1] "" MHU
  SG_ VCU_ChgPortDoorSys_Malfunc : 27|1@0+ (1,0) [0|1] "" MHU
  SG_ VCU_Gearchange_NotPossible : 28|1@0+ (1,0) [0|1] "" MHU
  SG_ VCU_12v_Warning : 29|1@0+ (1,0) [0|1] "" MHU
  SG_ VCU_WflagRes19 : 30|1@0+ (1,0) [0|1] "" MHU
  SG_ VCU_WflagRes20 : 31|1@0+ (1,0) [0|1] "" MHU
  SG_ VCU_WflagRes21 : 32|1@0+ (1,0) [0|1] "" MHU
  SG_ VCU_WflagRes22 : 33|1@0+ (1,0) [0|1] "" MHU
  SG_ VCU_WflagRes23 : 34|1@0+ (1,0) [0|1] "" MHU
  SG_ VCU_WflagRes24 : 35|1@0+ (1,0) [0|1] "" MHU
  SG_ VCU_WflagRes25 : 36|1@0+ (1,0) [0|1] "" MHU
  SG_ VCU_WflagRes26 : 37|1@0+ (1,0) [0|1] "" MHU
  SG_ VCU_WflagRes27 : 38|1@0+ (1,0) [0|1] "" MHU
  SG_ VCU_SuperFastCharge_longer : 39|1@0+ (1,0) [0|1] "" MHU
  SG_ VCU_Reserved_signal1 : 47|8@0+ (1,0) [0|255] "" MHU
  SG_ VCU_Reserved_signal2 : 55|8@0+ (1,0) [0|255] "" MHU
  SG_ VCU_Reserved_signal3 : 63|8@0+ (1,0) [0|255] "" MHU

BO_ 1198 EASC_WarnMsg: 8 EASC
  SG_ CHSKM_EASC_WarnMsg : 7|8@0+ (1,0) [0|255] "" MHU
  SG_ ALV_EASC_WarnMsg : 11|4@0+ (1,0) [0|14] "" MHU
  SG_ EASC_Warning_Flag_1 : 12|1@0+ (1,0) [0|1] "-" MHU
  SG_ EASC_Warning_Flag_2 : 13|1@0+ (1,0) [0|1] "-" MHU
  SG_ EASC_Warning_Flag_3 : 14|1@0+ (1,0) [0|1] "-" MHU
  SG_ EASC_Warning_Flag_4 : 15|1@0+ (1,0) [0|1] "-" MHU
  SG_ EASC_Warning_Flag_5 : 16|1@0+ (1,0) [0|1] "-" MHU
  SG_ EASC_Warning_Flag_6 : 17|1@0+ (1,0) [0|1] "-" MHU
  SG_ EASC_Warning_Flag_7 : 18|1@0+ (1,0) [0|1] "-" MHU
  SG_ EASC_Warning_Flag_8 : 19|1@0+ (1,0) [0|1] "-" MHU
  SG_ EASC_Warning_Flag_9 : 20|1@0+ (1,0) [0|1] "-" MHU
  SG_ EASC_Warning_Flag_10 : 21|1@0+ (1,0) [0|1] "-" MHU
  SG_ EASC_Warning_Flag_11 : 22|1@0+ (1,0) [0|1] "-" MHU
  SG_ EASC_Warning_Flag_12 : 23|1@0+ (1,0) [0|1] "-" MHU
  SG_ EASC_Reserved_signal1 : 31|8@0+ (1,0) [0|255] "-" MHU
  SG_ EASC_Reserved_signal2 : 39|8@0+ (1,0) [0|255] "-" MHU
  SG_ EASC_Reserved_signal3 : 47|8@0+ (1,0) [0|255] "-" MHU
  SG_ EASC_Reserved_signal4 : 55|8@0+ (1,0) [0|255] "-" MHU
  SG_ EASC_Reserved_signal5 : 63|8@0+ (1,0) [0|255] "-" MHU

BO_ 1199 CPD_WarnMsg: 8 CPD
  SG_ CHSKM_CPD_WarnMsg : 7|8@0+ (1,0) [0|255] "" MHU
  SG_ ALV_CPD_WarnMsg : 11|4@0+ (1,0) [0|14] "" MHU
  SG_ CPD_Malfunction : 12|1@0+ (1,0) [0|1] "" MHU
  SG_ CPD_SensorFault : 14|2@0+ (1,0) [0|3] "" MHU
  SG_ CPD_Warning_Flag_4 : 15|1@0+ (1,0) [0|1] "" MHU
  SG_ CPD_Warning_Flag_5 : 16|1@0+ (1,0) [0|1] "" MHU
  SG_ CPD_Warning_Flag_6 : 17|1@0+ (1,0) [0|1] "" MHU
  SG_ CPD_Warning_Flag_7 : 18|1@0+ (1,0) [0|1] "" MHU
  SG_ CPD_Warning_Flag_8 : 19|1@0+ (1,0) [0|1] "" MHU
  SG_ CPD_Warning_Flag_9 : 20|1@0+ (1,0) [0|1] "" MHU
  SG_ CPD_Warning_Flag_10 : 21|1@0+ (1,0) [0|1] "" MHU
  SG_ CPD_Warning_Flag_11 : 22|1@0+ (1,0) [0|1] "" MHU
  SG_ CPD_Warning_Flag_12 : 23|1@0+ (1,0) [0|1] "" MHU
  SG_ CPD_Reserved_signal1 : 31|8@0+ (1,0) [0|255] "" MHU
  SG_ CPD_Reserved_signal2 : 39|8@0+ (1,0) [0|255] "" MHU
  SG_ CPD_Reserved_signal3 : 47|8@0+ (1,0) [0|255] "" MHU
  SG_ CPD_Reserved_signal4 : 55|8@0+ (1,0) [0|255] "" MHU
  SG_ CPD_Reserved_signal5 : 63|8@0+ (1,0) [0|255] "" MHU

BO_ 1211 TRM_WarnMsg: 8 XGW_Info
  SG_ CHSKM_TRM_WarnMsg : 7|8@0+ (1,0) [0|255] "" MHU
  SG_ ALV_TRM_WarnMsg : 11|4@0+ (1,0) [0|14] "" MHU
  SG_ TRM_LightMalfnc : 12|1@0+ (1,0) [0|1] "-" MHU
  SG_ TRM_TurnLeftMafnc : 13|1@0+ (1,0) [0|1] "-" MHU
  SG_ TRM_TurnRightMafnc : 14|1@0+ (1,0) [0|1] "" MHU
  SG_ TRM_TrailerMalfnc : 15|1@0+ (1,0) [0|1] "" MHU
  SG_ TRM_Warning_Flag_5 : 16|1@0+ (1,0) [0|1] "-" MHU
  SG_ TRM_Warning_Flag_6 : 17|1@0+ (1,0) [0|1] "" MHU
  SG_ TRM_Warning_Flag_7 : 18|1@0+ (1,0) [0|1] "" MHU
  SG_ TRM_Warning_Flag_8 : 19|1@0+ (1,0) [0|1] "-" MHU
  SG_ TRM_Warning_Flag_9 : 20|1@0+ (1,0) [0|1] "-" MHU
  SG_ TRM_Warning_Flag_10 : 21|1@0+ (1,0) [0|1] "-" MHU
  SG_ TRM_Warning_Flag_11 : 22|1@0+ (1,0) [0|1] "" MHU
  SG_ TRM_Warning_Flag_12 : 23|1@0+ (1,0) [0|1] "" MHU

BO_ 1213 POD_WarnMsg: 8 XGW_Info
  SG_ CHSKM_POD_WarnMsg : 7|8@0+ (1,0) [0|255] "" MHU
  SG_ ALV_POD_WarnMsg : 11|4@0+ (1,0) [0|14] "" MHU
  SG_ POD_Warning_Flag_1 : 12|1@0+ (1,0) [0|1] "-" MHU
  SG_ POD_Warning_Flag_2 : 13|1@0+ (1,0) [0|1] "-" MHU
  SG_ POD_Warning_Flag_3 : 14|1@0+ (1,0) [0|1] "-" MHU
  SG_ POD_Warning_Flag_4 : 15|1@0+ (1,0) [0|1] "-" MHU
  SG_ POD_Warning_Flag_5 : 16|1@0+ (1,0) [0|1] "-" MHU
  SG_ POD_Warning_Flag_6 : 17|1@0+ (1,0) [0|1] "-" MHU
  SG_ POD_Warning_Flag_7 : 18|1@0+ (1,0) [0|1] "-" MHU
  SG_ POD_Warning_Flag_8 : 19|1@0+ (1,0) [0|1] "-" MHU
  SG_ POD_Warning_Flag_9 : 20|1@0+ (1,0) [0|1] "-" MHU
  SG_ POD_Warning_Flag_10 : 21|1@0+ (1,0) [0|1] "-" MHU
  SG_ POD_Warning_Flag_11 : 22|1@0+ (1,0) [0|1] "-" MHU
  SG_ POD_Warning_Flag_12 : 23|1@0+ (1,0) [0|1] "-" MHU
  SG_ POD_Warning_Flag_13 : 24|1@0+ (1,0) [0|1] "-" MHU
  SG_ POD_Warning_Flag_14 : 25|1@0+ (1,0) [0|1] "-" MHU
  SG_ POD_Warning_Flag_15 : 26|1@0+ (1,0) [0|1] "-" MHU
  SG_ POD_Warning_Flag_16 : 27|1@0+ (1,0) [0|1] "-" MHU
  SG_ POD_Warning_Flag_17 : 28|1@0+ (1,0) [0|1] "-" MHU
  SG_ POD_Warning_Flag_18 : 29|1@0+ (1,0) [0|1] "-" MHU
  SG_ POD_Warning_Flag_19 : 30|1@0+ (1,0) [0|1] "-" MHU
  SG_ POD_Warning_Flag_20 : 31|1@0+ (1,0) [0|1] "-" MHU
  SG_ POD_Warning_Flag_21 : 32|1@0+ (1,0) [0|1] "-" MHU
  SG_ POD_Warning_Flag_22 : 33|1@0+ (1,0) [0|1] "-" MHU
  SG_ POD_Warning_Flag_23 : 34|1@0+ (1,0) [0|1] "-" MHU
  SG_ POD_Warning_Flag_24 : 35|1@0+ (1,0) [0|1] "-" MHU
  SG_ POD_Warning_Flag_25 : 36|1@0+ (1,0) [0|1] "-" MHU
  SG_ POD_Warning_Flag_26 : 37|1@0+ (1,0) [0|1] "-" MHU
  SG_ POD_Warning_Flag_27 : 38|1@0+ (1,0) [0|1] "-" MHU
  SG_ POD_Warning_Flag_28 : 39|1@0+ (1,0) [0|1] "-" MHU
  SG_ POD_Reserved_signal3 : 47|8@0+ (1,0) [0|255] "-" MHU
  SG_ POD_Reserved_signal4 : 55|8@0+ (1,0) [0|255] "-" MHU
  SG_ POD_Reserved_signal5 : 63|8@0+ (1,0) [0|255] "-" MHU

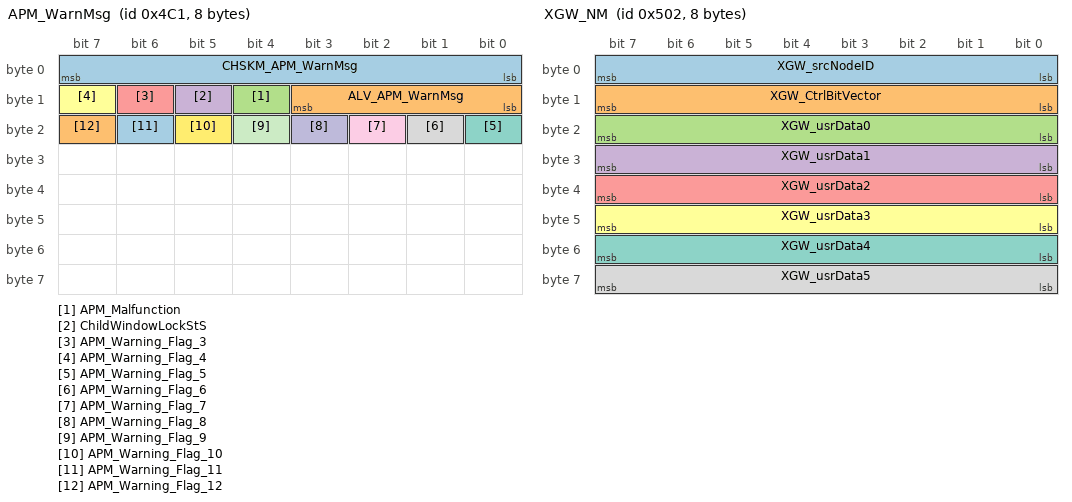
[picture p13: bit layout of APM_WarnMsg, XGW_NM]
BO_ 1217 APM_WarnMsg: 8 XGW_Info
  SG_ CHSKM_APM_WarnMsg : 7|8@0+ (1,0) [0|255] "" MHU
  SG_ ALV_APM_WarnMsg : 11|4@0+ (1,0) [0|14] "" MHU
  SG_ APM_Malfunction : 12|1@0+ (1,0) [0|1] "" MHU
  SG_ ChildWindowLockStS : 13|1@0+ (1,0) [0|1] "-" MHU
  SG_ APM_Warning_Flag_3 : 14|1@0+ (1,0) [0|1] "" MHU
  SG_ APM_Warning_Flag_4 : 15|1@0+ (1,0) [0|1] "" MHU
  SG_ APM_Warning_Flag_5 : 16|1@0+ (1,0) [0|1] "-" MHU
  SG_ APM_Warning_Flag_6 : 17|1@0+ (1,0) [0|1] "" MHU
  SG_ APM_Warning_Flag_7 : 18|1@0+ (1,0) [0|1] "-" MHU
  SG_ APM_Warning_Flag_8 : 19|1@0+ (1,0) [0|1] "" MHU
  SG_ APM_Warning_Flag_9 : 20|1@0+ (1,0) [0|1] "" MHU
  SG_ APM_Warning_Flag_10 : 21|1@0+ (1,0) [0|1] "" MHU
  SG_ APM_Warning_Flag_11 : 22|1@0+ (1,0) [0|1] "" MHU
  SG_ APM_Warning_Flag_12 : 23|1@0+ (1,0) [0|1] "-" MHU

BO_ 1218 GW_MHU_IDS_STS: 8 XGW_Info
  SG_ Checksum_0x4C2 : 7|8@0+ (1,0) [0|255] "" MHU
  SG_ Rolling_Counter_0x4C2 : 11|4@0+ (1,0) [0|14] "" MHU
  SG_ Event_Counter : 23|10@0+ (1,0) [0|1023] "-" MHU
  SG_ Event_type : 29|32@0+ (1,0) [0|4294967295] "-" MHU

BO_ 1282 XGW_NM: 8 XGW_Info
  SG_ XGW_srcNodeID : 7|8@0+ (1,0) [0|255] "" ADAS_Info,CPD,EASC,HUD,MHU
  SG_ XGW_CtrlBitVector : 15|8@0+ (1,0) [0|255] "" ADAS_Info,CPD,EASC,HUD,MHU
  SG_ XGW_usrData0 : 23|8@0+ (1,0) [0|255] "" ADAS_Info,CPD,EASC,HUD,MHU
  SG_ XGW_usrData1 : 31|8@0+ (1,0) [0|255] "" ADAS_Info,CPD,EASC,HUD,MHU
  SG_ XGW_usrData2 : 39|8@0+ (1,0) [0|255] "" ADAS_Info,CPD,EASC,HUD,MHU
  SG_ XGW_usrData3 : 47|8@0+ (1,0) [0|255] "" ADAS_Info,CPD,EASC,HUD,MHU
  SG_ XGW_usrData4 : 55|8@0+ (1,0) [0|255] "" ADAS_Info,CPD,EASC,HUD,MHU
  SG_ XGW_usrData5 : 63|8@0+ (1,0) [0|255] "" ADAS_Info,CPD,EASC,HUD,MHU

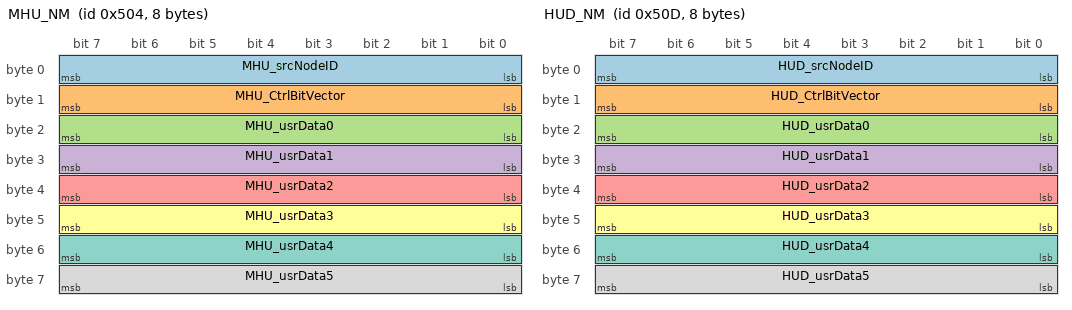
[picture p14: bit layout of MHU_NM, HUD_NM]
BO_ 1284 MHU_NM: 8 MHU
  SG_ MHU_srcNodeID : 7|8@0+ (1,0) [0|255] "-" ADAS_Info,CPD,EASC,HUD,XGW_Info
  SG_ MHU_CtrlBitVector : 15|8@0+ (1,0) [0|255] "-" ADAS_Info,CPD,EASC,HUD,XGW_Info
  SG_ MHU_usrData0 : 23|8@0+ (1,0) [0|255] "-" ADAS_Info,CPD,EASC,HUD,XGW_Info
  SG_ MHU_usrData1 : 31|8@0+ (1,0) [0|255] "-" ADAS_Info,CPD,EASC,HUD,XGW_Info
  SG_ MHU_usrData2 : 39|8@0+ (1,0) [0|255] "-" ADAS_Info,CPD,EASC,HUD,XGW_Info
  SG_ MHU_usrData3 : 47|8@0+ (1,0) [0|255] "-" ADAS_Info,CPD,EASC,HUD,XGW_Info
  SG_ MHU_usrData4 : 55|8@0+ (1,0) [0|255] "-" ADAS_Info,CPD,EASC,HUD,XGW_Info
  SG_ MHU_usrData5 : 63|8@0+ (1,0) [0|255] "-" ADAS_Info,CPD,EASC,HUD,XGW_Info

BO_ 1293 HUD_NM: 8 HUD
  SG_ HUD_srcNodeID : 7|8@0+ (1,0) [0|255] "-" ADAS_Info,CPD,EASC,MHU,XGW_Info
  SG_ HUD_CtrlBitVector : 15|8@0+ (1,0) [0|255] "-" ADAS_Info,CPD,EASC,MHU,XGW_Info
  SG_ HUD_usrData0 : 23|8@0+ (1,0) [0|255] "-" ADAS_Info,CPD,EASC,MHU,XGW_Info
  SG_ HUD_usrData1 : 31|8@0+ (1,0) [0|255] "-" ADAS_Info,CPD,EASC,MHU,XGW_Info
  SG_ HUD_usrData2 : 39|8@0+ (1,0) [0|255] "-" ADAS_Info,CPD,EASC,MHU,XGW_Info
  SG_ HUD_usrData3 : 47|8@0+ (1,0) [0|255] "-" ADAS_Info,CPD,EASC,MHU,XGW_Info
  SG_ HUD_usrData4 : 55|8@0+ (1,0) [0|255] "-" ADAS_Info,CPD,EASC,MHU,XGW_Info
  SG_ HUD_usrData5 : 63|8@0+ (1,0) [0|255] "-" ADAS_Info,CPD,EASC,MHU,XGW_Info

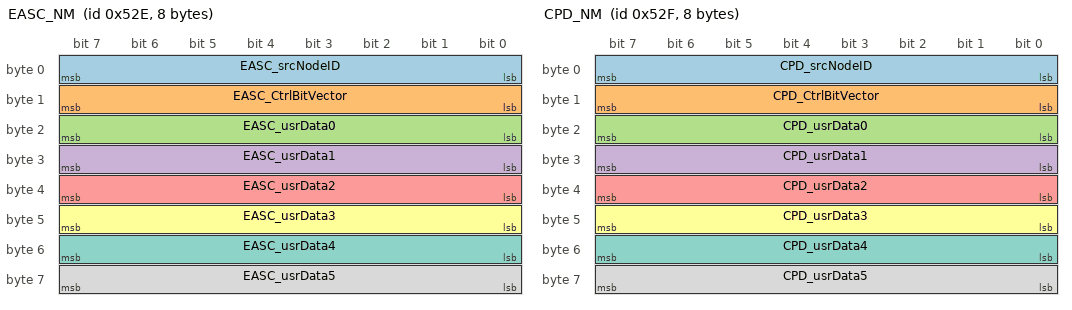
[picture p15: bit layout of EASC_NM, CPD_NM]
BO_ 1326 EASC_NM: 8 EASC
  SG_ EASC_srcNodeID : 7|8@0+ (1,0) [0|255] "-" ADAS_Info,CPD,HUD,MHU,XGW_Info
  SG_ EASC_CtrlBitVector : 15|8@0+ (1,0) [0|255] "-" ADAS_Info,CPD,HUD,MHU,XGW_Info
  SG_ EASC_usrData0 : 23|8@0+ (1,0) [0|255] "-" ADAS_Info,CPD,HUD,MHU,XGW_Info
  SG_ EASC_usrData1 : 31|8@0+ (1,0) [0|255] "-" ADAS_Info,CPD,HUD,MHU,XGW_Info
  SG_ EASC_usrData2 : 39|8@0+ (1,0) [0|255] "-" ADAS_Info,CPD,HUD,MHU,XGW_Info
  SG_ EASC_usrData3 : 47|8@0+ (1,0) [0|255] "-" ADAS_Info,CPD,HUD,MHU,XGW_Info
  SG_ EASC_usrData4 : 55|8@0+ (1,0) [0|255] "-" ADAS_Info,CPD,HUD,MHU,XGW_Info
  SG_ EASC_usrData5 : 63|8@0+ (1,0) [0|255] "-" ADAS_Info,CPD,HUD,MHU,XGW_Info

BO_ 1327 CPD_NM: 8 CPD
  SG_ CPD_srcNodeID : 7|8@0+ (1,0) [0|255] "-" ADAS_Info,EASC,HUD,MHU,XGW_Info
  SG_ CPD_CtrlBitVector : 15|8@0+ (1,0) [0|255] "-" ADAS_Info,EASC,HUD,MHU,XGW_Info
  SG_ CPD_usrData0 : 23|8@0+ (1,0) [0|255] "-" ADAS_Info,EASC,HUD,MHU,XGW_Info
  SG_ CPD_usrData1 : 31|8@0+ (1,0) [0|255] "-" ADAS_Info,EASC,HUD,MHU,XGW_Info
  SG_ CPD_usrData2 : 39|8@0+ (1,0) [0|255] "-" ADAS_Info,EASC,HUD,MHU,XGW_Info
  SG_ CPD_usrData3 : 47|8@0+ (1,0) [0|255] "-" ADAS_Info,EASC,HUD,MHU,XGW_Info
  SG_ CPD_usrData4 : 55|8@0+ (1,0) [0|255] "-" ADAS_Info,EASC,HUD,MHU,XGW_Info
  SG_ CPD_usrData5 : 63|8@0+ (1,0) [0|255] "-" ADAS_Info,EASC,HUD,MHU,XGW_Info

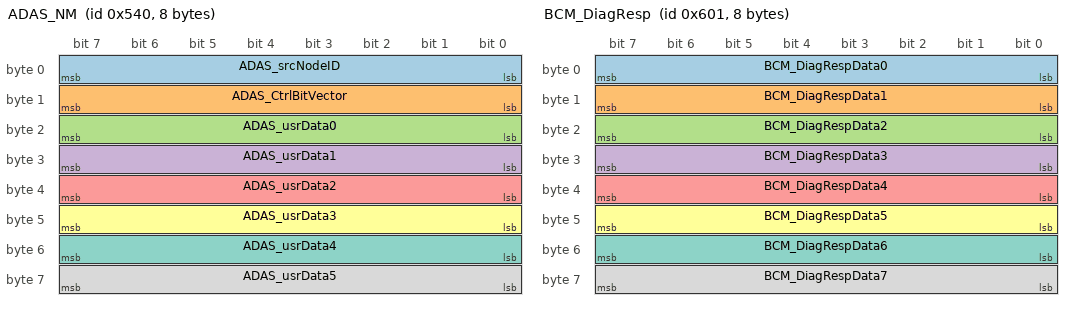
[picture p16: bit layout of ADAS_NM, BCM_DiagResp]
BO_ 1344 ADAS_NM: 8 ADAS_Info
  SG_ ADAS_srcNodeID : 7|8@0+ (1,0) [0|255] "" CPD,EASC,HUD,MHU,XGW_Info
  SG_ ADAS_CtrlBitVector : 15|8@0+ (1,0) [0|255] "-" CPD,EASC,HUD,MHU,XGW_Info
  SG_ ADAS_usrData0 : 23|8@0+ (1,0) [0|255] "" CPD,EASC,HUD,MHU,XGW_Info
  SG_ ADAS_usrData1 : 31|8@0+ (1,0) [0|255] "" CPD,EASC,HUD,MHU,XGW_Info
  SG_ ADAS_usrData2 : 39|8@0+ (1,0) [0|255] "" CPD,EASC,HUD,MHU,XGW_Info
  SG_ ADAS_usrData3 : 47|8@0+ (1,0) [0|255] "-" CPD,EASC,HUD,MHU,XGW_Info
  SG_ ADAS_usrData4 : 55|8@0+ (1,0) [0|255] "-" CPD,EASC,HUD,MHU,XGW_Info
  SG_ ADAS_usrData5 : 63|8@0+ (1,0) [0|255] "-" CPD,EASC,HUD,MHU,XGW_Info

BO_ 1537 BCM_DiagResp: 8 XGW_Info
  SG_ BCM_DiagRespData0 : 7|8@0+ (1,0) [0|255] "" MHU
  SG_ BCM_DiagRespData1 : 15|8@0+ (1,0) [0|255] "-" MHU
  SG_ BCM_DiagRespData2 : 23|8@0+ (1,0) [0|255] "" MHU
  SG_ BCM_DiagRespData3 : 31|8@0+ (1,0) [0|255] "" MHU
  SG_ BCM_DiagRespData4 : 39|8@0+ (1,0) [0|255] "" MHU
  SG_ BCM_DiagRespData5 : 47|8@0+ (1,0) [0|255] "" MHU
  SG_ BCM_DiagRespData6 : 55|8@0+ (1,0) [0|255] "-" MHU
  SG_ BCM_DiagRespData7 : 63|8@0+ (1,0) [0|255] "" MHU

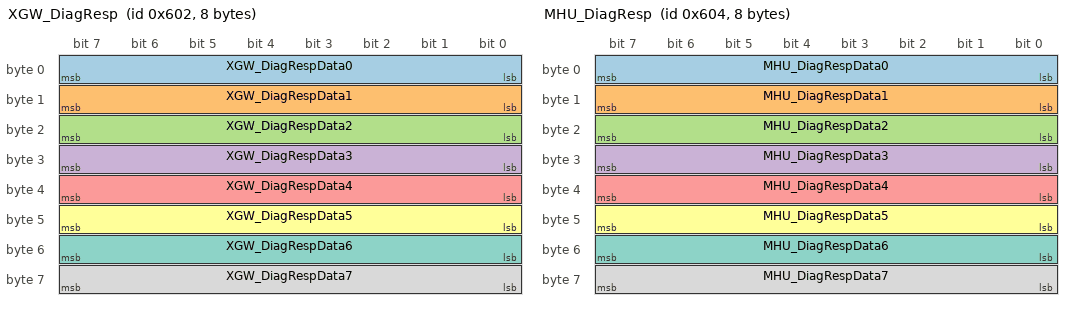
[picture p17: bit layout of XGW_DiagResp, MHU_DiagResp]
BO_ 1538 XGW_DiagResp: 8 XGW_Info
  SG_ XGW_DiagRespData0 : 7|8@0+ (1,0) [0|255] "-" MHU
  SG_ XGW_DiagRespData1 : 15|8@0+ (1,0) [0|255] "-" MHU
  SG_ XGW_DiagRespData2 : 23|8@0+ (1,0) [0|255] "-" MHU
  SG_ XGW_DiagRespData3 : 31|8@0+ (1,0) [0|255] "" MHU
  SG_ XGW_DiagRespData4 : 39|8@0+ (1,0) [0|255] "" MHU
  SG_ XGW_DiagRespData5 : 47|8@0+ (1,0) [0|255] "-" MHU
  SG_ XGW_DiagRespData6 : 55|8@0+ (1,0) [0|255] "" MHU
  SG_ XGW_DiagRespData7 : 63|8@0+ (1,0) [0|255] "-" MHU

BO_ 1540 MHU_DiagResp: 8 MHU
  SG_ MHU_DiagRespData0 : 7|8@0+ (1,0) [0|255] "-" XGW_Info
  SG_ MHU_DiagRespData1 : 15|8@0+ (1,0) [0|255] "-" XGW_Info
  SG_ MHU_DiagRespData2 : 23|8@0+ (1,0) [0|255] "" XGW_Info
  SG_ MHU_DiagRespData3 : 31|8@0+ (1,0) [0|255] "-" XGW_Info
  SG_ MHU_DiagRespData4 : 39|8@0+ (1,0) [0|255] "-" XGW_Info
  SG_ MHU_DiagRespData5 : 47|8@0+ (1,0) [0|255] "-" XGW_Info
  SG_ MHU_DiagRespData6 : 55|8@0+ (1,0) [0|255] "-" XGW_Info
  SG_ MHU_DiagRespData7 : 63|8@0+ (1,0) [0|255] "" XGW_Info

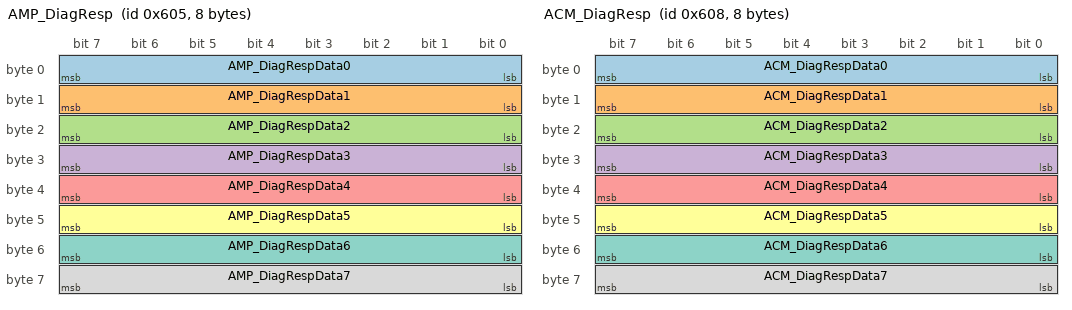
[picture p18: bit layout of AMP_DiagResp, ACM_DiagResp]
BO_ 1541 AMP_DiagResp: 8 AMP
  SG_ AMP_DiagRespData0 : 7|8@0+ (1,0) [0|255] "-" MHU
  SG_ AMP_DiagRespData1 : 15|8@0+ (1,0) [0|255] "-" MHU
  SG_ AMP_DiagRespData2 : 23|8@0+ (1,0) [0|255] "-" MHU
  SG_ AMP_DiagRespData3 : 31|8@0+ (1,0) [0|255] "" MHU
  SG_ AMP_DiagRespData4 : 39|8@0+ (1,0) [0|255] "-" MHU
  SG_ AMP_DiagRespData5 : 47|8@0+ (1,0) [0|255] "" MHU
  SG_ AMP_DiagRespData6 : 55|8@0+ (1,0) [0|255] "" MHU
  SG_ AMP_DiagRespData7 : 63|8@0+ (1,0) [0|255] "-" MHU

BO_ 1544 ACM_DiagResp: 8 XGW_Info
  SG_ ACM_DiagRespData0 : 7|8@0+ (1,0) [0|255] "" MHU
  SG_ ACM_DiagRespData1 : 15|8@0+ (1,0) [0|255] "-" MHU
  SG_ ACM_DiagRespData2 : 23|8@0+ (1,0) [0|255] "" MHU
  SG_ ACM_DiagRespData3 : 31|8@0+ (1,0) [0|255] "-" MHU
  SG_ ACM_DiagRespData4 : 39|8@0+ (1,0) [0|255] "" MHU
  SG_ ACM_DiagRespData5 : 47|8@0+ (1,0) [0|255] "-" MHU
  SG_ ACM_DiagRespData6 : 55|8@0+ (1,0) [0|255] "" MHU
  SG_ ACM_DiagRespData7 : 63|8@0+ (1,0) [0|255] "-" MHU

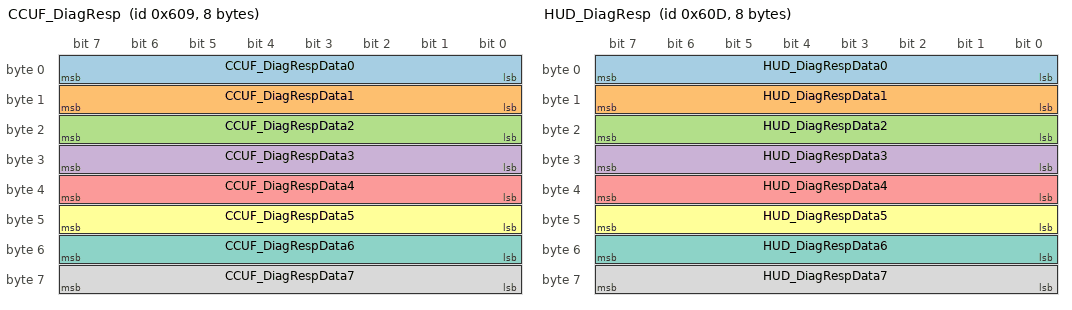
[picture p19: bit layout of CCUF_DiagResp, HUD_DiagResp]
BO_ 1545 CCUF_DiagResp: 8 XGW_Info
  SG_ CCUF_DiagRespData0 : 7|8@0+ (1,0) [0|255] "" MHU
  SG_ CCUF_DiagRespData1 : 15|8@0+ (1,0) [0|255] "-" MHU
  SG_ CCUF_DiagRespData2 : 23|8@0+ (1,0) [0|255] "-" MHU
  SG_ CCUF_DiagRespData3 : 31|8@0+ (1,0) [0|255] "" MHU
  SG_ CCUF_DiagRespData4 : 39|8@0+ (1,0) [0|255] "" MHU
  SG_ CCUF_DiagRespData5 : 47|8@0+ (1,0) [0|255] "-" MHU
  SG_ CCUF_DiagRespData6 : 55|8@0+ (1,0) [0|255] "-" MHU
  SG_ CCUF_DiagRespData7 : 63|8@0+ (1,0) [0|255] "" MHU

BO_ 1549 HUD_DiagResp: 8 HUD
  SG_ HUD_DiagRespData0 : 7|8@0+ (1,0) [0|255] "" MHU
  SG_ HUD_DiagRespData1 : 15|8@0+ (1,0) [0|255] "" MHU
  SG_ HUD_DiagRespData2 : 23|8@0+ (1,0) [0|255] "" MHU
  SG_ HUD_DiagRespData3 : 31|8@0+ (1,0) [0|255] "" MHU
  SG_ HUD_DiagRespData4 : 39|8@0+ (1,0) [0|255] "-" MHU
  SG_ HUD_DiagRespData5 : 47|8@0+ (1,0) [0|255] "" MHU
  SG_ HUD_DiagRespData6 : 55|8@0+ (1,0) [0|255] "-" MHU
  SG_ HUD_DiagRespData7 : 63|8@0+ (1,0) [0|255] "" MHU

BO_ 1550 ETG_DiagResp: 8 XGW_Info
  SG_ ETG_DiagRespData0 : 7|8@0+ (1,0) [0|255] "" MHU
  SG_ ETG_DiagRespData1 : 15|8@0+ (1,0) [0|255] "" MHU
  SG_ ETG_DiagRespData2 : 23|8@0+ (1,0) [0|255] "" MHU
  SG_ ETG_DiagRespData3 : 31|8@0+ (1,0) [0|255] "-" MHU
  SG_ ETG_DiagRespData4 : 39|8@0+ (1,0) [0|255] "" MHU
  SG_ ETG_DiagRespData5 : 47|8@0+ (1,0) [0|255] "" MHU
  SG_ ETG_DiagRespData6 : 55|8@0+ (1,0) [0|255] "" MHU
  SG_ ETG_DiagRespData7 : 63|8@0+ (1,0) [0|255] "" MHU

BO_ 1551 YSS_DiagResp: 8 XGW_Info
  SG_ YSS_DiagRespData0 : 7|8@0+ (1,0) [0|255] "" MHU
  SG_ YSS_DiagRespData1 : 15|8@0+ (1,0) [0|255] "" MHU
  SG_ YSS_DiagRespData2 : 23|8@0+ (1,0) [0|255] "-" MHU
  SG_ YSS_DiagRespData3 : 31|8@0+ (1,0) [0|255] "" MHU
  SG_ YSS_DiagRespData4 : 39|8@0+ (1,0) [0|255] "" MHU
  SG_ YSS_DiagRespData5 : 47|8@0+ (1,0) [0|255] "" MHU
  SG_ YSS_DiagRespData6 : 55|8@0+ (1,0) [0|255] "" MHU
  SG_ YSS_DiagRespData7 : 63|8@0+ (1,0) [0|255] "" MHU

BO_ 1552 GS_DiagResp: 8 XGW_Info
  SG_ GS_DiagRespData0 : 7|8@0+ (1,0) [0|255] "-" MHU
  SG_ GS_DiagRespData1 : 15|8@0+ (1,0) [0|255] "" MHU
  SG_ GS_DiagRespData2 : 23|8@0+ (1,0) [0|255] "-" MHU
  SG_ GS_DiagRespData3 : 31|8@0+ (1,0) [0|255] "" MHU
  SG_ GS_DiagRespData4 : 39|8@0+ (1,0) [0|255] "" MHU
  SG_ GS_DiagRespData5 : 47|8@0+ (1,0) [0|255] "" MHU
  SG_ GS_DiagRespData6 : 55|8@0+ (1,0) [0|255] "-" MHU
  SG_ GS_DiagRespData7 : 63|8@0+ (1,0) [0|255] "" MHU

BO_ 1555 BMS_DiagResp: 8 XGW_Info
  SG_ BMS_DiagRespData0 : 7|8@0+ (1,0) [0|255] "" MHU
  SG_ BMS_DiagRespData1 : 15|8@0+ (1,0) [0|255] "" MHU
  SG_ BMS_DiagRespData2 : 23|8@0+ (1,0) [0|255] "" MHU
  SG_ BMS_DiagRespData3 : 31|8@0+ (1,0) [0|255] "" MHU
  SG_ BMS_DiagRespData4 : 39|8@0+ (1,0) [0|255] "" MHU
  SG_ BMS_DiagRespData5 : 47|8@0+ (1,0) [0|255] "" MHU
  SG_ BMS_DiagRespData6 : 55|8@0+ (1,0) [0|255] "" MHU
  SG_ BMS_DiagRespData7 : 63|8@0+ (1,0) [0|255] "-" MHU

BO_ 1556 CCUR_DiagResp: 8 XGW_Info
  SG_ CCUR_DiagRespData0 : 7|8@0+ (1,0) [0|255] "" MHU
  SG_ CCUR_DiagRespData1 : 15|8@0+ (1,0) [0|255] "" MHU
  SG_ CCUR_DiagRespData2 : 23|8@0+ (1,0) [0|255] "" MHU
  SG_ CCUR_DiagRespData3 : 31|8@0+ (1,0) [0|255] "" MHU
  SG_ CCUR_DiagRespData4 : 39|8@0+ (1,0) [0|255] "-" MHU
  SG_ CCUR_DiagRespData5 : 47|8@0+ (1,0) [0|255] "" MHU
  SG_ CCUR_DiagRespData6 : 55|8@0+ (1,0) [0|255] "-" MHU
  SG_ CCUR_DiagRespData7 : 63|8@0+ (1,0) [0|255] "" MHU

BO_ 1562 EDS_R_DiagResp: 8 XGW_Info
  SG_ EDS_R_DiagRespData0 : 7|8@0+ (1,0) [0|255] "" MHU
  SG_ EDS_R_DiagRespData1 : 15|8@0+ (1,0) [0|255] "" MHU
  SG_ EDS_R_DiagRespData2 : 23|8@0+ (1,0) [0|255] "-" MHU
  SG_ EDS_R_DiagRespData3 : 31|8@0+ (1,0) [0|255] "" MHU
  SG_ EDS_R_DiagRespData4 : 39|8@0+ (1,0) [0|255] "" MHU
  SG_ EDS_R_DiagRespData5 : 47|8@0+ (1,0) [0|255] "-" MHU
  SG_ EDS_R_DiagRespData6 : 55|8@0+ (1,0) [0|255] "-" MHU
  SG_ EDS_R_DiagRespData7 : 63|8@0+ (1,0) [0|255] "-" MHU

BO_ 1563 EDS_F_DiagResp: 8 XGW_Info
  SG_ EDS_F_DiagRespData0 : 7|8@0+ (1,0) [0|255] "" MHU
  SG_ EDS_F_DiagRespData1 : 15|8@0+ (1,0) [0|255] "" MHU
  SG_ EDS_F_DiagRespData2 : 23|8@0+ (1,0) [0|255] "-" MHU
  SG_ EDS_F_DiagRespData3 : 31|8@0+ (1,0) [0|255] "" MHU
  SG_ EDS_F_DiagRespData4 : 39|8@0+ (1,0) [0|255] "" MHU
  SG_ EDS_F_DiagRespData5 : 47|8@0+ (1,0) [0|255] "" MHU
  SG_ EDS_F_DiagRespData6 : 55|8@0+ (1,0) [0|255] "-" MHU
  SG_ EDS_F_DiagRespData7 : 63|8@0+ (1,0) [0|255] "" MHU

BO_ 1566 PSM_D_DiagResp: 8 XGW_Info
  SG_ PSM_D_DiagRespData0 : 7|8@0+ (1,0) [0|255] "" MHU
  SG_ PSM_D_DiagRespData1 : 15|8@0+ (1,0) [0|255] "" MHU
  SG_ PSM_D_DiagRespData2 : 23|8@0+ (1,0) [0|255] "" MHU
  SG_ PSM_D_DiagRespData3 : 31|8@0+ (1,0) [0|255] "-" MHU
  SG_ PSM_D_DiagRespData4 : 39|8@0+ (1,0) [0|255] "" MHU
  SG_ PSM_D_DiagRespData5 : 47|8@0+ (1,0) [0|255] "" MHU
  SG_ PSM_D_DiagRespData6 : 55|8@0+ (1,0) [0|255] "" MHU
  SG_ PSM_D_DiagRespData7 : 63|8@0+ (1,0) [0|255] "" MHU

BO_ 1573 MRGEN_DiagResp: 8 XGW_Info
  SG_ MRGEN_DiagRespData0 : 7|8@0+ (1,0) [0|255] "" MHU
  SG_ MRGEN_DiagRespData1 : 15|8@0+ (1,0) [0|255] "-" MHU
  SG_ MRGEN_DiagRespData2 : 23|8@0+ (1,0) [0|255] "" MHU
  SG_ MRGEN_DiagRespData3 : 31|8@0+ (1,0) [0|255] "" MHU
  SG_ MRGEN_DiagRespData4 : 39|8@0+ (1,0) [0|255] "" MHU
  SG_ MRGEN_DiagRespData5 : 47|8@0+ (1,0) [0|255] "" MHU
  SG_ MRGEN_DiagRespData6 : 55|8@0+ (1,0) [0|255] "" MHU
  SG_ MRGEN_DiagRespData7 : 63|8@0+ (1,0) [0|255] "-" MHU

BO_ 1574 SCAM_DiagResp: 8 XGW_Info
  SG_ SCAM_DiagRespData0 : 7|8@0+ (1,0) [0|255] "" MHU
  SG_ SCAM_DiagRespData1 : 15|8@0+ (1,0) [0|255] "" MHU
  SG_ SCAM_DiagRespData2 : 23|8@0+ (1,0) [0|255] "" MHU
  SG_ SCAM_DiagRespData3 : 31|8@0+ (1,0) [0|255] "" MHU
  SG_ SCAM_DiagRespData4 : 39|8@0+ (1,0) [0|255] "" MHU
  SG_ SCAM_DiagRespData5 : 47|8@0+ (1,0) [0|255] "-" MHU
  SG_ SCAM_DiagRespData6 : 55|8@0+ (1,0) [0|255] "" MHU
  SG_ SCAM_DiagRespData7 : 63|8@0+ (1,0) [0|255] "" MHU

BO_ 1575 RCU_DiagResp: 8 XGW_Info
  SG_ RCU_DiagRespData0 : 7|8@0+ (1,0) [0|255] "" MHU
  SG_ RCU_DiagRespData1 : 15|8@0+ (1,0) [0|255] "" MHU
  SG_ RCU_DiagRespData2 : 23|8@0+ (1,0) [0|255] "" MHU
  SG_ RCU_DiagRespData3 : 31|8@0+ (1,0) [0|255] "" MHU
  SG_ RCU_DiagRespData4 : 39|8@0+ (1,0) [0|255] "" MHU
  SG_ RCU_DiagRespData5 : 47|8@0+ (1,0) [0|255] "" MHU
  SG_ RCU_DiagRespData6 : 55|8@0+ (1,0) [0|255] "" MHU
  SG_ RCU_DiagRespData7 : 63|8@0+ (1,0) [0|255] "" MHU

BO_ 1576 EPS_DiagResp: 8 XGW_Info
  SG_ EPS_DiagRespData0 : 7|8@0+ (1,0) [0|255] "-" MHU
  SG_ EPS_DiagRespData1 : 15|8@0+ (1,0) [0|255] "" MHU
  SG_ EPS_DiagRespData2 : 23|8@0+ (1,0) [0|255] "" MHU
  SG_ EPS_DiagRespData3 : 31|8@0+ (1,0) [0|255] "-" MHU
  SG_ EPS_DiagRespData4 : 39|8@0+ (1,0) [0|255] "" MHU
  SG_ EPS_DiagRespData5 : 47|8@0+ (1,0) [0|255] "" MHU
  SG_ EPS_DiagRespData6 : 55|8@0+ (1,0) [0|255] "-" MHU
  SG_ EPS_DiagRespData7 : 63|8@0+ (1,0) [0|255] "-" MHU

BO_ 1577 IDB_DiagResp: 8 XGW_Info
  SG_ IDB_DiagRespData0 : 7|8@0+ (1,0) [0|255] "" MHU
  SG_ IDB_DiagRespData1 : 15|8@0+ (1,0) [0|255] "-" MHU
  SG_ IDB_DiagRespData2 : 23|8@0+ (1,0) [0|255] "-" MHU
  SG_ IDB_DiagRespData3 : 31|8@0+ (1,0) [0|255] "" MHU
  SG_ IDB_DiagRespData4 : 39|8@0+ (1,0) [0|255] "" MHU
  SG_ IDB_DiagRespData5 : 47|8@0+ (1,0) [0|255] "-" MHU
  SG_ IDB_DiagRespData6 : 55|8@0+ (1,0) [0|255] "-" MHU
  SG_ IDB_DiagRespData7 : 63|8@0+ (1,0) [0|255] "" MHU

BO_ 1578 AVAS_DiagResp: 8 XGW_Info
  SG_ AVAS_DiagRespData0 : 7|8@0+ (1,0) [0|255] "" MHU
  SG_ AVAS_DiagRespData1 : 15|8@0+ (1,0) [0|255] "" MHU
  SG_ AVAS_DiagRespData2 : 23|8@0+ (1,0) [0|255] "" MHU
  SG_ AVAS_DiagRespData3 : 31|8@0+ (1,0) [0|255] "" MHU
  SG_ AVAS_DiagRespData4 : 39|8@0+ (1,0) [0|255] "" MHU
  SG_ AVAS_DiagRespData5 : 47|8@0+ (1,0) [0|255] "" MHU
  SG_ AVAS_DiagRespData6 : 55|8@0+ (1,0) [0|255] "" MHU
  SG_ AVAS_DiagRespData7 : 63|8@0+ (1,0) [0|255] "-" MHU

BO_ 1579 EPS2_DiagResp: 8 XGW_Info
  SG_ EPS2_DiagRespData0 : 7|8@0+ (1,0) [0|255] "" MHU
  SG_ EPS2_DiagRespData1 : 15|8@0+ (1,0) [0|255] "-" MHU
  SG_ EPS2_DiagRespData2 : 23|8@0+ (1,0) [0|255] "-" MHU
  SG_ EPS2_DiagRespData3 : 31|8@0+ (1,0) [0|255] "" MHU
  SG_ EPS2_DiagRespData4 : 39|8@0+ (1,0) [0|255] "-" MHU
  SG_ EPS2_DiagRespData5 : 47|8@0+ (1,0) [0|255] "" MHU
  SG_ EPS2_DiagRespData6 : 55|8@0+ (1,0) [0|255] "-" MHU
  SG_ EPS2_DiagRespData7 : 63|8@0+ (1,0) [0|255] "-" MHU

BO_ 1580 VCU_DiagResp: 8 XGW_Info
  SG_ VCU_DiagRespData0 : 7|8@0+ (1,0) [0|255] "" MHU
  SG_ VCU_DiagRespData1 : 15|8@0+ (1,0) [0|255] "" MHU
  SG_ VCU_DiagRespData2 : 23|8@0+ (1,0) [0|255] "" MHU
  SG_ VCU_DiagRespData3 : 31|8@0+ (1,0) [0|255] "" MHU
  SG_ VCU_DiagRespData4 : 39|8@0+ (1,0) [0|255] "-" MHU
  SG_ VCU_DiagRespData5 : 47|8@0+ (1,0) [0|255] "" MHU
  SG_ VCU_DiagRespData6 : 55|8@0+ (1,0) [0|255] "" MHU
  SG_ VCU_DiagRespData7 : 63|8@0+ (1,0) [0|255] "-" MHU

BO_ 1582 EASC_DiagResp: 8 EASC
  SG_ EASC_DiagRespData0 : 7|8@0+ (1,0) [0|255] "-" MHU
  SG_ EASC_DiagRespData1 : 15|8@0+ (1,0) [0|255] "-" MHU
  SG_ EASC_DiagRespData2 : 23|8@0+ (1,0) [0|255] "-" MHU
  SG_ EASC_DiagRespData3 : 31|8@0+ (1,0) [0|255] "" MHU
  SG_ EASC_DiagRespData4 : 39|8@0+ (1,0) [0|255] "" MHU
  SG_ EASC_DiagRespData5 : 47|8@0+ (1,0) [0|255] "" MHU
  SG_ EASC_DiagRespData6 : 55|8@0+ (1,0) [0|255] "" MHU
  SG_ EASC_DiagRespData7 : 63|8@0+ (1,0) [0|255] "" MHU

BO_ 1583 CPD_DiagResp: 8 CPD
  SG_ CPD_DiagRespData0 : 7|8@0+ (1,0) [0|255] "-" MHU
  SG_ CPD_DiagRespData1 : 15|8@0+ (1,0) [0|255] "-" MHU
  SG_ CPD_DiagRespData2 : 23|8@0+ (1,0) [0|255] "" MHU
  SG_ CPD_DiagRespData3 : 31|8@0+ (1,0) [0|255] "-" MHU
  SG_ CPD_DiagRespData4 : 39|8@0+ (1,0) [0|255] "-" MHU
  SG_ CPD_DiagRespData5 : 47|8@0+ (1,0) [0|255] "" MHU
  SG_ CPD_DiagRespData6 : 55|8@0+ (1,0) [0|255] "-" MHU
  SG_ CPD_DiagRespData7 : 63|8@0+ (1,0) [0|255] "" MHU

BO_ 1588 SRR_FR_DiagResp: 8 XGW_Info
  SG_ SRR_FR_DiagRespData0 : 7|8@0+ (1,0) [0|255] "-" MHU
  SG_ SRR_FR_DiagRespData1 : 15|8@0+ (1,0) [0|255] "-" MHU
  SG_ SRR_FR_DiagRespData2 : 23|8@0+ (1,0) [0|255] "-" MHU
  SG_ SRR_FR_DiagRespData3 : 31|8@0+ (1,0) [0|255] "" MHU
  SG_ SRR_FR_DiagRespData4 : 39|8@0+ (1,0) [0|255] "" MHU
  SG_ SRR_FR_DiagRespData5 : 47|8@0+ (1,0) [0|255] "" MHU
  SG_ SRR_FR_DiagRespData6 : 55|8@0+ (1,0) [0|255] "" MHU
  SG_ SRR_FR_DiagRespData7 : 63|8@0+ (1,0) [0|255] "" MHU

BO_ 1589 SRR_FL_DiagResp: 8 XGW_Info
  SG_ SRR_FL_DiagRespData0 : 7|8@0+ (1,0) [0|255] "" MHU
  SG_ SRR_FL_DiagRespData1 : 15|8@0+ (1,0) [0|255] "-" MHU
  SG_ SRR_FL_DiagRespData2 : 23|8@0+ (1,0) [0|255] "" MHU
  SG_ SRR_FL_DiagRespData3 : 31|8@0+ (1,0) [0|255] "-" MHU
  SG_ SRR_FL_DiagRespData4 : 39|8@0+ (1,0) [0|255] "" MHU
  SG_ SRR_FL_DiagRespData5 : 47|8@0+ (1,0) [0|255] "-" MHU
  SG_ SRR_FL_DiagRespData6 : 55|8@0+ (1,0) [0|255] "-" MHU
  SG_ SRR_FL_DiagRespData7 : 63|8@0+ (1,0) [0|255] "" MHU

BO_ 1590 SRR_RR_DiagResp: 8 XGW_Info
  SG_ SRR_RR_DiagRespData0 : 7|8@0+ (1,0) [0|255] "" MHU
  SG_ SRR_RR_DiagRespData1 : 15|8@0+ (1,0) [0|255] "-" MHU
  SG_ SRR_RR_DiagRespData2 : 23|8@0+ (1,0) [0|255] "-" MHU
  SG_ SRR_RR_DiagRespData3 : 31|8@0+ (1,0) [0|255] "" MHU
  SG_ SRR_RR_DiagRespData4 : 39|8@0+ (1,0) [0|255] "-" MHU
  SG_ SRR_RR_DiagRespData5 : 47|8@0+ (1,0) [0|255] "-" MHU
  SG_ SRR_RR_DiagRespData6 : 55|8@0+ (1,0) [0|255] "-" MHU
  SG_ SRR_RR_DiagRespData7 : 63|8@0+ (1,0) [0|255] "-" MHU

BO_ 1591 SRR_RL_DiagResp: 8 XGW_Info
  SG_ SRR_RL_DiagRespData0 : 7|8@0+ (1,0) [0|255] "" MHU
  SG_ SRR_RL_DiagRespData1 : 15|8@0+ (1,0) [0|255] "-" MHU
  SG_ SRR_RL_DiagRespData2 : 23|8@0+ (1,0) [0|255] "-" MHU
  SG_ SRR_RL_DiagRespData3 : 31|8@0+ (1,0) [0|255] "-" MHU
  SG_ SRR_RL_DiagRespData4 : 39|8@0+ (1,0) [0|255] "" MHU
  SG_ SRR_RL_DiagRespData5 : 47|8@0+ (1,0) [0|255] "-" MHU
  SG_ SRR_RL_DiagRespData6 : 55|8@0+ (1,0) [0|255] "-" MHU
  SG_ SRR_RL_DiagRespData7 : 63|8@0+ (1,0) [0|255] "-" MHU

BO_ 1592 ASU_DiagResp: 8 XGW_Info
  SG_ ASU_DiagRespData0 : 7|8@0+ (1,0) [0|255] "-" MHU
  SG_ ASU_DiagRespData1 : 15|8@0+ (1,0) [0|255] "-" MHU
  SG_ ASU_DiagRespData2 : 23|8@0+ (1,0) [0|255] "-" MHU
  SG_ ASU_DiagRespData3 : 31|8@0+ (1,0) [0|255] "-" MHU
  SG_ ASU_DiagRespData4 : 39|8@0+ (1,0) [0|255] "-" MHU
  SG_ ASU_DiagRespData5 : 47|8@0+ (1,0) [0|255] "-" MHU
  SG_ ASU_DiagRespData6 : 55|8@0+ (1,0) [0|255] "-" MHU
  SG_ ASU_DiagRespData7 : 63|8@0+ (1,0) [0|255] "-" MHU

BO_ 1595 TRM_DiagResp: 8 XGW_Info
  SG_ TRM_DiagRespData0 : 7|8@0+ (1,0) [0|255] "" MHU
  SG_ TRM_DiagRespData1 : 15|8@0+ (1,0) [0|255] "" MHU
  SG_ TRM_DiagRespData2 : 23|8@0+ (1,0) [0|255] "" MHU
  SG_ TRM_DiagRespData3 : 31|8@0+ (1,0) [0|255] "-" MHU
  SG_ TRM_DiagRespData4 : 39|8@0+ (1,0) [0|255] "-" MHU
  SG_ TRM_DiagRespData5 : 47|8@0+ (1,0) [0|255] "-" MHU
  SG_ TRM_DiagRespData6 : 55|8@0+ (1,0) [0|255] "" MHU
  SG_ TRM_DiagRespData7 : 63|8@0+ (1,0) [0|255] "-" MHU

BO_ 1597 POD_DCDC_DiagResp: 8 XGW_Info
  SG_ POD_DCDC_DiagRespData0 : 7|8@0+ (1,0) [0|255] "" MHU
  SG_ POD_DCDC_DiagRespData1 : 15|8@0+ (1,0) [0|255] "" MHU
  SG_ POD_DCDC_DiagRespData2 : 23|8@0+ (1,0) [0|255] "-" MHU
  SG_ POD_DCDC_DiagRespData3 : 31|8@0+ (1,0) [0|255] "-" MHU
  SG_ POD_DCDC_DiagRespData4 : 39|8@0+ (1,0) [0|255] "" MHU
  SG_ POD_DCDC_DiagRespData5 : 47|8@0+ (1,0) [0|255] "" MHU
  SG_ POD_DCDC_DiagRespData6 : 55|8@0+ (1,0) [0|255] "-" MHU
  SG_ POD_DCDC_DiagRespData7 : 63|8@0+ (1,0) [0|255] "" MHU

BO_ 1598 POD_OBC_DiagResp: 8 XGW_Info
  SG_ POD_OBC_DiagRespData0 : 7|8@0+ (1,0) [0|255] "" MHU
  SG_ POD_OBC_DiagRespData1 : 15|8@0+ (1,0) [0|255] "-" MHU
  SG_ POD_OBC_DiagRespData2 : 23|8@0+ (1,0) [0|255] "" MHU
  SG_ POD_OBC_DiagRespData3 : 31|8@0+ (1,0) [0|255] "-" MHU
  SG_ POD_OBC_DiagRespData4 : 39|8@0+ (1,0) [0|255] "" MHU
  SG_ POD_OBC_DiagRespData5 : 47|8@0+ (1,0) [0|255] "-" MHU
  SG_ POD_OBC_DiagRespData6 : 55|8@0+ (1,0) [0|255] "" MHU
  SG_ POD_OBC_DiagRespData7 : 63|8@0+ (1,0) [0|255] "-" MHU

BO_ 1599 POD_GW_Response: 8 XGW_Info
  SG_ POD_DiagRespData0 : 7|8@0+ (1,0) [0|255] "-" MHU
  SG_ POD_DiagRespData1 : 15|8@0+ (1,0) [0|255] "" MHU
  SG_ POD_DiagRespData2 : 23|8@0+ (1,0) [0|255] "" MHU
  SG_ POD_DiagRespData3 : 31|8@0+ (1,0) [0|255] "-" MHU
  SG_ POD_DiagRespData4 : 39|8@0+ (1,0) [0|255] "-" MHU
  SG_ POD_DiagRespData5 : 47|8@0+ (1,0) [0|255] "-" MHU
  SG_ POD_DiagRespData6 : 55|8@0+ (1,0) [0|255] "" MHU
  SG_ POD_DiagRespData7 : 63|8@0+ (1,0) [0|255] "" MHU

BO_ 1600 ADAS_DiagResp: 8 XGW_Info
  SG_ ADAS_DiagRespData0 : 7|8@0+ (1,0) [0|255] "" MHU
  SG_ ADAS_DiagRespData1 : 15|8@0+ (1,0) [0|255] "" MHU
  SG_ ADAS_DiagRespData2 : 23|8@0+ (1,0) [0|255] "" MHU
  SG_ ADAS_DiagRespData3 : 31|8@0+ (1,0) [0|255] "" MHU
  SG_ ADAS_DiagRespData4 : 39|8@0+ (1,0) [0|255] "" MHU
  SG_ ADAS_DiagRespData5 : 47|8@0+ (1,0) [0|255] "" MHU
  SG_ ADAS_DiagRespData6 : 55|8@0+ (1,0) [0|255] "" MHU
  SG_ ADAS_DiagRespData7 : 63|8@0+ (1,0) [0|255] "" MHU

BO_ 1601 APM_DiagResp: 8 XGW_Info
  SG_ APM_DiagRespData0 : 7|8@0+ (1,0) [0|255] "" MHU
  SG_ APM_DiagRespData1 : 15|8@0+ (1,0) [0|255] "" MHU
  SG_ APM_DiagRespData2 : 23|8@0+ (1,0) [0|255] "" MHU
  SG_ APM_DiagRespData3 : 31|8@0+ (1,0) [0|255] "" MHU
  SG_ APM_DiagRespData4 : 39|8@0+ (1,0) [0|255] "-" MHU
  SG_ APM_DiagRespData5 : 47|8@0+ (1,0) [0|255] "" MHU
  SG_ APM_DiagRespData6 : 55|8@0+ (1,0) [0|255] "-" MHU
  SG_ APM_DiagRespData7 : 63|8@0+ (1,0) [0|255] "" MHU

BO_ 1602 SHVU_F_DiagResp: 8 XGW_Info
  SG_ SHVU_F_DiagRespData0 : 7|8@0+ (1,0) [0|255] "" MHU
  SG_ SHVU_F_DiagRespData1 : 15|8@0+ (1,0) [0|255] "" MHU
  SG_ SHVU_F_DiagRespData2 : 23|8@0+ (1,0) [0|255] "-" MHU
  SG_ SHVU_F_DiagRespData3 : 31|8@0+ (1,0) [0|255] "" MHU
  SG_ SHVU_F_DiagRespData4 : 39|8@0+ (1,0) [0|255] "" MHU
  SG_ SHVU_F_DiagRespData5 : 47|8@0+ (1,0) [0|255] "" MHU
  SG_ SHVU_F_DiagRespData6 : 55|8@0+ (1,0) [0|255] "-" MHU
  SG_ SHVU_F_DiagRespData7 : 63|8@0+ (1,0) [0|255] "" MHU

BO_ 1603 SHVU_R_DiagResp: 8 XGW_Info
  SG_ SHVU_R_DiagRespData0 : 7|8@0+ (1,0) [0|255] "" MHU
  SG_ SHVU_R_DiagRespData1 : 15|8@0+ (1,0) [0|255] "-" MHU
  SG_ SHVU_R_DiagRespData2 : 23|8@0+ (1,0) [0|255] "" MHU
  SG_ SHVU_R_DiagRespData3 : 31|8@0+ (1,0) [0|255] "-" MHU
  SG_ SHVU_R_DiagRespData4 : 39|8@0+ (1,0) [0|255] "-" MHU
  SG_ SHVU_R_DiagRespData5 : 47|8@0+ (1,0) [0|255] "" MHU
  SG_ SHVU_R_DiagRespData6 : 55|8@0+ (1,0) [0|255] "-" MHU
  SG_ SHVU_R_DiagRespData7 : 63|8@0+ (1,0) [0|255] "" MHU

BO_ 1604 OCS_P_DiagResp: 8 XGW_Info
  SG_ OCS_P_DiagRespData0 : 7|8@0+ (1,0) [0|255] "" MHU
  SG_ OCS_P_DiagRespData1 : 15|8@0+ (1,0) [0|255] "-" MHU
  SG_ OCS_P_DiagRespData2 : 23|8@0+ (1,0) [0|255] "" MHU
  SG_ OCS_P_DiagRespData3 : 31|8@0+ (1,0) [0|255] "-" MHU
  SG_ OCS_P_DiagRespData4 : 39|8@0+ (1,0) [0|255] "" MHU
  SG_ OCS_P_DiagRespData5 : 47|8@0+ (1,0) [0|255] "" MHU
  SG_ OCS_P_DiagRespData6 : 55|8@0+ (1,0) [0|255] "" MHU
  SG_ OCS_P_DiagRespData7 : 63|8@0+ (1,0) [0|255] "" MHU

BO_ 1609 LDM_L_DiagResp: 8 XGW_Info
  SG_ LDM_L_DiagRespData0 : 7|8@0+ (1,0) [0|255] "-" MHU
  SG_ LDM_L_DiagRespData1 : 15|8@0+ (1,0) [0|255] "" MHU
  SG_ LDM_L_DiagRespData2 : 23|8@0+ (1,0) [0|255] "-" MHU
  SG_ LDM_L_DiagRespData3 : 31|8@0+ (1,0) [0|255] "" MHU
  SG_ LDM_L_DiagRespData4 : 39|8@0+ (1,0) [0|255] "" MHU
  SG_ LDM_L_DiagRespData5 : 47|8@0+ (1,0) [0|255] "-" MHU
  SG_ LDM_L_DiagRespData6 : 55|8@0+ (1,0) [0|255] "" MHU
  SG_ LDM_L_DiagRespData7 : 63|8@0+ (1,0) [0|255] "-" MHU

BO_ 1610 LDM_R_DiagResp: 8 XGW_Info
  SG_ LDM_R_DiagRespData0 : 7|8@0+ (1,0) [0|255] "" MHU
  SG_ LDM_R_DiagRespData1 : 15|8@0+ (1,0) [0|255] "-" MHU
  SG_ LDM_R_DiagRespData2 : 23|8@0+ (1,0) [0|255] "" MHU
  SG_ LDM_R_DiagRespData3 : 31|8@0+ (1,0) [0|255] "" MHU
  SG_ LDM_R_DiagRespData4 : 39|8@0+ (1,0) [0|255] "-" MHU
  SG_ LDM_R_DiagRespData5 : 47|8@0+ (1,0) [0|255] "" MHU
  SG_ LDM_R_DiagRespData6 : 55|8@0+ (1,0) [0|255] "" MHU
  SG_ LDM_R_DiagRespData7 : 63|8@0+ (1,0) [0|255] "-" MHU

BO_ 1624 BAS_DiagResp: 8 XGW_Info
 SG_ BAS_DiagRespData0 : 7|8@0+ (1,0) [0|255] ""  MHU
 SG_ BAS_DiagRespData1 : 15|8@0+ (1,0) [0|255] ""  MHU
 SG_ BAS_DiagRespData2 : 23|8@0+ (1,0) [0|255] ""  MHU
 SG_ BAS_DiagRespData3 : 31|8@0+ (1,0) [0|255] ""  MHU
 SG_ BAS_DiagRespData4 : 39|8@0+ (1,0) [0|255] ""  MHU
 SG_ BAS_DiagRespData5 : 47|8@0+ (1,0) [0|255] ""  MHU
 SG_ BAS_DiagRespData6 : 55|8@0+ (1,0) [0|255] ""  MHU
 SG_ BAS_DiagRespData7 : 63|8@0+ (1,0) [0|255] ""  MHU

BO_ 1636 DCM_APM_DiagResp: 8 XGW_Info
  SG_ DCM_APM_DiagRespData0 : 7|8@0+ (1,0) [0|255] "-" MHU
  SG_ DCM_APM_DiagRespData1 : 15|8@0+ (1,0) [0|255] "-" MHU
  SG_ DCM_APM_DiagRespData2 : 23|8@0+ (1,0) [0|255] "" MHU
  SG_ DCM_APM_DiagRespData3 : 31|8@0+ (1,0) [0|255] "-" MHU
  SG_ DCM_APM_DiagRespData4 : 39|8@0+ (1,0) [0|255] "" MHU
  SG_ DCM_APM_DiagRespData5 : 47|8@0+ (1,0) [0|255] "-" MHU
  SG_ DCM_APM_DiagRespData6 : 55|8@0+ (1,0) [0|255] "-" MHU
  SG_ DCM_APM_DiagRespData7 : 63|8@0+ (1,0) [0|255] "" MHU

BO_ 1659 BCM_BPM_DiagResp: 8 XGW_Info
  SG_ BCM_BPM_DiagRespData0 : 7|8@0+ (1,0) [0|255] "" MHU
  SG_ BCM_BPM_DiagRespData1 : 15|8@0+ (1,0) [0|255] "-" MHU
  SG_ BCM_BPM_DiagRespData2 : 23|8@0+ (1,0) [0|255] "" MHU
  SG_ BCM_BPM_DiagRespData3 : 31|8@0+ (1,0) [0|255] "" MHU
  SG_ BCM_BPM_DiagRespData4 : 39|8@0+ (1,0) [0|255] "-" MHU
  SG_ BCM_BPM_DiagRespData5 : 47|8@0+ (1,0) [0|255] "" MHU
  SG_ BCM_BPM_DiagRespData6 : 55|8@0+ (1,0) [0|255] "-" MHU
  SG_ BCM_BPM_DiagRespData7 : 63|8@0+ (1,0) [0|255] "" MHU

BO_ 1665 BCM_DiagReq: 8 MHU
  SG_ BCM_DiagReqData0 : 7|8@0+ (1,0) [0|255] "" XGW_Info
  SG_ BCM_DiagReqData1 : 15|8@0+ (1,0) [0|255] "" XGW_Info
  SG_ BCM_DiagReqData2 : 23|8@0+ (1,0) [0|255] "" XGW_Info
  SG_ BCM_DiagReqData3 : 31|8@0+ (1,0) [0|255] "" XGW_Info
  SG_ BCM_DiagReqData4 : 39|8@0+ (1,0) [0|255] "" XGW_Info
  SG_ BCM_DiagReqData5 : 47|8@0+ (1,0) [0|255] "" XGW_Info
  SG_ BCM_DiagReqData6 : 55|8@0+ (1,0) [0|255] "-" XGW_Info
  SG_ BCM_DiagReqData7 : 63|8@0+ (1,0) [0|255] "-" XGW_Info

BO_ 1666 XGW_DiagReq: 8 MHU
  SG_ XGW_DiagReqData0 : 7|8@0+ (1,0) [0|255] "" XGW_Info
  SG_ XGW_DiagReqData1 : 15|8@0+ (1,0) [0|255] "" XGW_Info
  SG_ XGW_DiagReqData2 : 23|8@0+ (1,0) [0|255] "-" XGW_Info
  SG_ XGW_DiagReqData3 : 31|8@0+ (1,0) [0|255] "-" XGW_Info
  SG_ XGW_DiagReqData4 : 39|8@0+ (1,0) [0|255] "" XGW_Info
  SG_ XGW_DiagReqData5 : 47|8@0+ (1,0) [0|255] "" XGW_Info
  SG_ XGW_DiagReqData6 : 55|8@0+ (1,0) [0|255] "" XGW_Info
  SG_ XGW_DiagReqData7 : 63|8@0+ (1,0) [0|255] "" XGW_Info

BO_ 1668 MHU_DiagReq: 8 XGW_Info
  SG_ MHU_DiagReqData0 : 7|8@0+ (1,0) [0|255] "" MHU
  SG_ MHU_DiagReqData1 : 15|8@0+ (1,0) [0|255] "" MHU
  SG_ MHU_DiagReqData2 : 23|8@0+ (1,0) [0|255] "-" MHU
  SG_ MHU_DiagReqData3 : 31|8@0+ (1,0) [0|255] "-" MHU
  SG_ MHU_DiagReqData4 : 39|8@0+ (1,0) [0|255] "" MHU
  SG_ MHU_DiagReqData5 : 47|8@0+ (1,0) [0|255] "-" MHU
  SG_ MHU_DiagReqData6 : 55|8@0+ (1,0) [0|255] "-" MHU
  SG_ MHU_DiagReqData7 : 63|8@0+ (1,0) [0|255] "-" MHU

BO_ 1669 AMP_DiagReq: 8 MHU
  SG_ AMP_DiagReqData0 : 7|8@0+ (1,0) [0|255] "" AMP
  SG_ AMP_DiagReqData1 : 15|8@0+ (1,0) [0|255] "-" AMP
  SG_ AMP_DiagReqData2 : 23|8@0+ (1,0) [0|255] "" AMP
  SG_ AMP_DiagReqData3 : 31|8@0+ (1,0) [0|255] "" AMP
  SG_ AMP_DiagReqData4 : 39|8@0+ (1,0) [0|255] "" AMP
  SG_ AMP_DiagReqData5 : 47|8@0+ (1,0) [0|255] "-" AMP
  SG_ AMP_DiagReqData6 : 55|8@0+ (1,0) [0|255] "-" AMP
  SG_ AMP_DiagReqData7 : 63|8@0+ (1,0) [0|255] "" AMP

BO_ 1672 ACM_DiagReq: 8 MHU
  SG_ ACM_DiagReqData0 : 7|8@0+ (1,0) [0|255] "" XGW_Info
  SG_ ACM_DiagReqData1 : 15|8@0+ (1,0) [0|255] "" XGW_Info
  SG_ ACM_DiagReqData2 : 23|8@0+ (1,0) [0|255] "" XGW_Info
  SG_ ACM_DiagReqData3 : 31|8@0+ (1,0) [0|255] "-" XGW_Info
  SG_ ACM_DiagReqData4 : 39|8@0+ (1,0) [0|255] "" XGW_Info
  SG_ ACM_DiagReqData5 : 47|8@0+ (1,0) [0|255] "" XGW_Info
  SG_ ACM_DiagReqData6 : 55|8@0+ (1,0) [0|255] "-" XGW_Info
  SG_ ACM_DiagReqData7 : 63|8@0+ (1,0) [0|255] "" XGW_Info

BO_ 1673 CCUF_DiagReq: 8 MHU
  SG_ CCUF_DiagReqData0 : 7|8@0+ (1,0) [0|255] "-" XGW_Info
  SG_ CCUF_DiagReqData1 : 15|8@0+ (1,0) [0|255] "" XGW_Info
  SG_ CCUF_DiagReqData2 : 23|8@0+ (1,0) [0|255] "" XGW_Info
  SG_ CCUF_DiagReqData3 : 31|8@0+ (1,0) [0|255] "" XGW_Info
  SG_ CCUF_DiagReqData4 : 39|8@0+ (1,0) [0|255] "" XGW_Info
  SG_ CCUF_DiagReqData5 : 47|8@0+ (1,0) [0|255] "" XGW_Info
  SG_ CCUF_DiagReqData6 : 55|8@0+ (1,0) [0|255] "" XGW_Info
  SG_ CCUF_DiagReqData7 : 63|8@0+ (1,0) [0|255] "" XGW_Info

BO_ 1677 HUD_DiagReq: 8 MHU
  SG_ HUD_DiagReqData0 : 7|8@0+ (1,0) [0|255] "-" HUD
  SG_ HUD_DiagReqData1 : 15|8@0+ (1,0) [0|255] "" HUD
  SG_ HUD_DiagReqData2 : 23|8@0+ (1,0) [0|255] "-" HUD
  SG_ HUD_DiagReqData3 : 31|8@0+ (1,0) [0|255] "" HUD
  SG_ HUD_DiagReqData4 : 39|8@0+ (1,0) [0|255] "-" HUD
  SG_ HUD_DiagReqData5 : 47|8@0+ (1,0) [0|255] "-" HUD
  SG_ HUD_DiagReqData6 : 55|8@0+ (1,0) [0|255] "" HUD
  SG_ HUD_DiagReqData7 : 63|8@0+ (1,0) [0|255] "" HUD

BO_ 1678 ETG_DiagReq: 8 MHU
  SG_ ETG_DiagReqData0 : 7|8@0+ (1,0) [0|255] "" XGW_Info
  SG_ ETG_DiagReqData1 : 15|8@0+ (1,0) [0|255] "" XGW_Info
  SG_ ETG_DiagReqData2 : 23|8@0+ (1,0) [0|255] "" XGW_Info
  SG_ ETG_DiagReqData3 : 31|8@0+ (1,0) [0|255] "" XGW_Info
  SG_ ETG_DiagReqData4 : 39|8@0+ (1,0) [0|255] "" XGW_Info
  SG_ ETG_DiagReqData5 : 47|8@0+ (1,0) [0|255] "" XGW_Info
  SG_ ETG_DiagReqData6 : 55|8@0+ (1,0) [0|255] "" XGW_Info
  SG_ ETG_DiagReqData7 : 63|8@0+ (1,0) [0|255] "-" XGW_Info

BO_ 1679 YSS_DiagReq: 8 MHU
  SG_ YSS_DiagReqData0 : 7|8@0+ (1,0) [0|255] "" XGW_Info
  SG_ YSS_DiagReqData1 : 15|8@0+ (1,0) [0|255] "" XGW_Info
  SG_ YSS_DiagReqData2 : 23|8@0+ (1,0) [0|255] "-" XGW_Info
  SG_ YSS_DiagReqData3 : 31|8@0+ (1,0) [0|255] "-" XGW_Info
  SG_ YSS_DiagReqData4 : 39|8@0+ (1,0) [0|255] "-" XGW_Info
  SG_ YSS_DiagReqData5 : 47|8@0+ (1,0) [0|255] "-" XGW_Info
  SG_ YSS_DiagReqData6 : 55|8@0+ (1,0) [0|255] "" XGW_Info
  SG_ YSS_DiagReqData7 : 63|8@0+ (1,0) [0|255] "" XGW_Info

BO_ 1680 GS_DiagReq: 8 MHU
  SG_ GS_DiagReqData0 : 7|8@0+ (1,0) [0|255] "" XGW_Info
  SG_ GS_DiagReqData1 : 15|8@0+ (1,0) [0|255] "" XGW_Info
  SG_ GS_DiagReqData2 : 23|8@0+ (1,0) [0|255] "" XGW_Info
  SG_ GS_DiagReqData3 : 31|8@0+ (1,0) [0|255] "" XGW_Info
  SG_ GS_DiagReqData4 : 39|8@0+ (1,0) [0|255] "-" XGW_Info
  SG_ GS_DiagReqData5 : 47|8@0+ (1,0) [0|255] "" XGW_Info
  SG_ GS_DiagReqData6 : 55|8@0+ (1,0) [0|255] "" XGW_Info
  SG_ GS_DiagReqData7 : 63|8@0+ (1,0) [0|255] "" XGW_Info

BO_ 1683 BMS_DiagReq: 8 MHU
  SG_ BMS_DiagReqData0 : 7|8@0+ (1,0) [0|255] "" XGW_Info
  SG_ BMS_DiagReqData1 : 15|8@0+ (1,0) [0|255] "" XGW_Info
  SG_ BMS_DiagReqData2 : 23|8@0+ (1,0) [0|255] "" XGW_Info
  SG_ BMS_DiagReqData3 : 31|8@0+ (1,0) [0|255] "-" XGW_Info
  SG_ BMS_DiagReqData4 : 39|8@0+ (1,0) [0|255] "-" XGW_Info
  SG_ BMS_DiagReqData5 : 47|8@0+ (1,0) [0|255] "-" XGW_Info
  SG_ BMS_DiagReqData6 : 55|8@0+ (1,0) [0|255] "" XGW_Info
  SG_ BMS_DiagReqData7 : 63|8@0+ (1,0) [0|255] "" XGW_Info

BO_ 1684 CCUR_DiagReq: 8 MHU
  SG_ CCUR_DiagReqData0 : 7|8@0+ (1,0) [0|255] "" XGW_Info
  SG_ CCUR_DiagReqData1 : 15|8@0+ (1,0) [0|255] "" XGW_Info
  SG_ CCUR_DiagReqData2 : 23|8@0+ (1,0) [0|255] "" XGW_Info
  SG_ CCUR_DiagReqData3 : 31|8@0+ (1,0) [0|255] "-" XGW_Info
  SG_ CCUR_DiagReqData4 : 39|8@0+ (1,0) [0|255] "-" XGW_Info
  SG_ CCUR_DiagReqData5 : 47|8@0+ (1,0) [0|255] "" XGW_Info
  SG_ CCUR_DiagReqData6 : 55|8@0+ (1,0) [0|255] "" XGW_Info
  SG_ CCUR_DiagReqData7 : 63|8@0+ (1,0) [0|255] "" XGW_Info

BO_ 1690 EDS_R_DiagReq: 8 MHU
  SG_ EDS_R_DiagReqData0 : 7|8@0+ (1,0) [0|255] "" XGW_Info
  SG_ EDS_R_DiagReqData1 : 15|8@0+ (1,0) [0|255] "-" XGW_Info
  SG_ EDS_R_DiagReqData2 : 23|8@0+ (1,0) [0|255] "" XGW_Info
  SG_ EDS_R_DiagReqData3 : 31|8@0+ (1,0) [0|255] "-" XGW_Info
  SG_ EDS_R_DiagReqData4 : 39|8@0+ (1,0) [0|255] "-" XGW_Info
  SG_ EDS_R_DiagReqData5 : 47|8@0+ (1,0) [0|255] "" XGW_Info
  SG_ EDS_R_DiagReqData6 : 55|8@0+ (1,0) [0|255] "-" XGW_Info
  SG_ EDS_R_DiagReqData7 : 63|8@0+ (1,0) [0|255] "" XGW_Info

BO_ 1691 EDS_F_DiagReq: 8 MHU
  SG_ EDS_F_DiagReqData0 : 7|8@0+ (1,0) [0|255] "-" XGW_Info
  SG_ EDS_F_DiagReqData1 : 15|8@0+ (1,0) [0|255] "" XGW_Info
  SG_ EDS_F_DiagReqData2 : 23|8@0+ (1,0) [0|255] "-" XGW_Info
  SG_ EDS_F_DiagReqData3 : 31|8@0+ (1,0) [0|255] "" XGW_Info
  SG_ EDS_F_DiagReqData4 : 39|8@0+ (1,0) [0|255] "" XGW_Info
  SG_ EDS_F_DiagReqData5 : 47|8@0+ (1,0) [0|255] "" XGW_Info
  SG_ EDS_F_DiagReqData6 : 55|8@0+ (1,0) [0|255] "" XGW_Info
  SG_ EDS_F_DiagReqData7 : 63|8@0+ (1,0) [0|255] "" XGW_Info

BO_ 1694 PSM_D_DiagReq: 8 MHU
  SG_ PSM_D_DiagReqData0 : 7|8@0+ (1,0) [0|255] "-" XGW_Info
  SG_ PSM_D_DiagReqData1 : 15|8@0+ (1,0) [0|255] "" XGW_Info
  SG_ PSM_D_DiagReqData2 : 23|8@0+ (1,0) [0|255] "-" XGW_Info
  SG_ PSM_D_DiagReqData3 : 31|8@0+ (1,0) [0|255] "" XGW_Info
  SG_ PSM_D_DiagReqData4 : 39|8@0+ (1,0) [0|255] "" XGW_Info
  SG_ PSM_D_DiagReqData5 : 47|8@0+ (1,0) [0|255] "-" XGW_Info
  SG_ PSM_D_DiagReqData6 : 55|8@0+ (1,0) [0|255] "-" XGW_Info
  SG_ PSM_D_DiagReqData7 : 63|8@0+ (1,0) [0|255] "" XGW_Info

BO_ 1701 MRGEN_DiagReq: 8 MHU
  SG_ MRGEN_DiagReqData0 : 7|8@0+ (1,0) [0|255] "" XGW_Info
  SG_ MRGEN_DiagReqData1 : 15|8@0+ (1,0) [0|255] "" XGW_Info
  SG_ MRGEN_DiagReqData2 : 23|8@0+ (1,0) [0|255] "" XGW_Info
  SG_ MRGEN_DiagReqData3 : 31|8@0+ (1,0) [0|255] "" XGW_Info
  SG_ MRGEN_DiagReqData4 : 39|8@0+ (1,0) [0|255] "" XGW_Info
  SG_ MRGEN_DiagReqData5 : 47|8@0+ (1,0) [0|255] "-" XGW_Info
  SG_ MRGEN_DiagReqData6 : 55|8@0+ (1,0) [0|255] "" XGW_Info
  SG_ MRGEN_DiagReqData7 : 63|8@0+ (1,0) [0|255] "" XGW_Info

BO_ 1702 SCAM_DiagReq: 8 MHU
  SG_ SCAM_DiagReqData0 : 7|8@0+ (1,0) [0|255] "-" XGW_Info
  SG_ SCAM_DiagReqData1 : 15|8@0+ (1,0) [0|255] "" XGW_Info
  SG_ SCAM_DiagReqData2 : 23|8@0+ (1,0) [0|255] "-" XGW_Info
  SG_ SCAM_DiagReqData3 : 31|8@0+ (1,0) [0|255] "-" XGW_Info
  SG_ SCAM_DiagReqData4 : 39|8@0+ (1,0) [0|255] "" XGW_Info
  SG_ SCAM_DiagReqData5 : 47|8@0+ (1,0) [0|255] "-" XGW_Info
  SG_ SCAM_DiagReqData6 : 55|8@0+ (1,0) [0|255] "-" XGW_Info
  SG_ SCAM_DiagReqData7 : 63|8@0+ (1,0) [0|255] "-" XGW_Info

BO_ 1703 RCU_DiagReq: 8 MHU
  SG_ RCU_DiagReqData0 : 7|8@0+ (1,0) [0|255] "" XGW_Info
  SG_ RCU_DiagReqData1 : 15|8@0+ (1,0) [0|255] "" XGW_Info
  SG_ RCU_DiagReqData2 : 23|8@0+ (1,0) [0|255] "" XGW_Info
  SG_ RCU_DiagReqData3 : 31|8@0+ (1,0) [0|255] "" XGW_Info
  SG_ RCU_DiagReqData4 : 39|8@0+ (1,0) [0|255] "-" XGW_Info
  SG_ RCU_DiagReqData5 : 47|8@0+ (1,0) [0|255] "" XGW_Info
  SG_ RCU_DiagReqData6 : 55|8@0+ (1,0) [0|255] "-" XGW_Info
  SG_ RCU_DiagReqData7 : 63|8@0+ (1,0) [0|255] "-" XGW_Info

BO_ 1704 EPS_DiagReq: 8 MHU
  SG_ EPS_DiagReqData0 : 7|8@0+ (1,0) [0|255] "-" XGW_Info
  SG_ EPS_DiagReqData1 : 15|8@0+ (1,0) [0|255] "" XGW_Info
  SG_ EPS_DiagReqData2 : 23|8@0+ (1,0) [0|255] "" XGW_Info
  SG_ EPS_DiagReqData3 : 31|8@0+ (1,0) [0|255] "" XGW_Info
  SG_ EPS_DiagReqData4 : 39|8@0+ (1,0) [0|255] "-" XGW_Info
  SG_ EPS_DiagReqData5 : 47|8@0+ (1,0) [0|255] "-" XGW_Info
  SG_ EPS_DiagReqData6 : 55|8@0+ (1,0) [0|255] "-" XGW_Info
  SG_ EPS_DiagReqData7 : 63|8@0+ (1,0) [0|255] "" XGW_Info

BO_ 1705 IDB_DiagReq: 8 MHU
  SG_ IDB_DiagReqData0 : 7|8@0+ (1,0) [0|255] "" XGW_Info
  SG_ IDB_DiagReqData1 : 15|8@0+ (1,0) [0|255] "" XGW_Info
  SG_ IDB_DiagReqData2 : 23|8@0+ (1,0) [0|255] "" XGW_Info
  SG_ IDB_DiagReqData3 : 31|8@0+ (1,0) [0|255] "" XGW_Info
  SG_ IDB_DiagReqData4 : 39|8@0+ (1,0) [0|255] "" XGW_Info
  SG_ IDB_DiagReqData5 : 47|8@0+ (1,0) [0|255] "" XGW_Info
  SG_ IDB_DiagReqData6 : 55|8@0+ (1,0) [0|255] "-" XGW_Info
  SG_ IDB_DiagReqData7 : 63|8@0+ (1,0) [0|255] "" XGW_Info

BO_ 1706 AVAS_DiagReq: 8 MHU
  SG_ AVAS_DiagReqData0 : 7|8@0+ (1,0) [0|255] "-" XGW_Info
  SG_ AVAS_DiagReqData1 : 15|8@0+ (1,0) [0|255] "" XGW_Info
  SG_ AVAS_DiagReqData2 : 23|8@0+ (1,0) [0|255] "" XGW_Info
  SG_ AVAS_DiagReqData3 : 31|8@0+ (1,0) [0|255] "-" XGW_Info
  SG_ AVAS_DiagReqData4 : 39|8@0+ (1,0) [0|255] "" XGW_Info
  SG_ AVAS_DiagReqData5 : 47|8@0+ (1,0) [0|255] "" XGW_Info
  SG_ AVAS_DiagReqData6 : 55|8@0+ (1,0) [0|255] "" XGW_Info
  SG_ AVAS_DiagReqData7 : 63|8@0+ (1,0) [0|255] "" XGW_Info

BO_ 1707 EPS2_DiagReq: 8 MHU
  SG_ EPS2_DiagReqData0 : 7|8@0+ (1,0) [0|255] "" XGW_Info
  SG_ EPS2_DiagReqData1 : 15|8@0+ (1,0) [0|255] "" XGW_Info
  SG_ EPS2_DiagReqData2 : 23|8@0+ (1,0) [0|255] "" XGW_Info
  SG_ EPS2_DiagReqData3 : 31|8@0+ (1,0) [0|255] "-" XGW_Info
  SG_ EPS2_DiagReqData4 : 39|8@0+ (1,0) [0|255] "" XGW_Info
  SG_ EPS2_DiagReqData5 : 47|8@0+ (1,0) [0|255] "-" XGW_Info
  SG_ EPS2_DiagReqData6 : 55|8@0+ (1,0) [0|255] "" XGW_Info
  SG_ EPS2_DiagReqData7 : 63|8@0+ (1,0) [0|255] "" XGW_Info

BO_ 1708 VCU_DiagReq: 8 MHU
  SG_ VCU_DiagReqData0 : 7|8@0+ (1,0) [0|255] "-" XGW_Info
  SG_ VCU_DiagReqData1 : 15|8@0+ (1,0) [0|255] "" XGW_Info
  SG_ VCU_DiagReqData2 : 23|8@0+ (1,0) [0|255] "-" XGW_Info
  SG_ VCU_DiagReqData3 : 31|8@0+ (1,0) [0|255] "" XGW_Info
  SG_ VCU_DiagReqData4 : 39|8@0+ (1,0) [0|255] "" XGW_Info
  SG_ VCU_DiagReqData5 : 47|8@0+ (1,0) [0|255] "-" XGW_Info
  SG_ VCU_DiagReqData6 : 55|8@0+ (1,0) [0|255] "" XGW_Info
  SG_ VCU_DiagReqData7 : 63|8@0+ (1,0) [0|255] "-" XGW_Info

BO_ 1710 EASC_DiagReq: 8 MHU
  SG_ EASC_DiagReqData0 : 7|8@0+ (1,0) [0|255] "" EASC
  SG_ EASC_DiagReqData1 : 15|8@0+ (1,0) [0|255] "-" EASC
  SG_ EASC_DiagReqData2 : 23|8@0+ (1,0) [0|255] "-" EASC
  SG_ EASC_DiagReqData3 : 31|8@0+ (1,0) [0|255] "" EASC
  SG_ EASC_DiagReqData4 : 39|8@0+ (1,0) [0|255] "-" EASC
  SG_ EASC_DiagReqData5 : 47|8@0+ (1,0) [0|255] "-" EASC
  SG_ EASC_DiagReqData6 : 55|8@0+ (1,0) [0|255] "" EASC
  SG_ EASC_DiagReqData7 : 63|8@0+ (1,0) [0|255] "-" EASC

BO_ 1711 CPD_DiagReq: 8 MHU
  SG_ CPD_DiagReqData0 : 7|8@0+ (1,0) [0|255] "-" CPD
  SG_ CPD_DiagReqData1 : 15|8@0+ (1,0) [0|255] "-" CPD
  SG_ CPD_DiagReqData2 : 23|8@0+ (1,0) [0|255] "-" CPD
  SG_ CPD_DiagReqData3 : 31|8@0+ (1,0) [0|255] "" CPD
  SG_ CPD_DiagReqData4 : 39|8@0+ (1,0) [0|255] "-" CPD
  SG_ CPD_DiagReqData5 : 47|8@0+ (1,0) [0|255] "" CPD
  SG_ CPD_DiagReqData6 : 55|8@0+ (1,0) [0|255] "-" CPD
  SG_ CPD_DiagReqData7 : 63|8@0+ (1,0) [0|255] "-" CPD

BO_ 1716 SRR_FR_DiagReq: 8 MHU
  SG_ SRR_FR_DiagReqData0 : 7|8@0+ (1,0) [0|255] "" XGW_Info
  SG_ SRR_FR_DiagReqData1 : 15|8@0+ (1,0) [0|255] "" XGW_Info
  SG_ SRR_FR_DiagReqData2 : 23|8@0+ (1,0) [0|255] "" XGW_Info
  SG_ SRR_FR_DiagReqData3 : 31|8@0+ (1,0) [0|255] "" XGW_Info
  SG_ SRR_FR_DiagReqData4 : 39|8@0+ (1,0) [0|255] "" XGW_Info
  SG_ SRR_FR_DiagReqData5 : 47|8@0+ (1,0) [0|255] "" XGW_Info
  SG_ SRR_FR_DiagReqData6 : 55|8@0+ (1,0) [0|255] "" XGW_Info
  SG_ SRR_FR_DiagReqData7 : 63|8@0+ (1,0) [0|255] "" XGW_Info

BO_ 1717 SRR_FL_DiagReq: 8 MHU
  SG_ SRR_FL_DiagReqData0 : 7|8@0+ (1,0) [0|255] "" XGW_Info
  SG_ SRR_FL_DiagReqData1 : 15|8@0+ (1,0) [0|255] "" XGW_Info
  SG_ SRR_FL_DiagReqData2 : 23|8@0+ (1,0) [0|255] "" XGW_Info
  SG_ SRR_FL_DiagReqData3 : 31|8@0+ (1,0) [0|255] "" XGW_Info
  SG_ SRR_FL_DiagReqData4 : 39|8@0+ (1,0) [0|255] "" XGW_Info
  SG_ SRR_FL_DiagReqData5 : 47|8@0+ (1,0) [0|255] "" XGW_Info
  SG_ SRR_FL_DiagReqData6 : 55|8@0+ (1,0) [0|255] "" XGW_Info
  SG_ SRR_FL_DiagReqData7 : 63|8@0+ (1,0) [0|255] "" XGW_Info

BO_ 1718 SRR_RR_DiagReq: 8 MHU
  SG_ SRR_RR_DiagReqData0 : 7|8@0+ (1,0) [0|255] "" XGW_Info
  SG_ SRR_RR_DiagReqData1 : 15|8@0+ (1,0) [0|255] "" XGW_Info
  SG_ SRR_RR_DiagReqData2 : 23|8@0+ (1,0) [0|255] "" XGW_Info
  SG_ SRR_RR_DiagReqData3 : 31|8@0+ (1,0) [0|255] "" XGW_Info
  SG_ SRR_RR_DiagReqData4 : 39|8@0+ (1,0) [0|255] "" XGW_Info
  SG_ SRR_RR_DiagReqData5 : 47|8@0+ (1,0) [0|255] "" XGW_Info
  SG_ SRR_RR_DiagReqData6 : 55|8@0+ (1,0) [0|255] "" XGW_Info
  SG_ SRR_RR_DiagReqData7 : 63|8@0+ (1,0) [0|255] "" XGW_Info

BO_ 1719 SRR_RL_DiagReq: 8 MHU
  SG_ SRR_RL_DiagReqData0 : 7|8@0+ (1,0) [0|255] "" XGW_Info
  SG_ SRR_RL_DiagReqData1 : 15|8@0+ (1,0) [0|255] "" XGW_Info
  SG_ SRR_RL_DiagReqData2 : 23|8@0+ (1,0) [0|255] "" XGW_Info
  SG_ SRR_RL_DiagReqData3 : 31|8@0+ (1,0) [0|255] "" XGW_Info
  SG_ SRR_RL_DiagReqData4 : 39|8@0+ (1,0) [0|255] "" XGW_Info
  SG_ SRR_RL_DiagReqData5 : 47|8@0+ (1,0) [0|255] "" XGW_Info
  SG_ SRR_RL_DiagReqData6 : 55|8@0+ (1,0) [0|255] "" XGW_Info
  SG_ SRR_RL_DiagReqData7 : 63|8@0+ (1,0) [0|255] "" XGW_Info

BO_ 1723 TRM_DiagReq: 8 MHU
  SG_ TRM_DiagReqData0 : 7|8@0+ (1,0) [0|255] "" XGW_Info
  SG_ TRM_DiagReqData1 : 15|8@0+ (1,0) [0|255] "" XGW_Info
  SG_ TRM_DiagReqData2 : 23|8@0+ (1,0) [0|255] "-" XGW_Info
  SG_ TRM_DiagReqData3 : 31|8@0+ (1,0) [0|255] "-" XGW_Info
  SG_ TRM_DiagReqData4 : 39|8@0+ (1,0) [0|255] "-" XGW_Info
  SG_ TRM_DiagReqData5 : 47|8@0+ (1,0) [0|255] "" XGW_Info
  SG_ TRM_DiagReqData6 : 55|8@0+ (1,0) [0|255] "" XGW_Info
  SG_ TRM_DiagReqData7 : 63|8@0+ (1,0) [0|255] "-" XGW_Info

BO_ 1725 POD_DCDC_DiagReq: 8 MHU
  SG_ POD_DCDC_DiagReqData0 : 7|8@0+ (1,0) [0|255] "" XGW_Info
  SG_ POD_DCDC_DiagReqData1 : 15|8@0+ (1,0) [0|255] "" XGW_Info
  SG_ POD_DCDC_DiagReqData2 : 23|8@0+ (1,0) [0|255] "-" XGW_Info
  SG_ POD_DCDC_DiagReqData3 : 31|8@0+ (1,0) [0|255] "" XGW_Info
  SG_ POD_DCDC_DiagReqData4 : 39|8@0+ (1,0) [0|255] "-" XGW_Info
  SG_ POD_DCDC_DiagReqData5 : 47|8@0+ (1,0) [0|255] "-" XGW_Info
  SG_ POD_DCDC_DiagReqData6 : 55|8@0+ (1,0) [0|255] "" XGW_Info
  SG_ POD_DCDC_DiagReqData7 : 63|8@0+ (1,0) [0|255] "" XGW_Info

BO_ 1726 POD_OBC_DiagReq: 8 MHU
  SG_ POD_OBC_DiagReqData0 : 7|8@0+ (1,0) [0|255] "" XGW_Info
  SG_ POD_OBC_DiagReqData1 : 15|8@0+ (1,0) [0|255] "" XGW_Info
  SG_ POD_OBC_DiagReqData2 : 23|8@0+ (1,0) [0|255] "" XGW_Info
  SG_ POD_OBC_DiagReqData3 : 31|8@0+ (1,0) [0|255] "-" XGW_Info
  SG_ POD_OBC_DiagReqData4 : 39|8@0+ (1,0) [0|255] "" XGW_Info
  SG_ POD_OBC_DiagReqData5 : 47|8@0+ (1,0) [0|255] "" XGW_Info
  SG_ POD_OBC_DiagReqData6 : 55|8@0+ (1,0) [0|255] "" XGW_Info
  SG_ POD_OBC_DiagReqData7 : 63|8@0+ (1,0) [0|255] "-" XGW_Info

BO_ 1727 POD_GW_Request: 8 MHU
  SG_ POD_DiagReqData0 : 7|8@0+ (1,0) [0|255] "-" XGW_Info
  SG_ POD_DiagReqData1 : 15|8@0+ (1,0) [0|255] "" XGW_Info
  SG_ POD_DiagReqData2 : 23|8@0+ (1,0) [0|255] "" XGW_Info
  SG_ POD_DiagReqData3 : 31|8@0+ (1,0) [0|255] "" XGW_Info
  SG_ POD_DiagReqData4 : 39|8@0+ (1,0) [0|255] "" XGW_Info
  SG_ POD_DiagReqData5 : 47|8@0+ (1,0) [0|255] "" XGW_Info
  SG_ POD_DiagReqData6 : 55|8@0+ (1,0) [0|255] "" XGW_Info
  SG_ POD_DiagReqData7 : 63|8@0+ (1,0) [0|255] "" XGW_Info

BO_ 1728 ADAS_DiagReq: 8 MHU
  SG_ ADAS_DiagReqData0 : 7|8@0+ (1,0) [0|255] "" XGW_Info
  SG_ ADAS_DiagReqData1 : 15|8@0+ (1,0) [0|255] "" XGW_Info
  SG_ ADAS_DiagReqData2 : 23|8@0+ (1,0) [0|255] "" XGW_Info
  SG_ ADAS_DiagReqData3 : 31|8@0+ (1,0) [0|255] "" XGW_Info
  SG_ ADAS_DiagReqData4 : 39|8@0+ (1,0) [0|255] "" XGW_Info
  SG_ ADAS_DiagReqData5 : 47|8@0+ (1,0) [0|255] "" XGW_Info
  SG_ ADAS_DiagReqData6 : 55|8@0+ (1,0) [0|255] "" XGW_Info
  SG_ ADAS_DiagReqData7 : 63|8@0+ (1,0) [0|255] "" XGW_Info

BO_ 1729 APM_DiagReq: 8 MHU
  SG_ APM_DiagReqData0 : 7|8@0+ (1,0) [0|255] "" XGW_Info
  SG_ APM_DiagReqData1 : 15|8@0+ (1,0) [0|255] "" XGW_Info
  SG_ APM_DiagReqData2 : 23|8@0+ (1,0) [0|255] "-" XGW_Info
  SG_ APM_DiagReqData3 : 31|8@0+ (1,0) [0|255] "" XGW_Info
  SG_ APM_DiagReqData4 : 39|8@0+ (1,0) [0|255] "" XGW_Info
  SG_ APM_DiagReqData5 : 47|8@0+ (1,0) [0|255] "-" XGW_Info
  SG_ APM_DiagReqData6 : 55|8@0+ (1,0) [0|255] "" XGW_Info
  SG_ APM_DiagReqData7 : 63|8@0+ (1,0) [0|255] "" XGW_Info

BO_ 1730 SHVU_F_DiagReq: 8 MHU
  SG_ SHVU_F_DiagReqData0 : 7|8@0+ (1,0) [0|255] "" XGW_Info
  SG_ SHVU_F_DiagReqData1 : 15|8@0+ (1,0) [0|255] "" XGW_Info
  SG_ SHVU_F_DiagReqData2 : 23|8@0+ (1,0) [0|255] "" XGW_Info
  SG_ SHVU_F_DiagReqData3 : 31|8@0+ (1,0) [0|255] "-" XGW_Info
  SG_ SHVU_F_DiagReqData4 : 39|8@0+ (1,0) [0|255] "" XGW_Info
  SG_ SHVU_F_DiagReqData5 : 47|8@0+ (1,0) [0|255] "" XGW_Info
  SG_ SHVU_F_DiagReqData6 : 55|8@0+ (1,0) [0|255] "-" XGW_Info
  SG_ SHVU_F_DiagReqData7 : 63|8@0+ (1,0) [0|255] "" XGW_Info

BO_ 1731 SHVU_R_DiagReq: 8 MHU
  SG_ SHVU_R_DiagReqData0 : 7|8@0+ (1,0) [0|255] "" XGW_Info
  SG_ SHVU_R_DiagReqData1 : 15|8@0+ (1,0) [0|255] "" XGW_Info
  SG_ SHVU_R_DiagReqData2 : 23|8@0+ (1,0) [0|255] "" XGW_Info
  SG_ SHVU_R_DiagReqData3 : 31|8@0+ (1,0) [0|255] "" XGW_Info
  SG_ SHVU_R_DiagReqData4 : 39|8@0+ (1,0) [0|255] "" XGW_Info
  SG_ SHVU_R_DiagReqData5 : 47|8@0+ (1,0) [0|255] "-" XGW_Info
  SG_ SHVU_R_DiagReqData6 : 55|8@0+ (1,0) [0|255] "" XGW_Info
  SG_ SHVU_R_DiagReqData7 : 63|8@0+ (1,0) [0|255] "" XGW_Info

BO_ 1732 OCS_P_DiagReq: 8 MHU
  SG_ OCS_P_DiagReqData0 : 7|8@0+ (1,0) [0|255] "-" XGW_Info
  SG_ OCS_P_DiagReqData1 : 15|8@0+ (1,0) [0|255] "" XGW_Info
  SG_ OCS_P_DiagReqData2 : 23|8@0+ (1,0) [0|255] "" XGW_Info
  SG_ OCS_P_DiagReqData3 : 31|8@0+ (1,0) [0|255] "" XGW_Info
  SG_ OCS_P_DiagReqData4 : 39|8@0+ (1,0) [0|255] "" XGW_Info
  SG_ OCS_P_DiagReqData5 : 47|8@0+ (1,0) [0|255] "" XGW_Info
  SG_ OCS_P_DiagReqData6 : 55|8@0+ (1,0) [0|255] "" XGW_Info
  SG_ OCS_P_DiagReqData7 : 63|8@0+ (1,0) [0|255] "-" XGW_Info

BO_ 1737 LDM_L_DiagReq: 8 MHU
  SG_ LDM_L_DiagReqData0 : 7|8@0+ (1,0) [0|255] "-" XGW_Info
  SG_ LDM_L_DiagReqData1 : 15|8@0+ (1,0) [0|255] "" XGW_Info
  SG_ LDM_L_DiagReqData2 : 23|8@0+ (1,0) [0|255] "" XGW_Info
  SG_ LDM_L_DiagReqData3 : 31|8@0+ (1,0) [0|255] "" XGW_Info
  SG_ LDM_L_DiagReqData4 : 39|8@0+ (1,0) [0|255] "-" XGW_Info
  SG_ LDM_L_DiagReqData5 : 47|8@0+ (1,0) [0|255] "" XGW_Info
  SG_ LDM_L_DiagReqData6 : 55|8@0+ (1,0) [0|255] "" XGW_Info
  SG_ LDM_L_DiagReqData7 : 63|8@0+ (1,0) [0|255] "" XGW_Info

BO_ 1738 LDM_R_DiagReq: 8 MHU
  SG_ LDM_R_DiagReqData0 : 7|8@0+ (1,0) [0|255] "" XGW_Info
  SG_ LDM_R_DiagReqData1 : 15|8@0+ (1,0) [0|255] "" XGW_Info
  SG_ LDM_R_DiagReqData2 : 23|8@0+ (1,0) [0|255] "" XGW_Info
  SG_ LDM_R_DiagReqData3 : 31|8@0+ (1,0) [0|255] "-" XGW_Info
  SG_ LDM_R_DiagReqData4 : 39|8@0+ (1,0) [0|255] "" XGW_Info
  SG_ LDM_R_DiagReqData5 : 47|8@0+ (1,0) [0|255] "" XGW_Info
  SG_ LDM_R_DiagReqData6 : 55|8@0+ (1,0) [0|255] "-" XGW_Info
  SG_ LDM_R_DiagReqData7 : 63|8@0+ (1,0) [0|255] "-" XGW_Info

BO_ 1752 BAS_DiagReq: 8 MHU
 SG_ BAS_DiagReqData0 : 7|8@0+ (1,0) [0|255] ""  XGW_Info
 SG_ BAS_DiagReqData1 : 15|8@0+ (1,0) [0|255] ""  XGW_Info
 SG_ BAS_DiagReqData2 : 23|8@0+ (1,0) [0|255] ""  XGW_Info
 SG_ BAS_DiagReqData3 : 31|8@0+ (1,0) [0|255] ""  XGW_Info
 SG_ BAS_DiagReqData4 : 39|8@0+ (1,0) [0|255] ""  XGW_Info
 SG_ BAS_DiagReqData5 : 47|8@0+ (1,0) [0|255] ""  XGW_Info
 SG_ BAS_DiagReqData6 : 55|8@0+ (1,0) [0|255] ""  XGW_Info
 SG_ BAS_DiagReqData7 : 63|8@0+ (1,0) [0|255] ""  XGW_Info

BO_ 1764 DCM_APM_DiagReq: 8 MHU
  SG_ DCM_APM_DiagReqData0 : 7|8@0+ (1,0) [0|255] "-" XGW_Info
  SG_ DCM_APM_DiagReqData1 : 15|8@0+ (1,0) [0|255] "-" XGW_Info
  SG_ DCM_APM_DiagReqData2 : 23|8@0+ (1,0) [0|255] "-" XGW_Info
  SG_ DCM_APM_DiagReqData3 : 31|8@0+ (1,0) [0|255] "-" XGW_Info
  SG_ DCM_APM_DiagReqData4 : 39|8@0+ (1,0) [0|255] "" XGW_Info
  SG_ DCM_APM_DiagReqData5 : 47|8@0+ (1,0) [0|255] "" XGW_Info
  SG_ DCM_APM_DiagReqData6 : 55|8@0+ (1,0) [0|255] "" XGW_Info
  SG_ DCM_APM_DiagReqData7 : 63|8@0+ (1,0) [0|255] "" XGW_Info

BO_ 1774 MHU_FOTA_ReqAll: 8 MHU
  SG_ MHU_FOTA_ReqAll_00 : 7|8@0+ (1,0) [0|255] "-" XGW_Info
  SG_ MHU_FOTA_ReqAll_01 : 15|8@0+ (1,0) [0|255] "-" XGW_Info
  SG_ MHU_FOTA_ReqAll_02 : 23|8@0+ (1,0) [0|255] "-" XGW_Info
  SG_ MHU_FOTA_ReqAll_03 : 31|8@0+ (1,0) [0|255] "-" XGW_Info
  SG_ MHU_FOTA_ReqAll_04 : 39|8@0+ (1,0) [0|255] "-" XGW_Info
  SG_ MHU_FOTA_ReqAll_05 : 47|8@0+ (1,0) [0|255] "-" XGW_Info
  SG_ MHU_FOTA_ReqAll_06 : 55|8@0+ (1,0) [0|255] "-" XGW_Info
  SG_ MHU_FOTA_ReqAll_07 : 63|8@0+ (1,0) [0|255] "-" XGW_Info

BO_ 1775 DIAG_Req_All_CAN: 8 XGW_Info
  SG_ DiagReqAllCANData0 : 7|8@0+ (1,0) [0|255] "-" AMP,CPD,EASC,HUD,MHU
  SG_ DiagReqAllCANData1 : 15|8@0+ (1,0) [0|255] "" AMP,CPD,EASC,HUD,MHU
  SG_ DiagReqAllCANData2 : 23|8@0+ (1,0) [0|255] "-" AMP,CPD,EASC,HUD,MHU
  SG_ DiagReqAllCANData3 : 31|8@0+ (1,0) [0|255] "-" AMP,CPD,EASC,HUD,MHU
  SG_ DiagReqAllCANData4 : 39|8@0+ (1,0) [0|255] "" AMP,CPD,EASC,HUD,MHU
  SG_ DiagReqAllCANData5 : 47|8@0+ (1,0) [0|255] "" AMP,CPD,EASC,HUD,MHU
  SG_ DiagReqAllCANData6 : 55|8@0+ (1,0) [0|255] "" AMP,CPD,EASC,HUD,MHU
  SG_ DiagReqAllCANData7 : 63|8@0+ (1,0) [0|255] "" AMP,CPD,EASC,HUD,MHU

BO_ 1777 ASU_DiagReq: 8 MHU
  SG_ ASU_DiagReqData0 : 7|8@0+ (1,0) [0|255] "-" XGW_Info
  SG_ ASU_DiagReqData1 : 15|8@0+ (1,0) [0|255] "-" XGW_Info
  SG_ ASU_DiagReqData2 : 23|8@0+ (1,0) [0|255] "-" XGW_Info
  SG_ ASU_DiagReqData3 : 31|8@0+ (1,0) [0|255] "-" XGW_Info
  SG_ ASU_DiagReqData4 : 39|8@0+ (1,0) [0|255] "-" XGW_Info
  SG_ ASU_DiagReqData5 : 47|8@0+ (1,0) [0|255] "-" XGW_Info
  SG_ ASU_DiagReqData6 : 55|8@0+ (1,0) [0|255] "-" XGW_Info
  SG_ ASU_DiagReqData7 : 63|8@0+ (1,0) [0|255] "-" XGW_Info

BO_ 1787 BCM_BPM_DiagReq: 8 MHU
  SG_ BCM_BPM_DiagReqData0 : 7|8@0+ (1,0) [0|255] "-" XGW_Info
  SG_ BCM_BPM_DiagReqData1 : 15|8@0+ (1,0) [0|255] "" XGW_Info
  SG_ BCM_BPM_DiagReqData2 : 23|8@0+ (1,0) [0|255] "" XGW_Info
  SG_ BCM_BPM_DiagReqData3 : 31|8@0+ (1,0) [0|255] "" XGW_Info
  SG_ BCM_BPM_DiagReqData4 : 39|8@0+ (1,0) [0|255] "" XGW_Info
  SG_ BCM_BPM_DiagReqData5 : 47|8@0+ (1,0) [0|255] "" XGW_Info
  SG_ BCM_BPM_DiagReqData6 : 55|8@0+ (1,0) [0|255] "-" XGW_Info
  SG_ BCM_BPM_DiagReqData7 : 63|8@0+ (1,0) [0|255] "-" XGW_Info

BO_ 1791 DIAG_Req_All_Ecu: 8 XGW_Info
  SG_ DiagReqAllEcuData0 : 7|8@0+ (1,0) [0|255] "-" AMP,CPD,EASC,HUD,MHU
  SG_ DiagReqAllEcuData1 : 15|8@0+ (1,0) [0|255] "" AMP,CPD,EASC,HUD,MHU
  SG_ DiagReqAllEcuData2 : 23|8@0+ (1,0) [0|255] "" AMP,CPD,EASC,HUD,MHU
  SG_ DiagReqAllEcuData3 : 31|8@0+ (1,0) [0|255] "" AMP,CPD,EASC,HUD,MHU
  SG_ DiagReqAllEcuData4 : 39|8@0+ (1,0) [0|255] "-" AMP,CPD,EASC,HUD,MHU
  SG_ DiagReqAllEcuData5 : 47|8@0+ (1,0) [0|255] "" AMP,CPD,EASC,HUD,MHU
  SG_ DiagReqAllEcuData6 : 55|8@0+ (1,0) [0|255] "" AMP,CPD,EASC,HUD,MHU
  SG_ DiagReqAllEcuData7 : 63|8@0+ (1,0) [0|255] "" AMP,CPD,EASC,HUD,MHU

BO_ 1803 SEED_CAN_Req6_BCM: 8 XGW_Info
  SG_ SEED_CAN_Req6 : 7|64@0+ (1,0) [0|1.84467440737096E+019] "" MHU

BO_ 1805 SEED_CAN_Req7_VCU_PT: 8 XGW_Info
  SG_ SEED_CAN_Req7 : 7|64@0+ (1,0) [0|1.84467440737096E+019] "" MHU

BO_ 1833 SEED_CAN_Req16_ADAS_Info: 8 ADAS_Info
  SG_ SEED_CAN_Req16 : 7|64@0+ (1,0) [0|1.84467440737096E+019] "" MHU

BO_ 1841 SEED_CAN_Req17_HUD: 8 HUD
  SG_ SEED_CAN_Req17 : 7|64@0+ (1,0) [0|1.84467440737096E+019] "" MHU

BO_ 1843 SEED_CAN_Req18_MHU: 8 MHU
  SG_ SEED_CAN_Req18 : 7|64@0+ (1,0) [0|1.84467440737096E+019] "" ADAS_Info,EASC,HUD,XGW_Info

BO_ 1845 SEED_CAN_Req20_EASC: 8 EASC
  SG_ SEED_CAN_Req20 : 7|64@0+ (1,0) [0|1.84467440737096E+019] "" MHU

BO_ 1847 SEED_CAN_Req21_ETG: 8 XGW_Info
  SG_ SEED_CAN_Req21 : 7|64@0+ (1,0) [0|1.84467440737096E+019] "" MHU

BO_ 1873 VCU_DebugDiag: 8 XGW_Info
  SG_ VCU_DebugDiag2 : 4|3@0+ (1,0) [0|4] "" MHU
  SG_ VCU_DebugDiag1 : 7|3@0+ (1,0) [0|4] "" MHU
  SG_ VCU_DebugDiag5 : 9|3@0+ (1,0) [0|4] "" MHU
  SG_ VCU_DebugDiag4 : 12|3@0+ (1,0) [0|4] "" MHU
  SG_ VCU_DebugDiag3 : 15|3@0+ (1,0) [0|4] "" MHU
  SG_ VCU_DebugDiag8 : 16|3@0+ (1,0) [0|4] "" MHU
  SG_ VCU_DebugDiag7 : 19|3@0+ (1,0) [0|4] "" MHU
  SG_ VCU_DebugDiag6 : 22|3@0+ (1,0) [0|4] "" MHU
  SG_ VCU_DebugDiag10 : 26|3@0+ (1,0) [0|4] "" MHU
  SG_ VCU_DebugDiag9 : 29|3@0+ (1,0) [0|4] "" MHU
  SG_ VCU_DebugDiag13 : 33|3@0+ (1,0) [0|4] "" MHU
  SG_ VCU_DebugDiag12 : 36|3@0+ (1,0) [0|4] "" MHU
  SG_ VCU_DebugDiag11 : 39|3@0+ (1,0) [0|4] "" MHU
  SG_ VCU_DebugDiag16 : 40|3@0+ (1,0) [0|4] "" MHU
  SG_ VCU_DebugDiag15 : 43|3@0+ (1,0) [0|4] "" MHU
  SG_ VCU_DebugDiag14 : 46|3@0+ (1,0) [0|4] "" MHU
  SG_ VCU_DebugDiag18 : 50|3@0+ (1,0) [0|4] "" MHU
  SG_ VCU_DebugDiag17 : 53|3@0+ (1,0) [0|4] "" MHU
  SG_ VCU_DebugDiag20 : 60|3@0+ (1,0) [0|4] "" MHU
  SG_ VCU_DebugDiag19 : 63|3@0+ (1,0) [0|4] "" MHU

BO_ 2015 Diag_Request_ECU: 8 XGW_Info
  SG_ Diag_Request_ECU_Data0 : 7|8@0+ (1,0) [0|255] "" AMP,CPD,EASC,HUD,MHU
  SG_ Diag_Request_ECU_Data1 : 15|8@0+ (1,0) [0|255] "-" AMP,CPD,EASC,HUD,MHU
  SG_ Diag_Request_ECU_Data2 : 23|8@0+ (1,0) [0|255] "-" AMP,CPD,EASC,HUD,MHU
  SG_ Diag_Request_ECU_Data3 : 31|8@0+ (1,0) [0|255] "" AMP,CPD,EASC,HUD,MHU
  SG_ Diag_Request_ECU_Data4 : 39|8@0+ (1,0) [0|255] "-" AMP,CPD,EASC,HUD,MHU
  SG_ Diag_Request_ECU_Data5 : 47|8@0+ (1,0) [0|255] "" AMP,CPD,EASC,HUD,MHU
  SG_ Diag_Request_ECU_Data6 : 55|8@0+ (1,0) [0|255] "-" AMP,CPD,EASC,HUD,MHU
  SG_ Diag_Request_ECU_Data7 : 63|8@0+ (1,0) [0|255] "" AMP,CPD,EASC,HUD,MHU

BO_ 287 MHU_BCM_Ctrl: 8 MHU
 SG_ MHU_DrvInhibitSts : 13|2@0+ (1,0) [0|3] "" XGW_Info
 SG_ TBOX_AuthCode_0x11F : 55|16@0+ (1,0) [0|65535] "" XGW_Info

BO_ 280 BCM_MHU_Ctrl_Fbk: 8 XGW_Info
 SG_ CHKSM_BCM_MHU_Ctrl_Fbk : 7|8@0+ (1,0) [0|255] "" MHU
 SG_ ALV_BCM_MHU_Ctrl_Fbk : 11|4@0+ (1,0) [0|14] "" MHU
 SG_ BCM_DrvInhibitStsFbk : 13|2@0+ (1,0) [0|3] "" MHU

BO_ 772 ADAS_SM_Sts: 8 ADAS_Info
 SG_ CHKSM_ADAS_SM_Sts : 7|8@0+ (1,0) [0|255] "" MHU
 SG_ ALIVE_ADAS_SM_Sts : 11|4@0+ (1,0) [0|14] "" MHU
 SG_ SM_ReqInfoDispTxt3 : 18|3@0+ (1,0) [0|7] "" MHU
 SG_ SM_ReqInfoDispTxt2 : 31|5@0+ (1,0) [0|31] "" MHU
 SG_ SM_ReqInfoDispTxt1 : 23|5@0+ (1,0) [0|31] "" MHU
